VERSION ""

NS_ :

BS_:

BU_: VCM TBIOM RCIOM FCIOM CCIOM BPMU

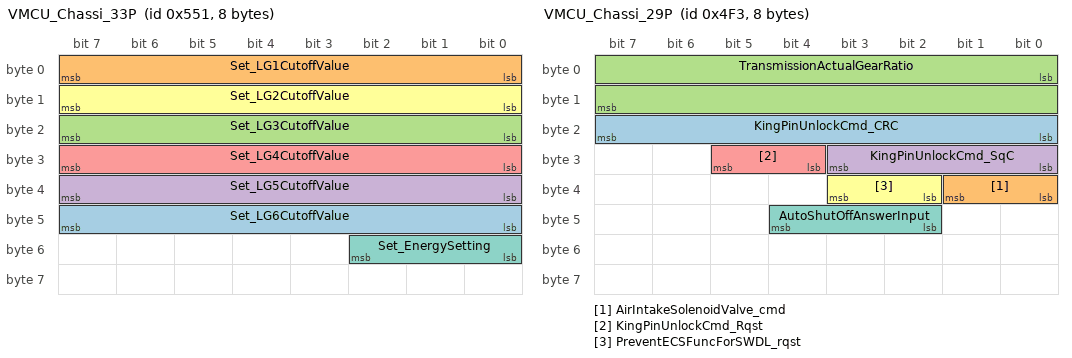
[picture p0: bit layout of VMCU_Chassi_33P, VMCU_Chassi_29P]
BO_ 1361 VMCU_Chassi_33P: 8 VCM
 SG_ Set_LG6CutoffValue : 40|8@1+ (1,0) [0|255] "Percent"  CCIOM
 SG_ Set_LG1CutoffValue : 0|8@1+ (1,0) [0|255] "Percent"  CCIOM
 SG_ Set_LG3CutoffValue : 16|8@1+ (1,0) [0|255] "Percent"  CCIOM
 SG_ Set_LG5CutoffValue : 32|8@1+ (1,0) [0|255] "Percent"  CCIOM
 SG_ Set_LG4CutoffValue : 24|8@1+ (1,0) [0|255] "Percent"  CCIOM
 SG_ Set_LG2CutoffValue : 8|8@1+ (1,0) [0|255] "Percent"  CCIOM
 SG_ Set_EnergySetting : 48|3@1+ (1,0) [0|0] ""  CCIOM

BO_ 1267 VMCU_Chassi_29P: 8 VCM
 SG_ KingPinUnlockCmd_CRC : 16|8@1+ (1,0) [0|255] ""  CCIOM
 SG_ AirIntakeSolenoidValve_cmd : 32|2@1+ (1,0) [0|0] ""  CCIOM
 SG_ TransmissionActualGearRatio : 0|16@1+ (0.001,0) [0|65.535] "NotApplicable"  RCIOM
 SG_ KingPinUnlockCmd_SqC : 24|4@1+ (1,0) [0|14] "NotApplicable"  CCIOM
 SG_ KingPinUnlockCmd_Rqst : 28|2@1+ (1,0) [0|0] ""  CCIOM
 SG_ PreventECSFuncForSWDL_rqst : 34|2@1+ (1,0) [0|0] ""  RCIOM
 SG_ AutoShutOffAnswerInput : 42|3@1+ (1,0) [0|0] ""  CCIOM

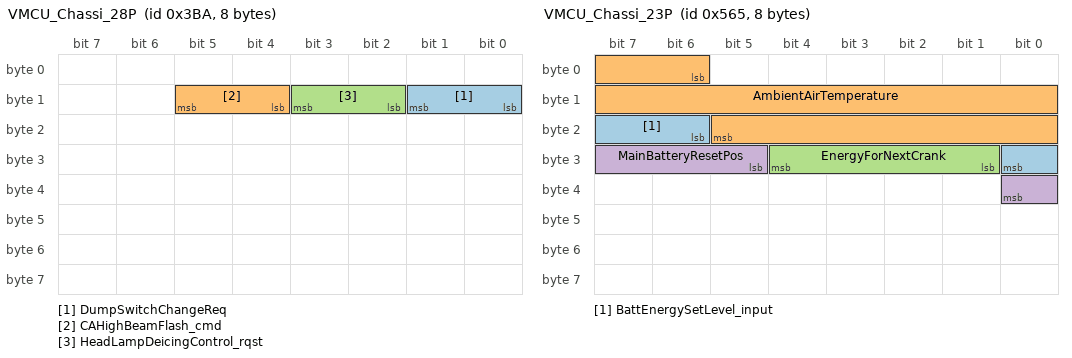
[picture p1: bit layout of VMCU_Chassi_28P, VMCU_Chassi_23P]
BO_ 954 VMCU_Chassi_28P: 8 VCM
 SG_ DumpSwitchChangeReq : 8|2@1+ (1,0) [0|0] ""  RCIOM
 SG_ CAHighBeamFlash_cmd : 12|2@1+ (1,0) [0|0] ""  FCIOM
 SG_ HeadLampDeicingControl_rqst : 10|2@1+ (1,0) [0|0] ""  FCIOM

BO_ 677 VMCU_Chassi_27P: 8 VCM
 SG_ EngineStarterMode : 0|4@1+ (1,0) [0|0] ""  CCIOM

BO_ 1363 VMCU_Chassi_26P: 8 VCM
 SG_ PredeliveryModeIndication_cmd : 56|2@1+ (1,0) [0|0] ""  CCIOM

BO_ 535 VMCU_Chassi_24P: 8 VCM
 SG_ DirectionIndicatorLightsStatus : 2|4@1+ (1,0) [0|0] ""  FCIOM,RCIOM
 SG_ HeadlightAngle_cmd : 56|8@1+ (0.025,-4) [-4|2.375] "deg"  FCIOM

BO_ 1381 VMCU_Chassi_23P: 8 VCM
 SG_ BattEnergySetLevel_input : 22|3@1+ (1,0) [0|0] ""  CCIOM
 SG_ AmbientAirTemperature : 6|16@1+ (0.03125,-273) [-273|1774.96875] "DegreeC"  FCIOM,BPMU,RCIOM,CCIOM
 SG_ EnergyForNextCrank : 25|4@1+ (1,0) [0|15] "Wh"  CCIOM
 SG_ MainBatteryResetPos : 29|4@1+ (1,0) [0|0] ""  CCIOM

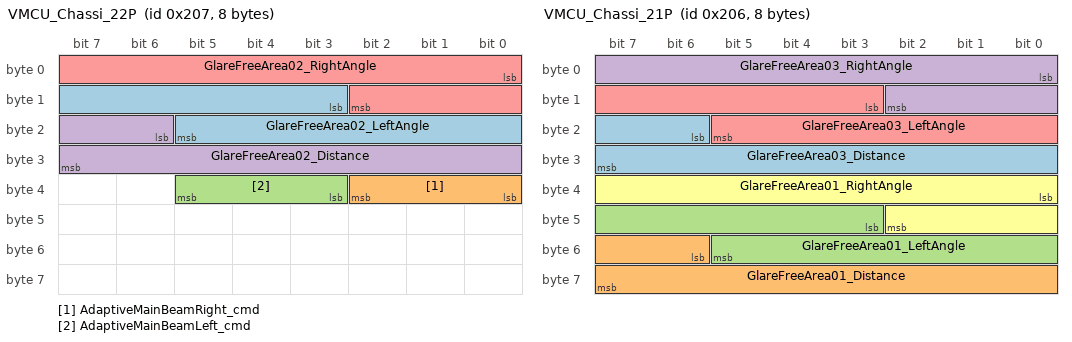
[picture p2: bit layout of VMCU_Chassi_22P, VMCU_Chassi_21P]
BO_ 519 VMCU_Chassi_22P: 8 VCM
 SG_ GlareFreeArea02_LeftAngle : 11|11@1+ (0.0494,-31.65) [-31.65|69.4718] "deg"  FCIOM
 SG_ AdaptiveMainBeamRight_cmd : 32|3@1+ (1,0) [0|0] ""  FCIOM
 SG_ AdaptiveMainBeamLeft_cmd : 35|3@1+ (1,0) [0|0] ""  FCIOM
 SG_ GlareFreeArea02_Distance : 22|10@1+ (0.5,0) [0|511.5] "m"  FCIOM
 SG_ GlareFreeArea02_RightAngle : 0|11@1+ (0.0494,-31.65) [-31.65|69.4718] "deg"  FCIOM

BO_ 518 VMCU_Chassi_21P: 8 VCM
 SG_ GlareFreeArea03_Distance : 22|10@1+ (0.5,0) [0|511.5] "m"  FCIOM
 SG_ GlareFreeArea01_Distance : 54|10@1+ (0.5,0) [0|511.5] "m"  FCIOM
 SG_ GlareFreeArea01_LeftAngle : 43|11@1+ (0.0494,-31.65) [-31.65|69.4718] "deg"  FCIOM
 SG_ GlareFreeArea03_RightAngle : 0|11@1+ (0.0494,-31.65) [-31.65|69.4718] "deg"  FCIOM
 SG_ GlareFreeArea03_LeftAngle : 11|11@1+ (0.0494,-31.65) [-31.65|69.4718] "deg"  FCIOM
 SG_ GlareFreeArea01_RightAngle : 32|11@1+ (0.0494,-31.65) [-31.65|69.4718] "deg"  FCIOM

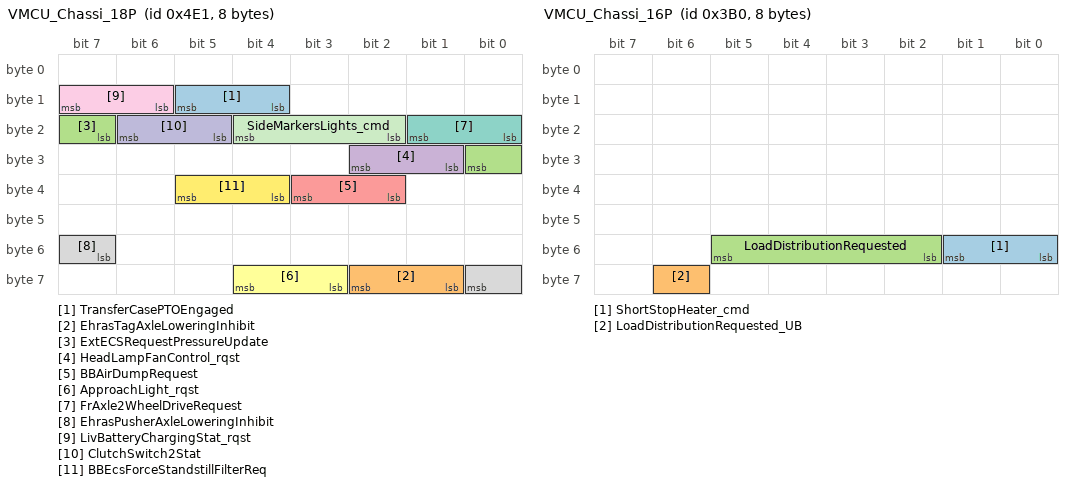
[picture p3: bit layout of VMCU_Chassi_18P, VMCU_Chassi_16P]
BO_ 1249 VMCU_Chassi_18P: 8 VCM
 SG_ TransferCasePTOEngaged : 12|2@1+ (1,0) [0|0] ""  RCIOM
 SG_ EhrasTagAxleLoweringInhibit : 57|2@1+ (1,0) [0|0] ""  RCIOM
 SG_ ExtECSRequestPressureUpdate : 23|2@1+ (1,0) [0|0] ""  RCIOM
 SG_ HeadLampFanControl_rqst : 25|2@1+ (1,0) [0|0] ""  FCIOM
 SG_ BBAirDumpRequest : 34|2@1+ (1,0) [0|0] ""  RCIOM
 SG_ ApproachLight_rqst : 59|2@1+ (1,0) [0|0] ""  RCIOM
 SG_ FrAxle2WheelDriveRequest : 16|2@1+ (1,0) [0|0] ""  CCIOM
 SG_ EhrasPusherAxleLoweringInhibit : 55|2@1+ (1,0) [0|0] ""  RCIOM
 SG_ LivBatteryChargingStat_rqst : 14|2@1+ (1,0) [0|0] ""  CCIOM
 SG_ ClutchSwitch2Stat : 21|2@1+ (1,0) [0|0] ""  CCIOM
 SG_ SideMarkersLights_cmd : 18|3@1+ (1,0) [0|0] ""  CCIOM
 SG_ BBEcsForceStandstillFilterReq : 36|2@1+ (1,0) [0|0] ""  RCIOM,CCIOM

BO_ 944 VMCU_Chassi_16P: 8 VCM
 SG_ ShortStopHeater_cmd : 48|2@1+ (1,0) [0|0] ""  CCIOM
 SG_ LoadDistributionRequested_UB : 62|1@1+ (1,0) [0|0] ""  RCIOM
 SG_ LoadDistributionRequested : 50|4@1+ (1,0) [0|0] ""  RCIOM

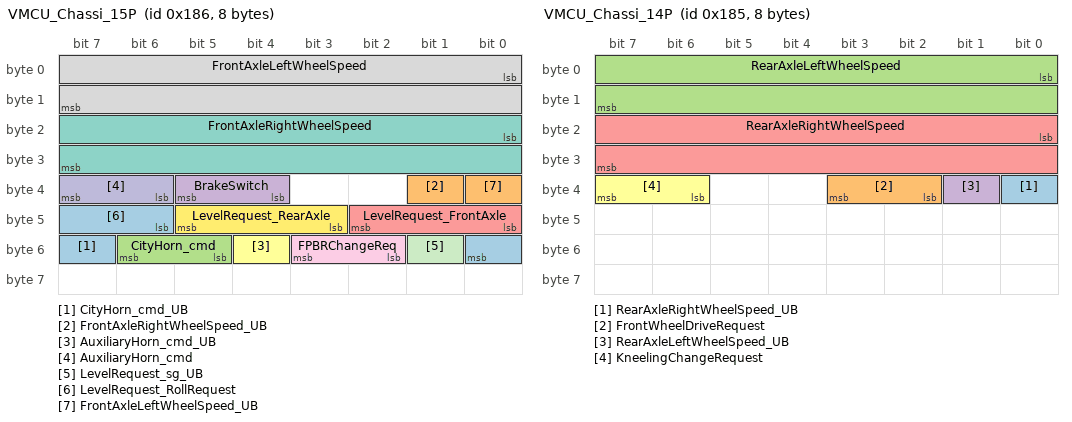
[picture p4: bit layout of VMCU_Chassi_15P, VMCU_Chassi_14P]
BO_ 390 VMCU_Chassi_15P: 8 VCM
 SG_ CityHorn_cmd_UB : 55|1@1+ (1,0) [0|0] ""  FCIOM
 SG_ FrontAxleRightWheelSpeed_UB : 33|1@1+ (1,0) [0|0] ""  CCIOM
 SG_ CityHorn_cmd : 53|2@1+ (1,0) [0|0] ""  FCIOM
 SG_ BrakeSwitch : 36|2@1+ (1,0) [0|0] ""  CCIOM
 SG_ LevelRequest_FrontAxle : 40|3@1+ (1,0) [0|0] ""  RCIOM
 SG_ AuxiliaryHorn_cmd_UB : 52|1@1+ (1,0) [0|0] ""  FCIOM
 SG_ FrontAxleRightWheelSpeed : 16|16@1+ (0.00390625,0) [0|255.99609375] "Km_per_h"  CCIOM
 SG_ FrontAxleLeftWheelSpeed : 0|16@1+ (0.00390625,0) [0|255.99609375] "Km_per_h"  CCIOM
 SG_ FPBRChangeReq : 50|2@1+ (1,0) [0|0] ""  RCIOM
 SG_ AuxiliaryHorn_cmd : 38|2@1+ (1,0) [0|0] ""  FCIOM
 SG_ LevelRequest_sg_UB : 49|1@1+ (1,0) [0|0] ""  RCIOM
 SG_ LevelRequest_RearAxle : 43|3@1+ (1,0) [0|0] ""  RCIOM
 SG_ LevelRequest_RollRequest : 46|3@1+ (1,0) [0|0] ""  RCIOM
 SG_ FrontAxleLeftWheelSpeed_UB : 32|1@1+ (1,0) [0|0] ""  CCIOM

BO_ 389 VMCU_Chassi_14P: 8 VCM
 SG_ RearAxleRightWheelSpeed_UB : 32|1@1+ (1,0) [0|0] ""  CCIOM,RCIOM
 SG_ FrontWheelDriveRequest : 34|2@1+ (1,0) [0|0] ""  CCIOM
 SG_ RearAxleLeftWheelSpeed : 0|16@1+ (0.00390625,0) [0|255.99609375] "Km_per_h"  RCIOM,CCIOM
 SG_ RearAxleLeftWheelSpeed_UB : 33|1@1+ (1,0) [0|0] ""  CCIOM,RCIOM
 SG_ RearAxleRightWheelSpeed : 16|16@1+ (0.00390625,0) [0|255.99609375] "Km_per_h"  RCIOM,CCIOM
 SG_ KneelingChangeRequest : 38|2@1+ (1,0) [0|0] ""  RCIOM

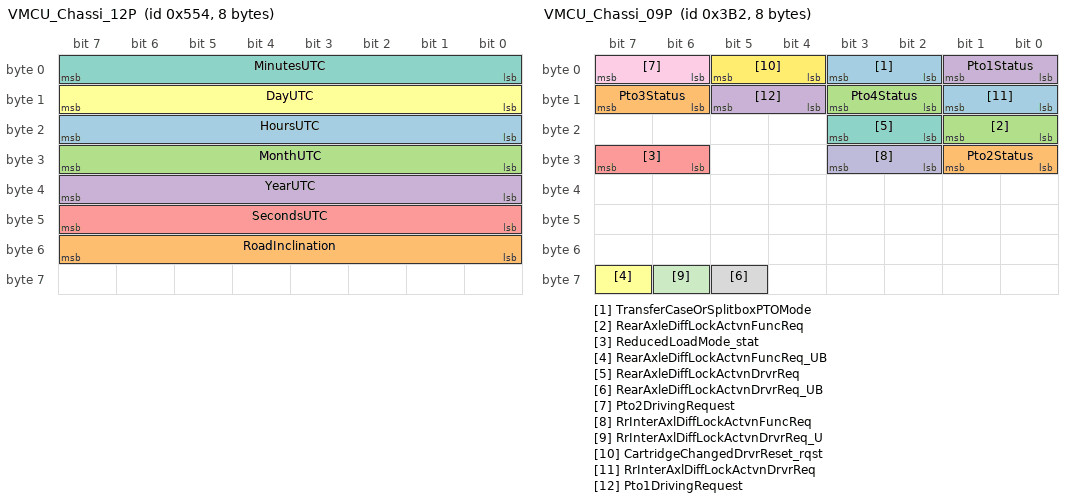
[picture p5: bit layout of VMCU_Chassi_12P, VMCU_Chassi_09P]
BO_ 1364 VMCU_Chassi_12P: 8 VCM
 SG_ HoursUTC : 16|8@1+ (1,0) [0|255] "h"  FCIOM,RCIOM,CCIOM,BPMU
 SG_ RoadInclination : 48|8@1+ (0.2,-25) [-25|26] "Percent"  RCIOM
 SG_ MonthUTC : 24|8@1+ (1,0) [0|255] "Months"  BPMU,RCIOM,FCIOM,CCIOM
 SG_ YearUTC : 32|8@1+ (1,1985) [1985|2240] "Years"  CCIOM,FCIOM,RCIOM,BPMU
 SG_ SecondsUTC : 40|8@1+ (0.25,0) [0|63.75] "s"  RCIOM,FCIOM,BPMU,CCIOM
 SG_ DayUTC : 8|8@1+ (0.25,0) [0|63.75] "Days"  RCIOM,CCIOM,FCIOM,BPMU
 SG_ MinutesUTC : 0|8@1+ (1,0) [0|255] "min"  BPMU,CCIOM,RCIOM,FCIOM

BO_ 826 VMCU_Chassi_11P: 8 VCM
 SG_ BBContUnlockCmd : 12|2@1+ (1,0) [0|0] ""  CCIOM
 SG_ LampCheck_cmd : 46|2@1+ (1,0) [0|0] ""  FCIOM
 SG_ LampCheck_rqst : 51|2@1+ (1,0) [0|0] ""  RCIOM
 SG_ BatteryCapacity : 16|4@1+ (1,0) [0|0] ""  CCIOM
 SG_ AreaInhibit : 10|2@1+ (1,0) [0|0] ""  CCIOM
 SG_ LEDAnimation_cmd : 53|3@1+ (1,0) [0|0] ""  FCIOM
 SG_ ActualDrvlnRetdrPercentTorque : 24|8@1+ (1,-125) [-125|130] "Percent"  RCIOM
 SG_ PloughLampModeStatus : 56|2@1+ (1,0) [0|0] ""  FCIOM
 SG_ RangeInhibit : 14|2@1+ (1,0) [0|0] ""  CCIOM
 SG_ TrailerBrakeNoEbs_stat : 22|2@1+ (1,0) [0|0] ""  RCIOM
 SG_ LiftAxle1DirectControl : 60|3@1+ (1,0) [0|0] ""  RCIOM
 SG_ DoorsAjar_stat : 43|3@1+ (1,0) [0|0] ""  CCIOM
 SG_ BlackOutandConvoyMode_rqst : 40|3@1+ (1,0) [0|0] ""  RCIOM,CCIOM
 SG_ DoorsAjar_stat_UB : 7|1@1+ (1,0) [0|0] ""  CCIOM
 SG_ LiftAxle1DirectControl_UB : 63|1@1+ (1,0) [0|0] ""  RCIOM
 SG_ ECSStandByRequest : 48|3@1+ (1,0) [0|0] ""  RCIOM
 SG_ ChassisInstepLight_cmd : 8|2@1+ (1,0) [0|0] ""  FCIOM
 SG_ BBSlidable5thWheelCmd : 1|2@1+ (1,0) [0|0] ""  CCIOM
 SG_ ParkingBrake_stat : 58|2@1+ (1,0) [0|0] ""  CCIOM
 SG_ MaintBatteryReset : 20|2@1+ (1,0) [0|0] ""  CCIOM

BO_ 1369 VMCU_Chassi_10P: 8 VCM
 SG_ TotalVehicleDistanceHighRes : 32|32@1+ (5,0) [0|21474836475] "m"  RCIOM,CCIOM,FCIOM,BPMU

BO_ 946 VMCU_Chassi_09P: 8 VCM
 SG_ TransferCaseOrSplitboxPTOMode : 2|2@1+ (1,0) [0|0] ""  RCIOM
 SG_ Pto3Status : 14|2@1+ (1,0) [0|0] ""  RCIOM
 SG_ RearAxleDiffLockActvnFuncReq : 16|2@1+ (1,0) [0|0] ""  RCIOM
 SG_ Pto1Status : 0|2@1+ (1,0) [0|0] ""  RCIOM
 SG_ ReducedLoadMode_stat : 30|2@1+ (1,0) [0|0] ""  CCIOM
 SG_ RearAxleDiffLockActvnFuncReq_UB : 63|1@1+ (1,0) [0|0] ""  RCIOM
 SG_ RearAxleDiffLockActvnDrvrReq : 18|2@1+ (1,0) [0|0] ""  RCIOM
 SG_ RearAxleDiffLockActvnDrvrReq_UB : 61|1@1+ (1,0) [0|0] ""  RCIOM
 SG_ Pto2DrivingRequest : 6|2@1+ (1,0) [0|0] ""  CCIOM
 SG_ RrInterAxlDiffLockActvnFuncReq : 26|2@1+ (1,0) [0|0] ""  RCIOM
 SG_ RrInterAxlDiffLockActvnDrvrReq_U : 62|1@1+ (1,0) [0|0] ""  RCIOM
 SG_ CartridgeChangedDrvrReset_rqst : 4|2@1+ (1,0) [0|0] ""  CCIOM
 SG_ RrInterAxlDiffLockActvnDrvrReq : 8|2@1+ (1,0) [0|0] ""  RCIOM
 SG_ Pto2Status : 24|2@1+ (1,0) [0|0] ""  RCIOM
 SG_ Pto4Status : 10|2@1+ (1,0) [0|0] ""  RCIOM
 SG_ Pto1DrivingRequest : 12|2@1+ (1,0) [0|0] ""  CCIOM

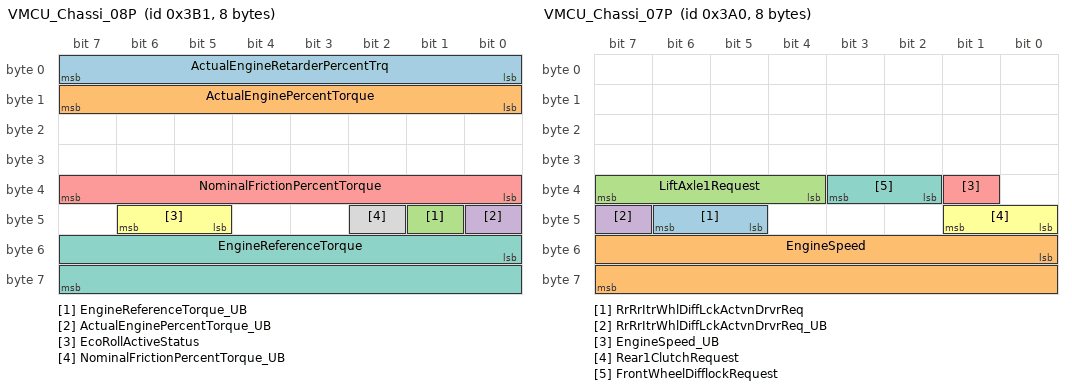
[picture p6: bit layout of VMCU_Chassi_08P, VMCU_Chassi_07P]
BO_ 945 VMCU_Chassi_08P: 8 VCM
 SG_ ActualEngineRetarderPercentTrq : 0|8@1+ (1,-125) [-125|130] "Percent"  RCIOM
 SG_ ActualEnginePercentTorque : 8|8@1+ (1,-125) [-125|130] "Percent"  CCIOM,RCIOM
 SG_ EngineReferenceTorque_UB : 41|1@1+ (1,0) [0|0] ""  RCIOM
 SG_ ActualEnginePercentTorque_UB : 40|1@1+ (1,0) [0|0] ""  RCIOM,CCIOM
 SG_ NominalFrictionPercentTorque : 32|8@1+ (1,-125) [-125|130] "Percent"  RCIOM
 SG_ EcoRollActiveStatus : 45|2@1+ (1,0) [0|0] ""  CCIOM
 SG_ EngineReferenceTorque : 48|16@1+ (1,0) [0|65535] "Nm"  RCIOM
 SG_ NominalFrictionPercentTorque_UB : 42|1@1+ (1,0) [0|0] ""  RCIOM

BO_ 928 VMCU_Chassi_07P: 8 VCM
 SG_ RrRrItrWhlDiffLckActvnDrvrReq : 45|2@1+ (1,0) [0|0] ""  RCIOM
 SG_ EngineSpeed : 48|16@1+ (0.125,0) [0|8191.875] "rpm"  CCIOM
 SG_ LiftAxle1Request : 36|4@1+ (1,0) [0|0] ""  RCIOM
 SG_ RrRrItrWhlDiffLckActvnDrvrReq_UB : 47|1@1+ (1,0) [0|0] ""  RCIOM
 SG_ EngineSpeed_UB : 33|1@1+ (1,0) [0|0] ""  CCIOM
 SG_ Rear1ClutchRequest : 40|2@1+ (1,0) [0|0] ""  RCIOM
 SG_ FrontWheelDifflockRequest : 34|2@1+ (1,0) [0|0] ""  CCIOM

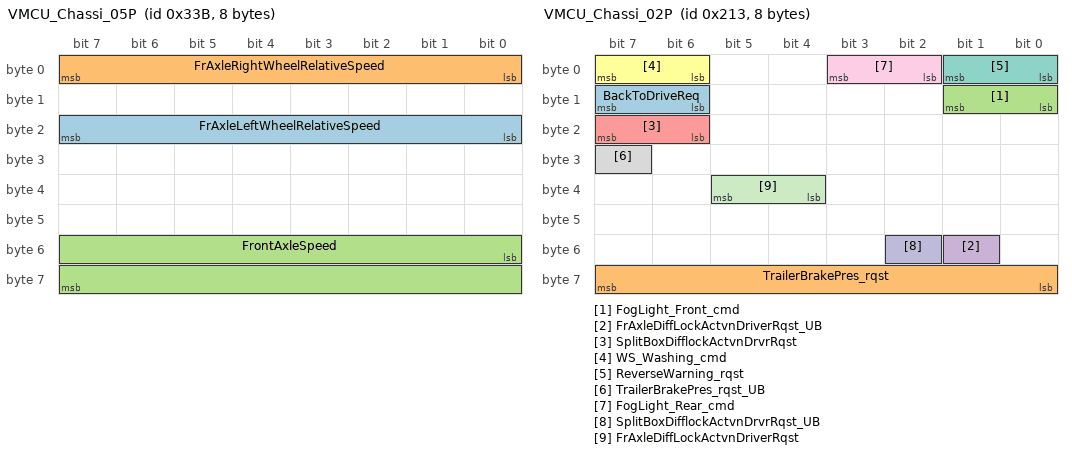
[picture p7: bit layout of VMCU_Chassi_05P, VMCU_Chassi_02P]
BO_ 827 VMCU_Chassi_05P: 8 VCM
 SG_ FrAxleLeftWheelRelativeSpeed : 16|8@1+ (0.0625,-7.8125) [-7.8125|8.125] "Km_per_h"  RCIOM
 SG_ FrAxleRightWheelRelativeSpeed : 0|8@1+ (0.0625,-7.8125) [-7.8125|8.125] "Km_per_h"  RCIOM
 SG_ FrontAxleSpeed : 48|16@1+ (0.00390625,0) [0|255.99609375] "Km_per_h"  RCIOM,CCIOM

BO_ 537 VMCU_Chassi_04P: 8 VCM
 SG_ LiftAxle2LiftPositionRequest : 43|3@1+ (1,0) [0|0] ""  RCIOM
 SG_ LoadDistributionChangeRequest : 48|2@1+ (1,0) [0|0] ""  RCIOM
 SG_ AltLoadDistribution_rqst : 56|3@1+ (1,0) [0|0] ""  RCIOM
 SG_ LiftAxle1LiftPositionRequest : 36|3@1+ (1,0) [0|0] ""  RCIOM
 SG_ FerryFunctionRequest_UB : 10|1@1+ (1,0) [0|0] ""  RCIOM
 SG_ RampLevelRequest : 0|4@1+ (1,0) [0|0] ""  RCIOM
 SG_ RampLevelStorageRequest : 16|4@1+ (1,0) [0|0] ""  RCIOM
 SG_ RideHeightFunctionRequest : 12|4@1+ (1,0) [0|0] ""  RCIOM
 SG_ LiftAxle1AutoLiftRequest : 34|2@1+ (1,0) [0|0] ""  RCIOM
 SG_ FerryFunctionRequest : 28|2@1+ (1,0) [0|0] ""  RCIOM
 SG_ AltLoadDistribution_rqst_UB : 54|1@1+ (1,0) [0|0] ""  RCIOM
 SG_ BBSystemKneelRequest : 8|2@1+ (1,0) [0|0] ""  RCIOM
 SG_ StopLevelChangeRequest : 24|2@1+ (1,0) [0|0] ""  RCIOM
 SG_ LiftAxle1LiftPositionRequest_UB : 39|1@1+ (1,0) [0|0] ""  RCIOM
 SG_ LiftAxle2LiftPositionRequest_UB : 46|1@1+ (1,0) [0|0] ""  RCIOM
 SG_ FirstAxleLowerPrioRequested : 50|3@1+ (1,0) [0|0] ""  RCIOM
 SG_ LiftAxle1AutoLiftRequest_UB : 23|1@1+ (1,0) [0|0] ""  RCIOM
 SG_ LiftAxle2AutoLiftRequest : 40|2@1+ (1,0) [0|0] ""  RCIOM
 SG_ LiftAxle2AutoLiftRequest_UB : 42|1@1+ (1,0) [0|0] ""  RCIOM
 SG_ FerryFunctionSwitchChangeReq : 61|2@1+ (1,0) [0|0] ""  RCIOM
 SG_ LevelStrokeRequest : 32|2@1+ (1,0) [0|0] ""  RCIOM
 SG_ BBSystemAlternatLoadDistribReq_U : 55|1@1+ (1,0) [0|0] ""  RCIOM
 SG_ RideHeightFunctionRequest_UB : 63|1@1+ (1,0) [0|0] ""  RCIOM
 SG_ FirstAxleLowerPrioRequested_UB : 53|1@1+ (1,0) [0|0] ""  RCIOM
 SG_ BBSystemProhibitControlRequest : 30|2@1+ (1,0) [0|0] ""  RCIOM
 SG_ LoadDistributionChangeRequest_UB : 47|1@1+ (1,0) [0|0] ""  RCIOM
 SG_ BBSystemAlternatLoadDistribReq : 59|2@1+ (1,0) [0|0] ""  RCIOM
 SG_ RideHeightStorageRequest : 4|4@1+ (1,0) [0|0] ""  RCIOM
 SG_ BBSystemSpeedDepDriveLevelReq : 26|2@1+ (1,0) [0|0] ""  RCIOM

BO_ 531 VMCU_Chassi_02P: 8 VCM
 SG_ BackToDriveReq : 14|2@1+ (1,0) [0|0] ""  RCIOM
 SG_ TrailerBrakePres_rqst : 56|8@1+ (8,0) [0|2040] "kPa"  CCIOM
 SG_ FogLight_Front_cmd : 8|2@1+ (1,0) [0|0] ""  FCIOM
 SG_ FrAxleDiffLockActvnDriverRqst_UB : 49|1@1+ (1,0) [0|0] ""  CCIOM
 SG_ SplitBoxDifflockActvnDrvrRqst : 22|2@1+ (1,0) [0|0] ""  CCIOM
 SG_ WS_Washing_cmd : 6|2@1+ (1,0) [0|0] ""  FCIOM
 SG_ ReverseWarning_rqst : 0|2@1+ (1,0) [0|0] ""  RCIOM
 SG_ TrailerBrakePres_rqst_UB : 31|1@1+ (1,0) [0|0] ""  CCIOM
 SG_ FogLight_Rear_cmd : 2|2@1+ (1,0) [0|0] ""  RCIOM,CCIOM
 SG_ SplitBoxDifflockActvnDrvrRqst_UB : 50|1@1+ (1,0) [0|0] ""  CCIOM
 SG_ FrAxleDiffLockActvnDriverRqst : 36|2@1+ (1,0) [0|0] ""  CCIOM

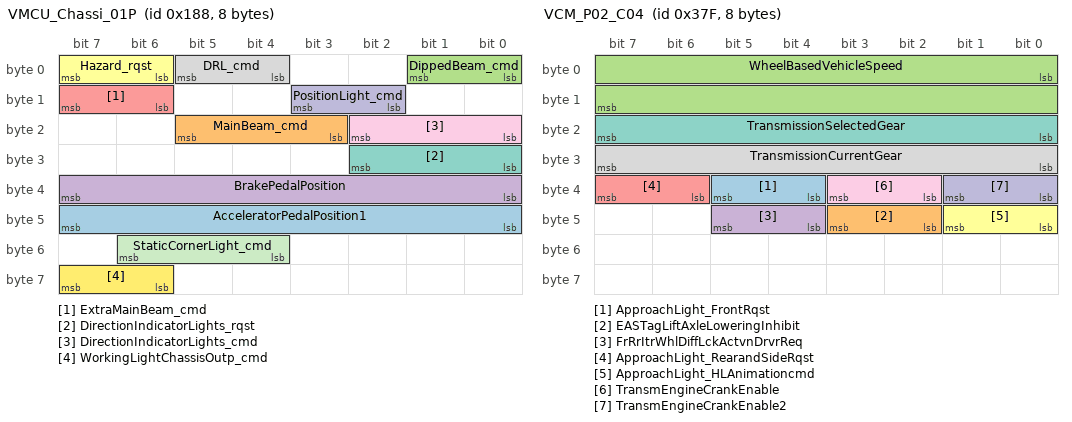
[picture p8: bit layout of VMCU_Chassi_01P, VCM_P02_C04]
BO_ 392 VMCU_Chassi_01P: 8 VCM
 SG_ AcceleratorPedalPosition1 : 40|8@1+ (0.4,0) [0|102] "Percent"  RCIOM,CCIOM
 SG_ MainBeam_cmd : 19|3@1+ (1,0) [0|0] ""  FCIOM,RCIOM
 SG_ DippedBeam_cmd : 0|2@1+ (1,0) [0|0] ""  FCIOM,RCIOM
 SG_ BrakePedalPosition : 32|8@1+ (0.4,0) [0|102] "Percent"  RCIOM,CCIOM
 SG_ ExtraMainBeam_cmd : 14|2@1+ (1,0) [0|0] ""  FCIOM
 SG_ Hazard_rqst : 6|2@1+ (1,0) [0|0] ""  FCIOM
 SG_ DirectionIndicatorLights_rqst : 24|3@1+ (1,0) [0|0] ""  FCIOM
 SG_ DRL_cmd : 4|2@1+ (1,0) [0|0] ""  FCIOM,RCIOM
 SG_ DirectionIndicatorLights_cmd : 16|3@1+ (1,0) [0|0] ""  FCIOM,RCIOM,CCIOM
 SG_ PositionLight_cmd : 10|2@1+ (1,0) [0|0] ""  FCIOM,RCIOM
 SG_ StaticCornerLight_cmd : 52|3@1+ (1,0) [0|0] ""  FCIOM
 SG_ WorkingLightChassisOutp_cmd : 62|2@1+ (1,0) [0|0] ""  CCIOM

BO_ 895 VCM_P02_C04: 8 VCM
 SG_ ApproachLight_FrontRqst : 36|2@1+ (1,0) [0|0] ""  FCIOM
 SG_ EASTagLiftAxleLoweringInhibit : 42|2@1+ (1,0) [0|0] ""  RCIOM
 SG_ WheelBasedVehicleSpeed : 0|16@1+ (0.00390625,0) [0|255.99609375] "Km_per_h"  RCIOM,CCIOM
 SG_ FrRrItrWhlDiffLckActvnDrvrReq : 44|2@1+ (1,0) [0|0] ""  RCIOM
 SG_ ApproachLight_RearandSideRqst : 38|2@1+ (1,0) [0|0] ""  RCIOM
 SG_ ApproachLight_HLAnimationcmd : 40|2@1+ (1,0) [0|0] ""  FCIOM
 SG_ TransmissionSelectedGear : 16|8@1+ (1,-125) [-125|130] "GearValue"  CCIOM
 SG_ TransmissionCurrentGear : 24|8@1+ (1,-125) [-125|130] "GearValue"  CCIOM
 SG_ TransmEngineCrankEnable : 34|2@1+ (1,0) [0|0] ""  CCIOM
 SG_ TransmEngineCrankEnable2 : 32|2@1+ (1,0) [0|0] ""  CCIOM

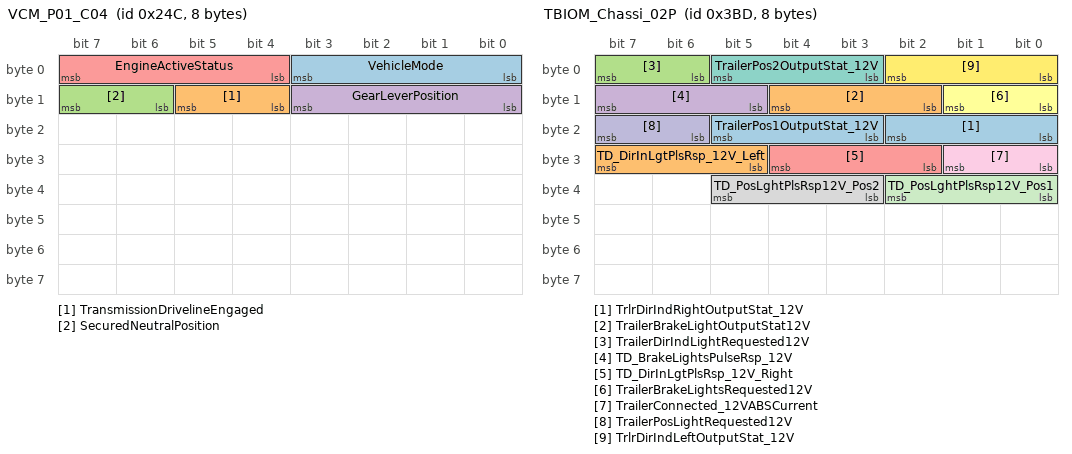
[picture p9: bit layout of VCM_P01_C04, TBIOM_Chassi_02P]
BO_ 588 VCM_P01_C04: 8 VCM
 SG_ VehicleMode : 0|4@1+ (1,0) [0|0] ""  CCIOM,BPMU,TBIOM,FCIOM,RCIOM
 SG_ TransmissionDrivelineEngaged : 12|2@1+ (1,0) [0|0] ""  CCIOM
 SG_ SecuredNeutralPosition : 14|2@1+ (1,0) [0|0] ""  CCIOM
 SG_ GearLeverPosition : 8|4@1+ (1,0) [0|0] ""  CCIOM
 SG_ EngineActiveStatus : 4|4@1+ (1,0) [0|0] ""  CCIOM

BO_ 2671902706 TesterFuncDiagMsg_C04: 8 VCM
 SG_ FuncDiagDataTester : 0|64@1+ (1,0) [0|0] ""  TBIOM,RCIOM,FCIOM,CCIOM,BPMU

BO_ 2671902708 TesterFuncDiagMsgF4_C04: 8 VCM
 SG_ FuncDiagDataIntTesterF4 : 0|64@1+ (1,0) [0|0] ""  FCIOM,BPMU,RCIOM,CCIOM,TBIOM

BO_ 957 TBIOM_Chassi_02P: 8 VCM
 SG_ TrlrDirIndRightOutputStat_12V : 16|3@1+ (1,0) [0|0] ""  RCIOM
 SG_ TrailerBrakeLightOutputStat12V : 10|3@1+ (1,0) [0|0] ""  RCIOM
 SG_ TrailerDirIndLightRequested12V : 6|2@1+ (1,0) [0|0] ""  RCIOM
 SG_ TD_BrakeLightsPulseRsp_12V : 13|3@1+ (1,0) [0|0] ""  RCIOM
 SG_ TD_DirInLgtPlsRsp_12V_Right : 26|3@1+ (1,0) [0|0] ""  RCIOM
 SG_ TrailerBrakeLightsRequested12V : 8|2@1+ (1,0) [0|0] ""  RCIOM
 SG_ TrailerPos2OutputStat_12V : 3|3@1+ (1,0) [0|0] ""  RCIOM
 SG_ TD_PosLghtPlsRsp12V_Pos2 : 35|3@1+ (1,0) [0|0] ""  RCIOM
 SG_ TrailerConnected_12VABSCurrent : 24|2@1+ (1,0) [0|0] ""  RCIOM
 SG_ TrailerPosLightRequested12V : 22|2@1+ (1,0) [0|0] ""  RCIOM
 SG_ TD_PosLghtPlsRsp12V_Pos1 : 32|3@1+ (1,0) [0|0] ""  RCIOM
 SG_ TrlrDirIndLeftOutputStat_12V : 0|3@1+ (1,0) [0|0] ""  RCIOM
 SG_ TrailerPos1OutputStat_12V : 19|3@1+ (1,0) [0|0] ""  RCIOM
 SG_ TD_DirInLgtPlsRsp_12V_Left : 29|3@1+ (1,0) [0|0] ""  RCIOM

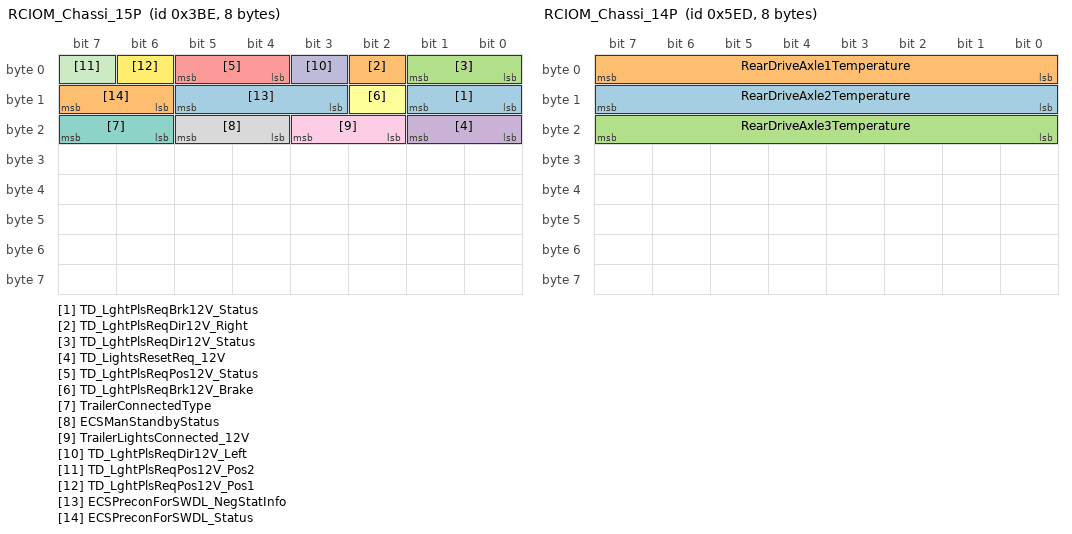
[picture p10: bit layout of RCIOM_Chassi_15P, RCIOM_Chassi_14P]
BO_ 958 RCIOM_Chassi_15P: 8 RCIOM
 SG_ TD_LghtPlsReqBrk12V_Status : 8|2@1+ (1,0) [0|0] ""  VCM
 SG_ TD_LghtPlsReqDir12V_Right : 2|1@1+ (1,0) [0|0] ""  VCM
 SG_ TD_LghtPlsReqDir12V_Status : 0|2@1+ (1,0) [0|0] ""  VCM
 SG_ TD_LightsResetReq_12V : 16|2@1+ (1,0) [0|0] ""  VCM
 SG_ TD_LghtPlsReqPos12V_Status : 4|2@1+ (1,0) [0|0] ""  VCM
 SG_ TD_LghtPlsReqBrk12V_Brake : 10|1@1+ (1,0) [0|0] ""  VCM
 SG_ TrailerConnectedType : 22|2@1+ (1,0) [0|0] ""  VCM,CCIOM
 SG_ ECSManStandbyStatus : 20|2@1+ (1,0) [0|0] ""  VCM
 SG_ TrailerLightsConnected_12V : 18|2@1+ (1,0) [0|0] ""  VCM
 SG_ TD_LghtPlsReqDir12V_Left : 3|1@1+ (1,0) [0|0] ""  VCM
 SG_ TD_LghtPlsReqPos12V_Pos2 : 7|1@1+ (1,0) [0|0] ""  VCM
 SG_ TD_LghtPlsReqPos12V_Pos1 : 6|1@1+ (1,0) [0|0] ""  VCM
 SG_ ECSPreconForSWDL_NegStatInfo : 11|3@1+ (1,0) [0|0] ""  VCM
 SG_ ECSPreconForSWDL_Status : 14|2@1+ (1,0) [0|0] ""  VCM

BO_ 1517 RCIOM_Chassi_14P: 8 RCIOM
 SG_ RearDriveAxle2Temperature : 8|8@1+ (1,0) [0|255] "DegreeC"  VCM
 SG_ RearDriveAxle1Temperature : 0|8@1+ (1,0) [0|255] "DegreeC"  VCM
 SG_ RearDriveAxle3Temperature : 16|8@1+ (1,0) [0|255] "DegreeC"  VCM

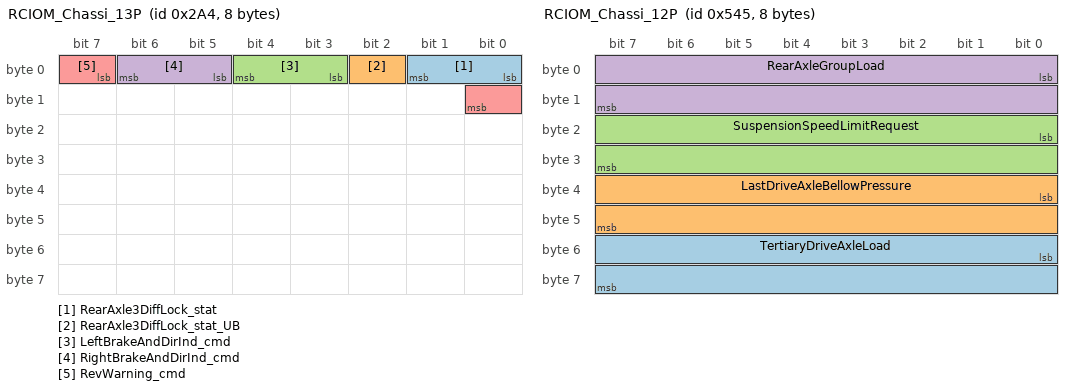
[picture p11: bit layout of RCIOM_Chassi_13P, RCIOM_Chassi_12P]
BO_ 676 RCIOM_Chassi_13P: 8 RCIOM
 SG_ RearAxle3DiffLock_stat : 0|2@1+ (1,0) [0|0] ""  VCM
 SG_ RearAxle3DiffLock_stat_UB : 2|1@1+ (1,0) [0|0] ""  VCM
 SG_ LeftBrakeAndDirInd_cmd : 3|2@1+ (1,0) [0|0] ""  VCM
 SG_ RightBrakeAndDirInd_cmd : 5|2@1+ (1,0) [0|0] ""  VCM
 SG_ RevWarning_cmd : 7|2@1+ (1,0) [0|0] ""  VCM

BO_ 1349 RCIOM_Chassi_12P: 8 RCIOM
 SG_ TertiaryDriveAxleLoad : 48|16@1+ (0.5,0) [0|32767.5] "kg"  VCM
 SG_ LastDriveAxleBellowPressure : 32|16@1+ (0.1,0) [0|6553.5] "kPa"  VCM
 SG_ SuspensionSpeedLimitRequest : 16|16@1+ (0.00390625,0) [0|255.99609375] "Km_per_h"  VCM
 SG_ RearAxleGroupLoad : 0|16@1+ (2,0) [0|131070] "kg"  VCM

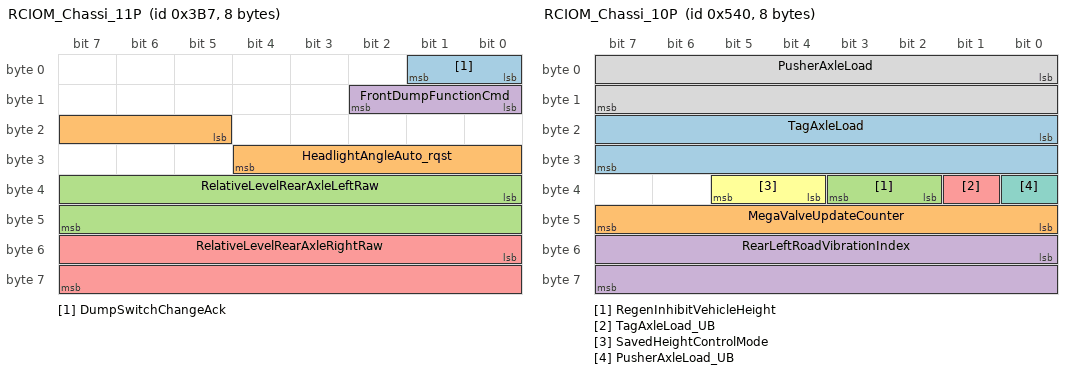
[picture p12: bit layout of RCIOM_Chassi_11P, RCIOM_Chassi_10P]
BO_ 951 RCIOM_Chassi_11P: 8 RCIOM
 SG_ DumpSwitchChangeAck : 0|2@1+ (1,0) [0|0] ""  VCM
 SG_ HeadlightAngleAuto_rqst : 21|8@1+ (0.025,-4) [-4|2.375] "deg"  VCM
 SG_ RelativeLevelRearAxleLeftRaw : 32|16@1+ (0.1,-3200) [-3200|3353.5] "mm"  VCM
 SG_ FrontDumpFunctionCmd : 8|3@1+ (1,0) [0|0] ""  VCM,CCIOM
 SG_ RelativeLevelRearAxleRightRaw : 48|16@1+ (0.1,-3200) [-3200|3353.5] "mm"  VCM

BO_ 1344 RCIOM_Chassi_10P: 8 RCIOM
 SG_ TagAxleLoad : 16|16@1+ (0.5,0) [0|32767.5] "kg"  VCM
 SG_ MegaValveUpdateCounter : 40|8@1+ (1,0) [0|255] "Count"  VCM
 SG_ RegenInhibitVehicleHeight : 34|2@1+ (1,0) [0|0] ""  VCM
 SG_ RearLeftRoadVibrationIndex : 48|16@1+ (0.01,0) [0|655.35] ""  VCM
 SG_ TagAxleLoad_UB : 33|1@1+ (1,0) [0|0] ""  VCM
 SG_ SavedHeightControlMode : 36|2@1+ (1,0) [0|0] ""  VCM
 SG_ PusherAxleLoad_UB : 32|1@1+ (1,0) [0|0] ""  VCM
 SG_ PusherAxleLoad : 0|16@1+ (0.5,0) [0|32767.5] "kg"  VCM

CM_ "COM_MATRIX_T3_1.9.0";
CM_ BU_ VCM "Vehicle Control Module";
CM_ BU_ TBIOM "Trailer Body Input Output Module";
CM_ BU_ RCIOM "Rear Chassis Input Output Module";
CM_ BU_ FCIOM "Front Chassis Input Output Module";
CM_ BU_ CCIOM "Center Chassis Input Output Module";
CM_ BU_ BPMU "Battery Power Management Unit";
CM_ BO_ 519 "Sporadic defined on this net, but periodic in reality since triggered every 20ms due to cyclic on BB2";
CM_ BO_ 518 "Sporadic defined on this net, but periodic in reality since triggered every 20ms due to cyclic on BB2";
CM_ BO_ 827 "This is a sporadic message but this message comes periodically because all signal in the message are gatewayed signals from BB1 and they are periodical there. If there is no traffic on BB1 this message is not sent on Chassi network.";
BA_DEF_ BO_  "GenMsgStartDelayTime" INT 0 0;
BA_DEF_ BO_  "GenMsgDelayTime" INT 0 0;
BA_DEF_ BO_  "GenMsgCycleTime" INT 0 0;
BA_DEF_ BO_  "GenMsgSendType" ENUM  "Cyclic","NotUsed","NotUsed","NotUsed","NotUsed","NotUsed","NotUsed","IfActive","NoMsgSendType","NotUsed";
BA_DEF_ SG_  "GenSigStartValue" INT 0 0;
BA_DEF_ SG_  "GenSigInactiveValue" INT 0 0;
BA_DEF_ SG_  "GenSigCycleTimeActive" INT 0 0;
BA_DEF_ SG_  "GenSigCycleTime" INT 0 0;
BA_DEF_ SG_  "GenSigSendType" ENUM  "Cyclic","OnWrite","OnWriteWithRepetition","OnChange","OnChangeWithRepetition","IfActive","IfActiveWithRepetition","NoSigSendType","NotUsed","NotUsed","NotUsed","NotUsed","NotUsed";
BA_DEF_  "Baudrate" INT 0 1000000;
BA_DEF_  "NmType" STRING ;
BA_DEF_  "Manufacturer" STRING ;
BA_DEF_  "VersionYear" INT 0 99;
BA_DEF_  "VersionNumber" INT 0 99;
BA_DEF_  "VersionMonth" INT 1 12;
BA_DEF_  "VersionDay" INT 1 31;
BA_DEF_ BO_  "VFrameFormat" ENUM  "StandardCAN","ExtendedCAN","reserved","J1939PG","reserved","reserved","reserved","reserved","reserved","reserved","reserved","reserved","reserved","reserved","StandardCAN_FD","ExtendedCAN_FD";
BA_DEF_ BU_  "TpOwnSystemEcuNumber" HEX 0 255;
BA_DEF_ SG_  "SigType" ENUM  "Default","Range","RangeSigned","ASCII","Discrete","Control","ReferencePGN","DTC","StringDelimiter","StringLength","StringLengthControl";
BA_DEF_ SG_  "Platform_Vivis2_Sig" ENUM  "No","Yes";
BA_DEF_ SG_  "Platform_VMCU1_Sig" ENUM  "No","Yes";
BA_DEF_ BU_  "NmStationAddress" INT 0 255;
BA_DEF_  "NmAsrWaitBusSleepTime" INT 0 65535;
BA_DEF_  "NmAsrTimeoutTime" INT 0 65535;
BA_DEF_  "NmAsrRepeatMessageTime" INT 0 65535;
BA_DEF_ BU_  "NmAsrNodeIdentifier" HEX 0 253;
BA_DEF_ BU_  "NmAsrNode" ENUM  "No","Yes";
BA_DEF_  "NmAsrMessageCount" INT 1 256;
BA_DEF_ BO_  "NmAsrMessage" ENUM  "No","Yes";
BA_DEF_  "NmAsrCanMsgCycleTime" INT 0 65535;
BA_DEF_  "NmAsrBaseAddress" HEX 0 536870911;
BA_DEF_ SG_  "NeedsUpdateBit" ENUM  "No","Yes";
BA_DEF_ SG_  "MmAnSignal" ENUM  "No","Yes";
BA_DEF_ BU_  "IsOBDrelevant" ENUM  "No","Yes";
BA_DEF_ SG_  "GenSigMaxLatency" INT 0 65535;
BA_DEF_ SG_  "GenSigILSupport" ENUM  "Yes","No";
BA_DEF_ BO_  "GenMsgILSupport" ENUM  "No","Yes";
BA_DEF_ SG_  "E2EProfile" STRING ;
BA_DEF_  "E2EP05WindowSize" INT 0 65535;
BA_DEF_  "E2EP05ProfileName" STRING ;
BA_DEF_  "E2EP05MinOkStateValid" INT 0 65535;
BA_DEF_  "E2EP05MinOkStateInvalid" INT 0 65535;
BA_DEF_  "E2EP05MinOkStateInit" INT 0 65535;
BA_DEF_  "E2EP05MaxErrorStateValid" INT 0 65535;
BA_DEF_  "E2EP05MaxErrorStateInvalid" INT 0 65535;
BA_DEF_  "E2EP05MaxErrorStateInit" INT 0 65535;
BA_DEF_  "E2EP05MaxDeltaCounter" INT 0 65535;
BA_DEF_  "E2EP01WindowSize" INT 0 65535;
BA_DEF_  "E2EP01SyncCounterInit" INT 0 65535;
BA_DEF_  "E2EP01ProfileName" STRING ;
BA_DEF_  "E2EP01MinOkStateValid" INT 0 65535;
BA_DEF_  "E2EP01MinOkStateInvalid" INT 0 65535;
BA_DEF_  "E2EP01MinOkStateInit" INT 0 65535;
BA_DEF_  "E2EP01MaxNoNewOrRepeatedData" INT 0 65535;
BA_DEF_  "E2EP01MaxErrorStateValid" INT 0 65535;
BA_DEF_  "E2EP01MaxErrorStateInvalid" INT 0 65535;
BA_DEF_  "E2EP01MaxErrorStateInit" INT 0 65535;
BA_DEF_  "E2EP01MaxDeltaCounter" INT 0 65535;
BA_DEF_  "E2EP01DataIdMode" ENUM  "all16Bit","alternating8Bit","lower12Bit","lower8Bit";
BA_DEF_  "E2EP01CounterOffset" INT 0 65535;
BA_DEF_ SG_  "E2EDataLength" INT 0 65535;
BA_DEF_ SG_  "E2EDataId" INT 0 65535;
BA_DEF_ BU_  "DiagnosticClientAddress" HEX 0 255;
BA_DEF_ BO_  "DiagUUDTResponse" ENUM  "No","Yes";
BA_DEF_ BO_  "DiagState" ENUM  "No","Yes";
BA_DEF_ BU_  "DiagRole" ENUM  "None","OBDTester","ExternalTester","InternalTester";
BA_DEF_ BO_  "DiagResponse" ENUM  "No","Yes";
BA_DEF_ BO_  "DiagRequest" ENUM  "No","Yes";
BA_DEF_ BO_  "DiagConnection" HEX 0 65535;
BA_DEF_  "DBName" STRING ;
BA_DEF_ BO_  "CanTpFcFrameId" HEX 0 2147483647;
BA_DEF_ BO_  "CanTpBs" INT 0 255;
BA_DEF_  "BusType" STRING ;
BA_DEF_  "BaudrateCANFD" INT 0 5000000;
BA_DEF_ SG_  "SystemSignalLongSymbol" STRING ;
BA_DEF_REL_ BU_SG_REL_  "GenSigTimeoutTime" INT 0 65535;
BA_DEF_REL_ BU_SG_REL_  "GenSigFirstTimeoutTime" INT 0 65535;
BA_DEF_DEF_  "GenMsgStartDelayTime" 0;
BA_DEF_DEF_  "GenMsgDelayTime" 0;
BA_DEF_DEF_  "GenMsgCycleTime" 0;
BA_DEF_DEF_  "GenMsgSendType" "Cyclic";
BA_DEF_DEF_  "GenSigStartValue" 0;
BA_DEF_DEF_  "GenSigInactiveValue" 0;
BA_DEF_DEF_  "GenSigCycleTimeActive" 0;
BA_DEF_DEF_  "GenSigCycleTime" 0;
BA_DEF_DEF_  "GenSigSendType" "Cyclic";
BA_DEF_DEF_  "Baudrate" 500000;
BA_DEF_DEF_  "NmType" "";
BA_DEF_DEF_  "Manufacturer" "VOLVO_AB";
BA_DEF_DEF_  "VersionYear" 0;
BA_DEF_DEF_  "VersionNumber" 0;
BA_DEF_DEF_  "VersionMonth" 1;
BA_DEF_DEF_  "VersionDay" 1;
BA_DEF_DEF_  "VFrameFormat" "ExtendedCAN";
BA_DEF_DEF_  "TpOwnSystemEcuNumber" 0;
BA_DEF_DEF_  "SigType" "Default";
BA_DEF_DEF_  "Platform_Vivis2_Sig" "No";
BA_DEF_DEF_  "Platform_VMCU1_Sig" "No";
BA_DEF_DEF_  "NmStationAddress" 254;
BA_DEF_DEF_  "NmAsrWaitBusSleepTime" 750;
BA_DEF_DEF_  "NmAsrTimeoutTime" 5000;
BA_DEF_DEF_  "NmAsrRepeatMessageTime" 300;
BA_DEF_DEF_  "NmAsrNodeIdentifier" 0;
BA_DEF_DEF_  "NmAsrNode" "Yes";
BA_DEF_DEF_  "NmAsrMessageCount" 256;
BA_DEF_DEF_  "NmAsrMessage" "No";
BA_DEF_DEF_  "NmAsrCanMsgCycleTime" 200;
BA_DEF_DEF_  "NmAsrBaseAddress" 486506496;
BA_DEF_DEF_  "NeedsUpdateBit" "No";
BA_DEF_DEF_  "MmAnSignal" "No";
BA_DEF_DEF_  "IsOBDrelevant" "No";
BA_DEF_DEF_  "GenSigMaxLatency" 0;
BA_DEF_DEF_  "GenSigILSupport" "Yes";
BA_DEF_DEF_  "GenMsgILSupport" "Yes";
BA_DEF_DEF_  "E2EProfile" "none";
BA_DEF_DEF_  "E2EP05WindowSize" 5;
BA_DEF_DEF_  "E2EP05ProfileName" "PROFILE_05";
BA_DEF_DEF_  "E2EP05MinOkStateValid" 1;
BA_DEF_DEF_  "E2EP05MinOkStateInvalid" 3;
BA_DEF_DEF_  "E2EP05MinOkStateInit" 1;
BA_DEF_DEF_  "E2EP05MaxErrorStateValid" 3;
BA_DEF_DEF_  "E2EP05MaxErrorStateInvalid" 1;
BA_DEF_DEF_  "E2EP05MaxErrorStateInit" 2;
BA_DEF_DEF_  "E2EP05MaxDeltaCounter" 1;
BA_DEF_DEF_  "E2EP01WindowSize" 5;
BA_DEF_DEF_  "E2EP01SyncCounterInit" 1;
BA_DEF_DEF_  "E2EP01ProfileName" "PROFILE_01";
BA_DEF_DEF_  "E2EP01MinOkStateValid" 1;
BA_DEF_DEF_  "E2EP01MinOkStateInvalid" 3;
BA_DEF_DEF_  "E2EP01MinOkStateInit" 1;
BA_DEF_DEF_  "E2EP01MaxNoNewOrRepeatedData" 5;
BA_DEF_DEF_  "E2EP01MaxErrorStateValid" 3;
BA_DEF_DEF_  "E2EP01MaxErrorStateInvalid" 1;
BA_DEF_DEF_  "E2EP01MaxErrorStateInit" 2;
BA_DEF_DEF_  "E2EP01MaxDeltaCounter" 1;
BA_DEF_DEF_  "E2EP01DataIdMode" "all16Bit";
BA_DEF_DEF_  "E2EP01CounterOffset" 8;
BA_DEF_DEF_  "E2EDataLength" 0;
BA_DEF_DEF_  "E2EDataId" 0;
BA_DEF_DEF_  "DiagnosticClientAddress" 0;
BA_DEF_DEF_  "DiagUUDTResponse" "No";
BA_DEF_DEF_  "DiagState" "No";
BA_DEF_DEF_  "DiagRole" "None";
BA_DEF_DEF_  "DiagResponse" "No";
BA_DEF_DEF_  "DiagRequest" "No";
BA_DEF_DEF_  "DiagConnection" 0;
BA_DEF_DEF_  "DBName" "";
BA_DEF_DEF_  "CanTpFcFrameId" 2147483647;
BA_DEF_DEF_  "CanTpBs" 255;
BA_DEF_DEF_  "BusType" "";
BA_DEF_DEF_  "BaudrateCANFD" 0;
BA_DEF_DEF_REL_ "GenSigTimeoutTime" 0;
BA_DEF_DEF_REL_ "GenSigFirstTimeoutTime" 0;
BA_DEF_DEF_  "SystemSignalLongSymbol" "";
BA_ "NmType" "NmAsr";
BA_ "BusType" "CAN";
BA_ "BaudrateCANFD" 1000000;
BA_ "VersionDay" 24;
BA_ "VersionMonth" 2;
BA_ "VersionNumber" 1;
BA_ "VersionYear" 22;
BA_ "DBName" "CAN04";
BA_ "DiagRole" BU_ VCM 3;
BA_ "DiagnosticClientAddress" BU_ VCM 244;
BA_ "IsOBDrelevant" BU_ VCM 1;
BA_ "TpOwnSystemEcuNumber" BU_ VCM 36;
BA_ "NmAsrNodeIdentifier" BU_ VCM 36;
BA_ "TpOwnSystemEcuNumber" BU_ TBIOM 39;
BA_ "NmAsrNodeIdentifier" BU_ TBIOM 39;
BA_ "TpOwnSystemEcuNumber" BU_ RCIOM 34;
BA_ "NmAsrNodeIdentifier" BU_ RCIOM 34;
BA_ "TpOwnSystemEcuNumber" BU_ FCIOM 33;
BA_ "NmAsrNodeIdentifier" BU_ FCIOM 33;
BA_ "TpOwnSystemEcuNumber" BU_ CCIOM 32;
BA_ "NmAsrNodeIdentifier" BU_ CCIOM 32;
BA_ "TpOwnSystemEcuNumber" BU_ BPMU 26;
BA_ "NmAsrNodeIdentifier" BU_ BPMU 26;
BA_ "VFrameFormat" BO_ 1361 0;
BA_ "GenMsgCycleTime" BO_ 1361 500;
BA_ "GenMsgStartDelayTime" BO_ 1361 10;
BA_ "VFrameFormat" BO_ 1267 0;
BA_ "GenMsgCycleTime" BO_ 1267 100;
BA_ "GenMsgStartDelayTime" BO_ 1267 25;
BA_ "VFrameFormat" BO_ 954 0;
BA_ "GenMsgCycleTime" BO_ 954 50;
BA_ "GenMsgStartDelayTime" BO_ 954 25;
BA_ "VFrameFormat" BO_ 677 0;
BA_ "GenMsgCycleTime" BO_ 677 20;
BA_ "GenMsgStartDelayTime" BO_ 677 5;
BA_ "VFrameFormat" BO_ 1363 0;
BA_ "GenMsgCycleTime" BO_ 1363 1000;
BA_ "GenMsgStartDelayTime" BO_ 1363 55;
BA_ "VFrameFormat" BO_ 535 0;
BA_ "GenMsgCycleTime" BO_ 535 30;
BA_ "GenMsgStartDelayTime" BO_ 535 20;
BA_ "VFrameFormat" BO_ 1381 0;
BA_ "GenMsgCycleTime" BO_ 1381 500;
BA_ "GenMsgStartDelayTime" BO_ 1381 65;
BA_ "VFrameFormat" BO_ 519 0;
BA_ "GenMsgSendType" BO_ 519 8;
BA_ "VFrameFormat" BO_ 518 0;
BA_ "GenMsgSendType" BO_ 518 8;
BA_ "VFrameFormat" BO_ 1249 0;
BA_ "GenMsgCycleTime" BO_ 1249 100;
BA_ "GenMsgStartDelayTime" BO_ 1249 10;
BA_ "VFrameFormat" BO_ 944 0;
BA_ "GenMsgCycleTime" BO_ 944 50;
BA_ "GenMsgStartDelayTime" BO_ 944 5;
BA_ "VFrameFormat" BO_ 390 0;
BA_ "GenMsgCycleTime" BO_ 390 10;
BA_ "GenMsgStartDelayTime" BO_ 390 5;
BA_ "VFrameFormat" BO_ 389 0;
BA_ "GenMsgCycleTime" BO_ 389 10;
BA_ "GenMsgStartDelayTime" BO_ 389 5;
BA_ "VFrameFormat" BO_ 1364 0;
BA_ "GenMsgCycleTime" BO_ 1364 250;
BA_ "GenMsgStartDelayTime" BO_ 1364 50;
BA_ "VFrameFormat" BO_ 826 0;
BA_ "GenMsgCycleTime" BO_ 826 30;
BA_ "GenMsgStartDelayTime" BO_ 826 5;
BA_ "VFrameFormat" BO_ 1369 0;
BA_ "GenMsgCycleTime" BO_ 1369 500;
BA_ "GenMsgStartDelayTime" BO_ 1369 135;
BA_ "VFrameFormat" BO_ 946 0;
BA_ "GenMsgCycleTime" BO_ 946 50;
BA_ "GenMsgStartDelayTime" BO_ 946 40;
BA_ "VFrameFormat" BO_ 945 0;
BA_ "GenMsgCycleTime" BO_ 945 50;
BA_ "GenMsgStartDelayTime" BO_ 945 15;
BA_ "VFrameFormat" BO_ 928 0;
BA_ "GenMsgCycleTime" BO_ 928 45;
BA_ "GenMsgStartDelayTime" BO_ 928 20;
BA_ "VFrameFormat" BO_ 827 0;
BA_ "GenMsgSendType" BO_ 827 8;
BA_ "GenMsgDelayTime" BO_ 827 25;
BA_ "VFrameFormat" BO_ 537 0;
BA_ "GenMsgCycleTime" BO_ 537 20;
BA_ "GenMsgStartDelayTime" BO_ 537 15;
BA_ "VFrameFormat" BO_ 531 0;
BA_ "GenMsgCycleTime" BO_ 531 20;
BA_ "GenMsgStartDelayTime" BO_ 531 5;
BA_ "VFrameFormat" BO_ 392 0;
BA_ "GenMsgCycleTime" BO_ 392 10;
BA_ "GenMsgStartDelayTime" BO_ 392 5;
BA_ "VFrameFormat" BO_ 895 0;
BA_ "GenMsgCycleTime" BO_ 895 50;
BA_ "GenMsgStartDelayTime" BO_ 895 5;
BA_ "VFrameFormat" BO_ 588 0;
BA_ "GenMsgCycleTime" BO_ 588 20;
BA_ "GenMsgStartDelayTime" BO_ 588 5;
BA_ "DiagConnection" BO_ 2671902706 61991;
BA_ "DiagState" BO_ 2671902706 1;
BA_ "GenMsgILSupport" BO_ 2671902706 0;
BA_ "GenMsgSendType" BO_ 2671902706 8;
BA_ "DiagConnection" BO_ 2671902708 62719;
BA_ "DiagState" BO_ 2671902708 1;
BA_ "GenMsgILSupport" BO_ 2671902708 0;
BA_ "GenMsgSendType" BO_ 2671902708 8;
BA_ "VFrameFormat" BO_ 957 0;
BA_ "GenMsgCycleTime" BO_ 957 100;
BA_ "GenMsgStartDelayTime" BO_ 957 5;
BA_ "VFrameFormat" BO_ 958 0;
BA_ "GenMsgCycleTime" BO_ 958 100;
BA_ "GenMsgStartDelayTime" BO_ 958 10;
BA_ "VFrameFormat" BO_ 1517 0;
BA_ "GenMsgCycleTime" BO_ 1517 1000;
BA_ "GenMsgStartDelayTime" BO_ 1517 60;
BA_ "VFrameFormat" BO_ 676 0;
BA_ "GenMsgCycleTime" BO_ 676 20;
BA_ "GenMsgStartDelayTime" BO_ 676 15;
BA_ "VFrameFormat" BO_ 1349 0;
BA_ "GenMsgCycleTime" BO_ 1349 250;
BA_ "GenMsgStartDelayTime" BO_ 1349 75;
BA_ "VFrameFormat" BO_ 951 0;
BA_ "GenMsgCycleTime" BO_ 951 50;
BA_ "GenMsgStartDelayTime" BO_ 951 5;
BA_ "VFrameFormat" BO_ 1344 0;
BA_ "GenMsgCycleTime" BO_ 1344 250;
BA_ "GenMsgStartDelayTime" BO_ 1344 150;
BA_ "GenSigCycleTime" SG_ 1361 Set_LG6CutoffValue 100;
BA_ "GenSigCycleTimeActive" SG_ 1361 Set_LG6CutoffValue 100;
BA_ "GenSigStartValue" SG_ 1361 Set_LG6CutoffValue 255;
BA_ "Platform_Vivis2_Sig" SG_ 1361 Set_LG6CutoffValue 1;
BA_ "GenSigCycleTime" SG_ 1361 Set_LG1CutoffValue 100;
BA_ "GenSigCycleTimeActive" SG_ 1361 Set_LG1CutoffValue 100;
BA_ "GenSigStartValue" SG_ 1361 Set_LG1CutoffValue 255;
BA_ "Platform_Vivis2_Sig" SG_ 1361 Set_LG1CutoffValue 1;
BA_ "GenSigCycleTime" SG_ 1361 Set_LG3CutoffValue 100;
BA_ "GenSigCycleTimeActive" SG_ 1361 Set_LG3CutoffValue 100;
BA_ "GenSigStartValue" SG_ 1361 Set_LG3CutoffValue 255;
BA_ "Platform_Vivis2_Sig" SG_ 1361 Set_LG3CutoffValue 1;
BA_ "GenSigCycleTime" SG_ 1361 Set_LG5CutoffValue 100;
BA_ "GenSigCycleTimeActive" SG_ 1361 Set_LG5CutoffValue 100;
BA_ "GenSigStartValue" SG_ 1361 Set_LG5CutoffValue 255;
BA_ "Platform_Vivis2_Sig" SG_ 1361 Set_LG5CutoffValue 1;
BA_ "GenSigCycleTime" SG_ 1361 Set_LG4CutoffValue 100;
BA_ "GenSigCycleTimeActive" SG_ 1361 Set_LG4CutoffValue 100;
BA_ "GenSigStartValue" SG_ 1361 Set_LG4CutoffValue 255;
BA_ "Platform_Vivis2_Sig" SG_ 1361 Set_LG4CutoffValue 1;
BA_ "GenSigCycleTime" SG_ 1361 Set_LG2CutoffValue 100;
BA_ "GenSigCycleTimeActive" SG_ 1361 Set_LG2CutoffValue 100;
BA_ "GenSigStartValue" SG_ 1361 Set_LG2CutoffValue 255;
BA_ "Platform_Vivis2_Sig" SG_ 1361 Set_LG2CutoffValue 1;
BA_ "GenSigCycleTime" SG_ 1361 Set_EnergySetting 100;
BA_ "GenSigCycleTimeActive" SG_ 1361 Set_EnergySetting 100;
BA_ "GenSigStartValue" SG_ 1361 Set_EnergySetting 7;
BA_ "Platform_Vivis2_Sig" SG_ 1361 Set_EnergySetting 1;
BA_ "GenSigCycleTime" SG_ 1267 KingPinUnlockCmd_CRC 100;
BA_ "GenSigCycleTimeActive" SG_ 1267 KingPinUnlockCmd_CRC 100;
BA_ "Platform_Vivis2_Sig" SG_ 1267 KingPinUnlockCmd_CRC 1;
BA_ "E2EDataId" SG_ 1267 KingPinUnlockCmd_CRC 179;
BA_ "E2EDataLength" SG_ 1267 KingPinUnlockCmd_CRC 16;
BA_ "E2EProfile" SG_ 1267 KingPinUnlockCmd_CRC "P01";
BA_ "GenSigCycleTime" SG_ 1267 AirIntakeSolenoidValve_cmd 100;
BA_ "GenSigCycleTimeActive" SG_ 1267 AirIntakeSolenoidValve_cmd 100;
BA_ "GenSigStartValue" SG_ 1267 AirIntakeSolenoidValve_cmd 3;
BA_ "Platform_Vivis2_Sig" SG_ 1267 AirIntakeSolenoidValve_cmd 1;
BA_ "GenSigCycleTime" SG_ 1267 TransmissionActualGearRatio 100;
BA_ "GenSigCycleTimeActive" SG_ 1267 TransmissionActualGearRatio 100;
BA_ "GenSigStartValue" SG_ 1267 TransmissionActualGearRatio 65535;
BA_ "Platform_Vivis2_Sig" SG_ 1267 TransmissionActualGearRatio 1;
BA_ "GenSigCycleTime" SG_ 1267 KingPinUnlockCmd_SqC 100;
BA_ "GenSigCycleTimeActive" SG_ 1267 KingPinUnlockCmd_SqC 100;
BA_ "Platform_Vivis2_Sig" SG_ 1267 KingPinUnlockCmd_SqC 1;
BA_ "GenSigCycleTime" SG_ 1267 KingPinUnlockCmd_Rqst 100;
BA_ "GenSigCycleTimeActive" SG_ 1267 KingPinUnlockCmd_Rqst 100;
BA_ "GenSigStartValue" SG_ 1267 KingPinUnlockCmd_Rqst 3;
BA_ "Platform_Vivis2_Sig" SG_ 1267 KingPinUnlockCmd_Rqst 1;
BA_ "GenSigCycleTime" SG_ 1267 PreventECSFuncForSWDL_rqst 100;
BA_ "GenSigCycleTimeActive" SG_ 1267 PreventECSFuncForSWDL_rqst 100;
BA_ "GenSigStartValue" SG_ 1267 PreventECSFuncForSWDL_rqst 3;
BA_ "Platform_Vivis2_Sig" SG_ 1267 PreventECSFuncForSWDL_rqst 1;
BA_ "GenSigCycleTime" SG_ 1267 AutoShutOffAnswerInput 100;
BA_ "GenSigCycleTimeActive" SG_ 1267 AutoShutOffAnswerInput 100;
BA_ "GenSigStartValue" SG_ 1267 AutoShutOffAnswerInput 7;
BA_ "Platform_Vivis2_Sig" SG_ 1267 AutoShutOffAnswerInput 1;
BA_ "GenSigCycleTime" SG_ 954 DumpSwitchChangeReq 100;
BA_ "GenSigCycleTimeActive" SG_ 954 DumpSwitchChangeReq 100;
BA_ "GenSigStartValue" SG_ 954 DumpSwitchChangeReq 3;
BA_ "Platform_Vivis2_Sig" SG_ 954 DumpSwitchChangeReq 1;
BA_ "GenSigCycleTime" SG_ 954 CAHighBeamFlash_cmd 100;
BA_ "GenSigCycleTimeActive" SG_ 954 CAHighBeamFlash_cmd 100;
BA_ "GenSigStartValue" SG_ 954 CAHighBeamFlash_cmd 3;
BA_ "Platform_Vivis2_Sig" SG_ 954 CAHighBeamFlash_cmd 1;
BA_ "GenSigCycleTime" SG_ 954 HeadLampDeicingControl_rqst 100;
BA_ "GenSigCycleTimeActive" SG_ 954 HeadLampDeicingControl_rqst 100;
BA_ "GenSigStartValue" SG_ 954 HeadLampDeicingControl_rqst 3;
BA_ "Platform_Vivis2_Sig" SG_ 954 HeadLampDeicingControl_rqst 1;
BA_ "GenSigCycleTime" SG_ 677 EngineStarterMode 100;
BA_ "GenSigCycleTimeActive" SG_ 677 EngineStarterMode 100;
BA_ "GenSigStartValue" SG_ 677 EngineStarterMode 15;
BA_ "GenSigMaxLatency" SG_ 677 EngineStarterMode 20;
BA_ "Platform_Vivis2_Sig" SG_ 677 EngineStarterMode 1;
BA_ "GenSigCycleTime" SG_ 1363 PredeliveryModeIndication_cmd 100;
BA_ "GenSigCycleTimeActive" SG_ 1363 PredeliveryModeIndication_cmd 100;
BA_ "GenSigStartValue" SG_ 1363 PredeliveryModeIndication_cmd 3;
BA_ "Platform_Vivis2_Sig" SG_ 1363 PredeliveryModeIndication_cmd 1;
BA_ "GenSigCycleTime" SG_ 535 DirectionIndicatorLightsStatus 100;
BA_ "GenSigCycleTimeActive" SG_ 535 DirectionIndicatorLightsStatus 100;
BA_ "GenSigStartValue" SG_ 535 DirectionIndicatorLightsStatus 15;
BA_ "GenSigMaxLatency" SG_ 535 DirectionIndicatorLightsStatus 25;
BA_ "Platform_Vivis2_Sig" SG_ 535 DirectionIndicatorLightsStatus 1;
BA_ "GenSigCycleTime" SG_ 535 HeadlightAngle_cmd 100;
BA_ "GenSigCycleTimeActive" SG_ 535 HeadlightAngle_cmd 100;
BA_ "GenSigStartValue" SG_ 535 HeadlightAngle_cmd 255;
BA_ "Platform_Vivis2_Sig" SG_ 535 HeadlightAngle_cmd 1;
BA_ "GenSigCycleTime" SG_ 1381 BattEnergySetLevel_input 100;
BA_ "GenSigCycleTimeActive" SG_ 1381 BattEnergySetLevel_input 100;
BA_ "GenSigStartValue" SG_ 1381 BattEnergySetLevel_input 7;
BA_ "Platform_Vivis2_Sig" SG_ 1381 BattEnergySetLevel_input 1;
BA_ "GenSigCycleTime" SG_ 1381 AmbientAirTemperature 100;
BA_ "GenSigCycleTimeActive" SG_ 1381 AmbientAirTemperature 100;
BA_ "GenSigStartValue" SG_ 1381 AmbientAirTemperature 65535;
BA_ "GenSigMaxLatency" SG_ 1381 AmbientAirTemperature 59;
BA_ "Platform_VMCU1_Sig" SG_ 1381 AmbientAirTemperature 1;
BA_ "Platform_Vivis2_Sig" SG_ 1381 AmbientAirTemperature 1;
BA_ "GenSigCycleTime" SG_ 1381 EnergyForNextCrank 100;
BA_ "GenSigCycleTimeActive" SG_ 1381 EnergyForNextCrank 100;
BA_ "GenSigStartValue" SG_ 1381 EnergyForNextCrank 15;
BA_ "Platform_Vivis2_Sig" SG_ 1381 EnergyForNextCrank 1;
BA_ "GenSigCycleTime" SG_ 1381 MainBatteryResetPos 100;
BA_ "GenSigCycleTimeActive" SG_ 1381 MainBatteryResetPos 100;
BA_ "GenSigStartValue" SG_ 1381 MainBatteryResetPos 15;
BA_ "Platform_Vivis2_Sig" SG_ 1381 MainBatteryResetPos 1;
BA_ "GenSigSendType" SG_ 519 GlareFreeArea02_LeftAngle 1;
BA_ "GenSigStartValue" SG_ 519 GlareFreeArea02_LeftAngle 2047;
BA_ "Platform_VMCU1_Sig" SG_ 519 GlareFreeArea02_LeftAngle 1;
BA_ "Platform_Vivis2_Sig" SG_ 519 GlareFreeArea02_LeftAngle 1;
BA_ "GenSigSendType" SG_ 519 AdaptiveMainBeamRight_cmd 1;
BA_ "GenSigStartValue" SG_ 519 AdaptiveMainBeamRight_cmd 7;
BA_ "Platform_VMCU1_Sig" SG_ 519 AdaptiveMainBeamRight_cmd 1;
BA_ "Platform_Vivis2_Sig" SG_ 519 AdaptiveMainBeamRight_cmd 1;
BA_ "GenSigSendType" SG_ 519 AdaptiveMainBeamLeft_cmd 1;
BA_ "GenSigStartValue" SG_ 519 AdaptiveMainBeamLeft_cmd 7;
BA_ "Platform_VMCU1_Sig" SG_ 519 AdaptiveMainBeamLeft_cmd 1;
BA_ "Platform_Vivis2_Sig" SG_ 519 AdaptiveMainBeamLeft_cmd 1;
BA_ "GenSigSendType" SG_ 519 GlareFreeArea02_Distance 1;
BA_ "GenSigStartValue" SG_ 519 GlareFreeArea02_Distance 1023;
BA_ "Platform_VMCU1_Sig" SG_ 519 GlareFreeArea02_Distance 1;
BA_ "Platform_Vivis2_Sig" SG_ 519 GlareFreeArea02_Distance 1;
BA_ "GenSigSendType" SG_ 519 GlareFreeArea02_RightAngle 1;
BA_ "GenSigStartValue" SG_ 519 GlareFreeArea02_RightAngle 2047;
BA_ "Platform_VMCU1_Sig" SG_ 519 GlareFreeArea02_RightAngle 1;
BA_ "Platform_Vivis2_Sig" SG_ 519 GlareFreeArea02_RightAngle 1;
BA_ "GenSigSendType" SG_ 518 GlareFreeArea03_Distance 1;
BA_ "GenSigStartValue" SG_ 518 GlareFreeArea03_Distance 1023;
BA_ "Platform_VMCU1_Sig" SG_ 518 GlareFreeArea03_Distance 1;
BA_ "Platform_Vivis2_Sig" SG_ 518 GlareFreeArea03_Distance 1;
BA_ "GenSigSendType" SG_ 518 GlareFreeArea01_Distance 1;
BA_ "GenSigStartValue" SG_ 518 GlareFreeArea01_Distance 1023;
BA_ "GenSigSendType" SG_ 518 GlareFreeArea01_LeftAngle 1;
BA_ "GenSigStartValue" SG_ 518 GlareFreeArea01_LeftAngle 2047;
BA_ "Platform_VMCU1_Sig" SG_ 518 GlareFreeArea01_LeftAngle 1;
BA_ "Platform_Vivis2_Sig" SG_ 518 GlareFreeArea01_LeftAngle 1;
BA_ "GenSigSendType" SG_ 518 GlareFreeArea03_RightAngle 1;
BA_ "GenSigStartValue" SG_ 518 GlareFreeArea03_RightAngle 2047;
BA_ "Platform_VMCU1_Sig" SG_ 518 GlareFreeArea03_RightAngle 1;
BA_ "Platform_Vivis2_Sig" SG_ 518 GlareFreeArea03_RightAngle 1;
BA_ "GenSigSendType" SG_ 518 GlareFreeArea03_LeftAngle 1;
BA_ "GenSigStartValue" SG_ 518 GlareFreeArea03_LeftAngle 2047;
BA_ "Platform_VMCU1_Sig" SG_ 518 GlareFreeArea03_LeftAngle 1;
BA_ "Platform_Vivis2_Sig" SG_ 518 GlareFreeArea03_LeftAngle 1;
BA_ "GenSigSendType" SG_ 518 GlareFreeArea01_RightAngle 1;
BA_ "GenSigStartValue" SG_ 518 GlareFreeArea01_RightAngle 2047;
BA_ "Platform_VMCU1_Sig" SG_ 518 GlareFreeArea01_RightAngle 1;
BA_ "Platform_Vivis2_Sig" SG_ 518 GlareFreeArea01_RightAngle 1;
BA_ "GenSigCycleTime" SG_ 1249 TransferCasePTOEngaged 100;
BA_ "GenSigCycleTimeActive" SG_ 1249 TransferCasePTOEngaged 100;
BA_ "GenSigStartValue" SG_ 1249 TransferCasePTOEngaged 3;
BA_ "Platform_VMCU1_Sig" SG_ 1249 TransferCasePTOEngaged 1;
BA_ "Platform_Vivis2_Sig" SG_ 1249 TransferCasePTOEngaged 1;
BA_ "GenSigCycleTime" SG_ 1249 EhrasTagAxleLoweringInhibit 100;
BA_ "GenSigCycleTimeActive" SG_ 1249 EhrasTagAxleLoweringInhibit 100;
BA_ "GenSigStartValue" SG_ 1249 EhrasTagAxleLoweringInhibit 3;
BA_ "Platform_Vivis2_Sig" SG_ 1249 EhrasTagAxleLoweringInhibit 1;
BA_ "GenSigCycleTime" SG_ 1249 ExtECSRequestPressureUpdate 100;
BA_ "GenSigCycleTimeActive" SG_ 1249 ExtECSRequestPressureUpdate 100;
BA_ "GenSigStartValue" SG_ 1249 ExtECSRequestPressureUpdate 3;
BA_ "Platform_Vivis2_Sig" SG_ 1249 ExtECSRequestPressureUpdate 1;
BA_ "GenSigCycleTime" SG_ 1249 HeadLampFanControl_rqst 100;
BA_ "GenSigCycleTimeActive" SG_ 1249 HeadLampFanControl_rqst 100;
BA_ "GenSigStartValue" SG_ 1249 HeadLampFanControl_rqst 3;
BA_ "Platform_Vivis2_Sig" SG_ 1249 HeadLampFanControl_rqst 1;
BA_ "GenSigCycleTime" SG_ 1249 BBAirDumpRequest 100;
BA_ "GenSigCycleTimeActive" SG_ 1249 BBAirDumpRequest 100;
BA_ "GenSigStartValue" SG_ 1249 BBAirDumpRequest 3;
BA_ "Platform_Vivis2_Sig" SG_ 1249 BBAirDumpRequest 1;
BA_ "GenSigCycleTime" SG_ 1249 ApproachLight_rqst 100;
BA_ "GenSigCycleTimeActive" SG_ 1249 ApproachLight_rqst 100;
BA_ "GenSigStartValue" SG_ 1249 ApproachLight_rqst 3;
BA_ "Platform_Vivis2_Sig" SG_ 1249 ApproachLight_rqst 1;
BA_ "GenSigCycleTime" SG_ 1249 FrAxle2WheelDriveRequest 100;
BA_ "GenSigCycleTimeActive" SG_ 1249 FrAxle2WheelDriveRequest 100;
BA_ "GenSigStartValue" SG_ 1249 FrAxle2WheelDriveRequest 3;
BA_ "Platform_VMCU1_Sig" SG_ 1249 FrAxle2WheelDriveRequest 1;
BA_ "Platform_Vivis2_Sig" SG_ 1249 FrAxle2WheelDriveRequest 1;
BA_ "GenSigCycleTime" SG_ 1249 EhrasPusherAxleLoweringInhibit 100;
BA_ "GenSigCycleTimeActive" SG_ 1249 EhrasPusherAxleLoweringInhibit 100;
BA_ "GenSigStartValue" SG_ 1249 EhrasPusherAxleLoweringInhibit 3;
BA_ "Platform_Vivis2_Sig" SG_ 1249 EhrasPusherAxleLoweringInhibit 1;
BA_ "GenSigCycleTime" SG_ 1249 LivBatteryChargingStat_rqst 100;
BA_ "GenSigCycleTimeActive" SG_ 1249 LivBatteryChargingStat_rqst 100;
BA_ "GenSigStartValue" SG_ 1249 LivBatteryChargingStat_rqst 3;
BA_ "Platform_Vivis2_Sig" SG_ 1249 LivBatteryChargingStat_rqst 1;
BA_ "GenSigCycleTime" SG_ 1249 ClutchSwitch2Stat 100;
BA_ "GenSigCycleTimeActive" SG_ 1249 ClutchSwitch2Stat 100;
BA_ "GenSigStartValue" SG_ 1249 ClutchSwitch2Stat 3;
BA_ "Platform_VMCU1_Sig" SG_ 1249 ClutchSwitch2Stat 1;
BA_ "Platform_Vivis2_Sig" SG_ 1249 ClutchSwitch2Stat 1;
BA_ "GenSigCycleTime" SG_ 1249 SideMarkersLights_cmd 100;
BA_ "GenSigCycleTimeActive" SG_ 1249 SideMarkersLights_cmd 100;
BA_ "GenSigStartValue" SG_ 1249 SideMarkersLights_cmd 7;
BA_ "Platform_VMCU1_Sig" SG_ 1249 SideMarkersLights_cmd 1;
BA_ "Platform_Vivis2_Sig" SG_ 1249 SideMarkersLights_cmd 1;
BA_ "GenSigCycleTime" SG_ 1249 BBEcsForceStandstillFilterReq 100;
BA_ "GenSigCycleTimeActive" SG_ 1249 BBEcsForceStandstillFilterReq 100;
BA_ "GenSigStartValue" SG_ 1249 BBEcsForceStandstillFilterReq 3;
BA_ "Platform_Vivis2_Sig" SG_ 1249 BBEcsForceStandstillFilterReq 1;
BA_ "GenSigCycleTime" SG_ 944 ShortStopHeater_cmd 100;
BA_ "GenSigCycleTimeActive" SG_ 944 ShortStopHeater_cmd 100;
BA_ "GenSigStartValue" SG_ 944 ShortStopHeater_cmd 3;
BA_ "Platform_VMCU1_Sig" SG_ 944 ShortStopHeater_cmd 1;
BA_ "Platform_Vivis2_Sig" SG_ 944 ShortStopHeater_cmd 1;
BA_ "GenSigSendType" SG_ 944 LoadDistributionRequested_UB 7;
BA_ "Platform_VMCU1_Sig" SG_ 944 LoadDistributionRequested_UB 1;
BA_ "Platform_Vivis2_Sig" SG_ 944 LoadDistributionRequested_UB 1;
BA_ "GenSigCycleTime" SG_ 944 LoadDistributionRequested 100;
BA_ "GenSigCycleTimeActive" SG_ 944 LoadDistributionRequested 100;
BA_ "GenSigStartValue" SG_ 944 LoadDistributionRequested 15;
BA_ "NeedsUpdateBit" SG_ 944 LoadDistributionRequested 1;
BA_ "Platform_VMCU1_Sig" SG_ 944 LoadDistributionRequested 1;
BA_ "Platform_Vivis2_Sig" SG_ 944 LoadDistributionRequested 1;
BA_ "GenSigSendType" SG_ 390 CityHorn_cmd_UB 7;
BA_ "Platform_VMCU1_Sig" SG_ 390 CityHorn_cmd_UB 1;
BA_ "Platform_Vivis2_Sig" SG_ 390 CityHorn_cmd_UB 1;
BA_ "GenSigSendType" SG_ 390 FrontAxleRightWheelSpeed_UB 7;
BA_ "Platform_VMCU1_Sig" SG_ 390 FrontAxleRightWheelSpeed_UB 1;
BA_ "Platform_Vivis2_Sig" SG_ 390 FrontAxleRightWheelSpeed_UB 1;
BA_ "GenSigCycleTime" SG_ 390 CityHorn_cmd 100;
BA_ "GenSigCycleTimeActive" SG_ 390 CityHorn_cmd 100;
BA_ "GenSigStartValue" SG_ 390 CityHorn_cmd 3;
BA_ "GenSigMaxLatency" SG_ 390 CityHorn_cmd 23;
BA_ "NeedsUpdateBit" SG_ 390 CityHorn_cmd 1;
BA_ "Platform_VMCU1_Sig" SG_ 390 CityHorn_cmd 1;
BA_ "Platform_Vivis2_Sig" SG_ 390 CityHorn_cmd 1;
BA_ "GenSigCycleTime" SG_ 390 BrakeSwitch 100;
BA_ "GenSigCycleTimeActive" SG_ 390 BrakeSwitch 100;
BA_ "GenSigStartValue" SG_ 390 BrakeSwitch 3;
BA_ "GenSigMaxLatency" SG_ 390 BrakeSwitch 23;
BA_ "Platform_VMCU1_Sig" SG_ 390 BrakeSwitch 1;
BA_ "Platform_Vivis2_Sig" SG_ 390 BrakeSwitch 1;
BA_ "GenSigCycleTime" SG_ 390 LevelRequest_FrontAxle 100;
BA_ "GenSigCycleTimeActive" SG_ 390 LevelRequest_FrontAxle 100;
BA_ "GenSigStartValue" SG_ 390 LevelRequest_FrontAxle 7;
BA_ "NeedsUpdateBit" SG_ 390 LevelRequest_FrontAxle 1;
BA_ "Platform_VMCU1_Sig" SG_ 390 LevelRequest_FrontAxle 1;
BA_ "Platform_Vivis2_Sig" SG_ 390 LevelRequest_FrontAxle 1;
BA_ "GenSigSendType" SG_ 390 AuxiliaryHorn_cmd_UB 7;
BA_ "Platform_VMCU1_Sig" SG_ 390 AuxiliaryHorn_cmd_UB 1;
BA_ "Platform_Vivis2_Sig" SG_ 390 AuxiliaryHorn_cmd_UB 1;
BA_ "GenSigCycleTime" SG_ 390 FrontAxleRightWheelSpeed 100;
BA_ "GenSigCycleTimeActive" SG_ 390 FrontAxleRightWheelSpeed 100;
BA_ "GenSigStartValue" SG_ 390 FrontAxleRightWheelSpeed 65535;
BA_ "NeedsUpdateBit" SG_ 390 FrontAxleRightWheelSpeed 1;
BA_ "Platform_VMCU1_Sig" SG_ 390 FrontAxleRightWheelSpeed 1;
BA_ "Platform_Vivis2_Sig" SG_ 390 FrontAxleRightWheelSpeed 1;
BA_ "GenSigCycleTime" SG_ 390 FrontAxleLeftWheelSpeed 100;
BA_ "GenSigCycleTimeActive" SG_ 390 FrontAxleLeftWheelSpeed 100;
BA_ "GenSigStartValue" SG_ 390 FrontAxleLeftWheelSpeed 65535;
BA_ "NeedsUpdateBit" SG_ 390 FrontAxleLeftWheelSpeed 1;
BA_ "Platform_VMCU1_Sig" SG_ 390 FrontAxleLeftWheelSpeed 1;
BA_ "Platform_Vivis2_Sig" SG_ 390 FrontAxleLeftWheelSpeed 1;
BA_ "GenSigCycleTime" SG_ 390 FPBRChangeReq 100;
BA_ "GenSigCycleTimeActive" SG_ 390 FPBRChangeReq 100;
BA_ "GenSigStartValue" SG_ 390 FPBRChangeReq 3;
BA_ "Platform_VMCU1_Sig" SG_ 390 FPBRChangeReq 1;
BA_ "Platform_Vivis2_Sig" SG_ 390 FPBRChangeReq 1;
BA_ "GenSigCycleTime" SG_ 390 AuxiliaryHorn_cmd 100;
BA_ "GenSigCycleTimeActive" SG_ 390 AuxiliaryHorn_cmd 100;
BA_ "GenSigStartValue" SG_ 390 AuxiliaryHorn_cmd 3;
BA_ "GenSigMaxLatency" SG_ 390 AuxiliaryHorn_cmd 23;
BA_ "NeedsUpdateBit" SG_ 390 AuxiliaryHorn_cmd 1;
BA_ "Platform_VMCU1_Sig" SG_ 390 AuxiliaryHorn_cmd 1;
BA_ "Platform_Vivis2_Sig" SG_ 390 AuxiliaryHorn_cmd 1;
BA_ "GenSigSendType" SG_ 390 LevelRequest_sg_UB 7;
BA_ "Platform_VMCU1_Sig" SG_ 390 LevelRequest_sg_UB 1;
BA_ "Platform_Vivis2_Sig" SG_ 390 LevelRequest_sg_UB 1;
BA_ "GenSigCycleTime" SG_ 390 LevelRequest_RearAxle 100;
BA_ "GenSigCycleTimeActive" SG_ 390 LevelRequest_RearAxle 100;
BA_ "GenSigStartValue" SG_ 390 LevelRequest_RearAxle 7;
BA_ "NeedsUpdateBit" SG_ 390 LevelRequest_RearAxle 1;
BA_ "Platform_VMCU1_Sig" SG_ 390 LevelRequest_RearAxle 1;
BA_ "Platform_Vivis2_Sig" SG_ 390 LevelRequest_RearAxle 1;
BA_ "GenSigCycleTime" SG_ 390 LevelRequest_RollRequest 100;
BA_ "GenSigCycleTimeActive" SG_ 390 LevelRequest_RollRequest 100;
BA_ "GenSigStartValue" SG_ 390 LevelRequest_RollRequest 7;
BA_ "NeedsUpdateBit" SG_ 390 LevelRequest_RollRequest 1;
BA_ "Platform_VMCU1_Sig" SG_ 390 LevelRequest_RollRequest 1;
BA_ "Platform_Vivis2_Sig" SG_ 390 LevelRequest_RollRequest 1;
BA_ "GenSigSendType" SG_ 390 FrontAxleLeftWheelSpeed_UB 7;
BA_ "Platform_VMCU1_Sig" SG_ 390 FrontAxleLeftWheelSpeed_UB 1;
BA_ "Platform_Vivis2_Sig" SG_ 390 FrontAxleLeftWheelSpeed_UB 1;
BA_ "GenSigSendType" SG_ 389 RearAxleRightWheelSpeed_UB 7;
BA_ "Platform_VMCU1_Sig" SG_ 389 RearAxleRightWheelSpeed_UB 1;
BA_ "Platform_Vivis2_Sig" SG_ 389 RearAxleRightWheelSpeed_UB 1;
BA_ "GenSigCycleTime" SG_ 389 FrontWheelDriveRequest 100;
BA_ "GenSigCycleTimeActive" SG_ 389 FrontWheelDriveRequest 100;
BA_ "GenSigStartValue" SG_ 389 FrontWheelDriveRequest 3;
BA_ "Platform_VMCU1_Sig" SG_ 389 FrontWheelDriveRequest 1;
BA_ "Platform_Vivis2_Sig" SG_ 389 FrontWheelDriveRequest 1;
BA_ "GenSigCycleTime" SG_ 389 RearAxleLeftWheelSpeed 100;
BA_ "GenSigCycleTimeActive" SG_ 389 RearAxleLeftWheelSpeed 100;
BA_ "GenSigStartValue" SG_ 389 RearAxleLeftWheelSpeed 65535;
BA_ "GenSigMaxLatency" SG_ 389 RearAxleLeftWheelSpeed 51;
BA_ "NeedsUpdateBit" SG_ 389 RearAxleLeftWheelSpeed 1;
BA_ "Platform_VMCU1_Sig" SG_ 389 RearAxleLeftWheelSpeed 1;
BA_ "Platform_Vivis2_Sig" SG_ 389 RearAxleLeftWheelSpeed 1;
BA_ "GenSigSendType" SG_ 389 RearAxleLeftWheelSpeed_UB 7;
BA_ "Platform_VMCU1_Sig" SG_ 389 RearAxleLeftWheelSpeed_UB 1;
BA_ "Platform_Vivis2_Sig" SG_ 389 RearAxleLeftWheelSpeed_UB 1;
BA_ "GenSigCycleTime" SG_ 389 RearAxleRightWheelSpeed 100;
BA_ "GenSigCycleTimeActive" SG_ 389 RearAxleRightWheelSpeed 100;
BA_ "GenSigStartValue" SG_ 389 RearAxleRightWheelSpeed 65535;
BA_ "GenSigMaxLatency" SG_ 389 RearAxleRightWheelSpeed 51;
BA_ "NeedsUpdateBit" SG_ 389 RearAxleRightWheelSpeed 1;
BA_ "Platform_VMCU1_Sig" SG_ 389 RearAxleRightWheelSpeed 1;
BA_ "Platform_Vivis2_Sig" SG_ 389 RearAxleRightWheelSpeed 1;
BA_ "GenSigCycleTime" SG_ 389 KneelingChangeRequest 100;
BA_ "GenSigCycleTimeActive" SG_ 389 KneelingChangeRequest 100;
BA_ "GenSigStartValue" SG_ 389 KneelingChangeRequest 3;
BA_ "Platform_VMCU1_Sig" SG_ 389 KneelingChangeRequest 1;
BA_ "Platform_Vivis2_Sig" SG_ 389 KneelingChangeRequest 1;
BA_ "GenSigCycleTime" SG_ 1364 HoursUTC 100;
BA_ "GenSigCycleTimeActive" SG_ 1364 HoursUTC 100;
BA_ "GenSigStartValue" SG_ 1364 HoursUTC 255;
BA_ "Platform_VMCU1_Sig" SG_ 1364 HoursUTC 1;
BA_ "Platform_Vivis2_Sig" SG_ 1364 HoursUTC 1;
BA_ "GenSigCycleTime" SG_ 1364 RoadInclination 100;
BA_ "GenSigCycleTimeActive" SG_ 1364 RoadInclination 100;
BA_ "GenSigStartValue" SG_ 1364 RoadInclination 255;
BA_ "Platform_VMCU1_Sig" SG_ 1364 RoadInclination 1;
BA_ "Platform_Vivis2_Sig" SG_ 1364 RoadInclination 1;
BA_ "GenSigCycleTime" SG_ 1364 MonthUTC 100;
BA_ "GenSigCycleTimeActive" SG_ 1364 MonthUTC 100;
BA_ "GenSigStartValue" SG_ 1364 MonthUTC 255;
BA_ "Platform_VMCU1_Sig" SG_ 1364 MonthUTC 1;
BA_ "Platform_Vivis2_Sig" SG_ 1364 MonthUTC 1;
BA_ "GenSigCycleTime" SG_ 1364 YearUTC 100;
BA_ "GenSigCycleTimeActive" SG_ 1364 YearUTC 100;
BA_ "GenSigStartValue" SG_ 1364 YearUTC 255;
BA_ "Platform_VMCU1_Sig" SG_ 1364 YearUTC 1;
BA_ "Platform_Vivis2_Sig" SG_ 1364 YearUTC 1;
BA_ "GenSigCycleTime" SG_ 1364 SecondsUTC 100;
BA_ "GenSigCycleTimeActive" SG_ 1364 SecondsUTC 100;
BA_ "GenSigStartValue" SG_ 1364 SecondsUTC 255;
BA_ "Platform_VMCU1_Sig" SG_ 1364 SecondsUTC 1;
BA_ "Platform_Vivis2_Sig" SG_ 1364 SecondsUTC 1;
BA_ "GenSigCycleTime" SG_ 1364 DayUTC 100;
BA_ "GenSigCycleTimeActive" SG_ 1364 DayUTC 100;
BA_ "GenSigStartValue" SG_ 1364 DayUTC 255;
BA_ "Platform_VMCU1_Sig" SG_ 1364 DayUTC 1;
BA_ "Platform_Vivis2_Sig" SG_ 1364 DayUTC 1;
BA_ "GenSigCycleTime" SG_ 1364 MinutesUTC 100;
BA_ "GenSigCycleTimeActive" SG_ 1364 MinutesUTC 100;
BA_ "GenSigStartValue" SG_ 1364 MinutesUTC 255;
BA_ "Platform_VMCU1_Sig" SG_ 1364 MinutesUTC 1;
BA_ "Platform_Vivis2_Sig" SG_ 1364 MinutesUTC 1;
BA_ "GenSigCycleTime" SG_ 826 BBContUnlockCmd 100;
BA_ "GenSigCycleTimeActive" SG_ 826 BBContUnlockCmd 100;
BA_ "GenSigStartValue" SG_ 826 BBContUnlockCmd 3;
BA_ "GenSigMaxLatency" SG_ 826 BBContUnlockCmd 35;
BA_ "Platform_VMCU1_Sig" SG_ 826 BBContUnlockCmd 1;
BA_ "Platform_Vivis2_Sig" SG_ 826 BBContUnlockCmd 1;
BA_ "GenSigCycleTime" SG_ 826 LampCheck_cmd 100;
BA_ "GenSigCycleTimeActive" SG_ 826 LampCheck_cmd 100;
BA_ "GenSigStartValue" SG_ 826 LampCheck_cmd 3;
BA_ "Platform_VMCU1_Sig" SG_ 826 LampCheck_cmd 1;
BA_ "Platform_Vivis2_Sig" SG_ 826 LampCheck_cmd 1;
BA_ "GenSigCycleTime" SG_ 826 LampCheck_rqst 100;
BA_ "GenSigCycleTimeActive" SG_ 826 LampCheck_rqst 100;
BA_ "GenSigStartValue" SG_ 826 LampCheck_rqst 3;
BA_ "Platform_VMCU1_Sig" SG_ 826 LampCheck_rqst 1;
BA_ "Platform_Vivis2_Sig" SG_ 826 LampCheck_rqst 1;
BA_ "GenSigCycleTime" SG_ 826 BatteryCapacity 100;
BA_ "GenSigCycleTimeActive" SG_ 826 BatteryCapacity 100;
BA_ "GenSigStartValue" SG_ 826 BatteryCapacity 15;
BA_ "Platform_VMCU1_Sig" SG_ 826 BatteryCapacity 1;
BA_ "Platform_Vivis2_Sig" SG_ 826 BatteryCapacity 1;
BA_ "GenSigCycleTime" SG_ 826 AreaInhibit 100;
BA_ "GenSigCycleTimeActive" SG_ 826 AreaInhibit 100;
BA_ "GenSigStartValue" SG_ 826 AreaInhibit 3;
BA_ "GenSigMaxLatency" SG_ 826 AreaInhibit 35;
BA_ "Platform_VMCU1_Sig" SG_ 826 AreaInhibit 1;
BA_ "Platform_Vivis2_Sig" SG_ 826 AreaInhibit 1;
BA_ "GenSigCycleTime" SG_ 826 LEDAnimation_cmd 100;
BA_ "GenSigCycleTimeActive" SG_ 826 LEDAnimation_cmd 100;
BA_ "GenSigInactiveValue" SG_ 826 LEDAnimation_cmd 7;
BA_ "GenSigStartValue" SG_ 826 LEDAnimation_cmd 7;
BA_ "Platform_VMCU1_Sig" SG_ 826 LEDAnimation_cmd 1;
BA_ "Platform_Vivis2_Sig" SG_ 826 LEDAnimation_cmd 1;
BA_ "GenSigCycleTime" SG_ 826 ActualDrvlnRetdrPercentTorque 100;
BA_ "GenSigCycleTimeActive" SG_ 826 ActualDrvlnRetdrPercentTorque 100;
BA_ "GenSigStartValue" SG_ 826 ActualDrvlnRetdrPercentTorque 255;
BA_ "GenSigMaxLatency" SG_ 826 ActualDrvlnRetdrPercentTorque 35;
BA_ "Platform_VMCU1_Sig" SG_ 826 ActualDrvlnRetdrPercentTorque 1;
BA_ "Platform_Vivis2_Sig" SG_ 826 ActualDrvlnRetdrPercentTorque 1;
BA_ "GenSigCycleTime" SG_ 826 PloughLampModeStatus 100;
BA_ "GenSigCycleTimeActive" SG_ 826 PloughLampModeStatus 100;
BA_ "GenSigStartValue" SG_ 826 PloughLampModeStatus 3;
BA_ "Platform_VMCU1_Sig" SG_ 826 PloughLampModeStatus 1;
BA_ "Platform_Vivis2_Sig" SG_ 826 PloughLampModeStatus 1;
BA_ "GenSigCycleTime" SG_ 826 RangeInhibit 100;
BA_ "GenSigCycleTimeActive" SG_ 826 RangeInhibit 100;
BA_ "GenSigStartValue" SG_ 826 RangeInhibit 3;
BA_ "GenSigMaxLatency" SG_ 826 RangeInhibit 35;
BA_ "Platform_VMCU1_Sig" SG_ 826 RangeInhibit 1;
BA_ "Platform_Vivis2_Sig" SG_ 826 RangeInhibit 1;
BA_ "GenSigCycleTime" SG_ 826 TrailerBrakeNoEbs_stat 100;
BA_ "GenSigCycleTimeActive" SG_ 826 TrailerBrakeNoEbs_stat 100;
BA_ "GenSigStartValue" SG_ 826 TrailerBrakeNoEbs_stat 3;
BA_ "GenSigMaxLatency" SG_ 826 TrailerBrakeNoEbs_stat 35;
BA_ "Platform_VMCU1_Sig" SG_ 826 TrailerBrakeNoEbs_stat 1;
BA_ "Platform_Vivis2_Sig" SG_ 826 TrailerBrakeNoEbs_stat 1;
BA_ "GenSigCycleTime" SG_ 826 LiftAxle1DirectControl 100;
BA_ "GenSigCycleTimeActive" SG_ 826 LiftAxle1DirectControl 100;
BA_ "GenSigStartValue" SG_ 826 LiftAxle1DirectControl 7;
BA_ "NeedsUpdateBit" SG_ 826 LiftAxle1DirectControl 1;
BA_ "Platform_VMCU1_Sig" SG_ 826 LiftAxle1DirectControl 1;
BA_ "Platform_Vivis2_Sig" SG_ 826 LiftAxle1DirectControl 1;
BA_ "GenSigCycleTime" SG_ 826 DoorsAjar_stat 100;
BA_ "GenSigCycleTimeActive" SG_ 826 DoorsAjar_stat 100;
BA_ "GenSigInactiveValue" SG_ 826 DoorsAjar_stat 7;
BA_ "GenSigStartValue" SG_ 826 DoorsAjar_stat 7;
BA_ "NeedsUpdateBit" SG_ 826 DoorsAjar_stat 1;
BA_ "Platform_VMCU1_Sig" SG_ 826 DoorsAjar_stat 1;
BA_ "Platform_Vivis2_Sig" SG_ 826 DoorsAjar_stat 1;
BA_ "GenSigCycleTime" SG_ 826 BlackOutandConvoyMode_rqst 100;
BA_ "GenSigCycleTimeActive" SG_ 826 BlackOutandConvoyMode_rqst 100;
BA_ "GenSigInactiveValue" SG_ 826 BlackOutandConvoyMode_rqst 7;
BA_ "GenSigStartValue" SG_ 826 BlackOutandConvoyMode_rqst 7;
BA_ "Platform_VMCU1_Sig" SG_ 826 BlackOutandConvoyMode_rqst 1;
BA_ "Platform_Vivis2_Sig" SG_ 826 BlackOutandConvoyMode_rqst 1;
BA_ "GenSigSendType" SG_ 826 DoorsAjar_stat_UB 7;
BA_ "Platform_VMCU1_Sig" SG_ 826 DoorsAjar_stat_UB 1;
BA_ "Platform_Vivis2_Sig" SG_ 826 DoorsAjar_stat_UB 1;
BA_ "GenSigSendType" SG_ 826 LiftAxle1DirectControl_UB 7;
BA_ "Platform_VMCU1_Sig" SG_ 826 LiftAxle1DirectControl_UB 1;
BA_ "Platform_Vivis2_Sig" SG_ 826 LiftAxle1DirectControl_UB 1;
BA_ "GenSigCycleTime" SG_ 826 ECSStandByRequest 100;
BA_ "GenSigCycleTimeActive" SG_ 826 ECSStandByRequest 100;
BA_ "GenSigInactiveValue" SG_ 826 ECSStandByRequest 7;
BA_ "GenSigStartValue" SG_ 826 ECSStandByRequest 7;
BA_ "Platform_VMCU1_Sig" SG_ 826 ECSStandByRequest 1;
BA_ "Platform_Vivis2_Sig" SG_ 826 ECSStandByRequest 1;
BA_ "GenSigCycleTime" SG_ 826 ChassisInstepLight_cmd 100;
BA_ "GenSigCycleTimeActive" SG_ 826 ChassisInstepLight_cmd 100;
BA_ "GenSigStartValue" SG_ 826 ChassisInstepLight_cmd 3;
BA_ "GenSigMaxLatency" SG_ 826 ChassisInstepLight_cmd 35;
BA_ "Platform_VMCU1_Sig" SG_ 826 ChassisInstepLight_cmd 1;
BA_ "Platform_Vivis2_Sig" SG_ 826 ChassisInstepLight_cmd 1;
BA_ "GenSigCycleTime" SG_ 826 BBSlidable5thWheelCmd 100;
BA_ "GenSigCycleTimeActive" SG_ 826 BBSlidable5thWheelCmd 100;
BA_ "GenSigStartValue" SG_ 826 BBSlidable5thWheelCmd 3;
BA_ "GenSigMaxLatency" SG_ 826 BBSlidable5thWheelCmd 35;
BA_ "Platform_VMCU1_Sig" SG_ 826 BBSlidable5thWheelCmd 1;
BA_ "Platform_Vivis2_Sig" SG_ 826 BBSlidable5thWheelCmd 1;
BA_ "GenSigCycleTime" SG_ 826 ParkingBrake_stat 100;
BA_ "GenSigCycleTimeActive" SG_ 826 ParkingBrake_stat 100;
BA_ "GenSigStartValue" SG_ 826 ParkingBrake_stat 3;
BA_ "Platform_Vivis2_Sig" SG_ 826 ParkingBrake_stat 1;
BA_ "GenSigCycleTime" SG_ 826 MaintBatteryReset 100;
BA_ "GenSigCycleTimeActive" SG_ 826 MaintBatteryReset 100;
BA_ "GenSigStartValue" SG_ 826 MaintBatteryReset 3;
BA_ "GenSigMaxLatency" SG_ 826 MaintBatteryReset 35;
BA_ "Platform_VMCU1_Sig" SG_ 826 MaintBatteryReset 1;
BA_ "Platform_Vivis2_Sig" SG_ 826 MaintBatteryReset 1;
BA_ "GenSigCycleTime" SG_ 1369 TotalVehicleDistanceHighRes 100;
BA_ "GenSigCycleTimeActive" SG_ 1369 TotalVehicleDistanceHighRes 100;
BA_ "GenSigStartValue" SG_ 1369 TotalVehicleDistanceHighRes 4294967295;
BA_ "GenSigMaxLatency" SG_ 1369 TotalVehicleDistanceHighRes 511;
BA_ "Platform_VMCU1_Sig" SG_ 1369 TotalVehicleDistanceHighRes 1;
BA_ "Platform_Vivis2_Sig" SG_ 1369 TotalVehicleDistanceHighRes 1;
BA_ "GenSigCycleTime" SG_ 946 TransferCaseOrSplitboxPTOMode 100;
BA_ "GenSigCycleTimeActive" SG_ 946 TransferCaseOrSplitboxPTOMode 100;
BA_ "GenSigStartValue" SG_ 946 TransferCaseOrSplitboxPTOMode 3;
BA_ "GenSigMaxLatency" SG_ 946 TransferCaseOrSplitboxPTOMode 55;
BA_ "Platform_VMCU1_Sig" SG_ 946 TransferCaseOrSplitboxPTOMode 1;
BA_ "Platform_Vivis2_Sig" SG_ 946 TransferCaseOrSplitboxPTOMode 1;
BA_ "GenSigCycleTime" SG_ 946 Pto3Status 100;
BA_ "GenSigCycleTimeActive" SG_ 946 Pto3Status 100;
BA_ "GenSigStartValue" SG_ 946 Pto3Status 3;
BA_ "GenSigMaxLatency" SG_ 946 Pto3Status 55;
BA_ "Platform_VMCU1_Sig" SG_ 946 Pto3Status 1;
BA_ "Platform_Vivis2_Sig" SG_ 946 Pto3Status 1;
BA_ "GenSigCycleTime" SG_ 946 RearAxleDiffLockActvnFuncReq 100;
BA_ "GenSigCycleTimeActive" SG_ 946 RearAxleDiffLockActvnFuncReq 100;
BA_ "GenSigStartValue" SG_ 946 RearAxleDiffLockActvnFuncReq 3;
BA_ "GenSigMaxLatency" SG_ 946 RearAxleDiffLockActvnFuncReq 55;
BA_ "NeedsUpdateBit" SG_ 946 RearAxleDiffLockActvnFuncReq 1;
BA_ "Platform_VMCU1_Sig" SG_ 946 RearAxleDiffLockActvnFuncReq 1;
BA_ "Platform_Vivis2_Sig" SG_ 946 RearAxleDiffLockActvnFuncReq 1;
BA_ "GenSigCycleTime" SG_ 946 Pto1Status 100;
BA_ "GenSigCycleTimeActive" SG_ 946 Pto1Status 100;
BA_ "GenSigStartValue" SG_ 946 Pto1Status 3;
BA_ "GenSigMaxLatency" SG_ 946 Pto1Status 55;
BA_ "Platform_VMCU1_Sig" SG_ 946 Pto1Status 1;
BA_ "Platform_Vivis2_Sig" SG_ 946 Pto1Status 1;
BA_ "GenSigCycleTime" SG_ 946 ReducedLoadMode_stat 100;
BA_ "GenSigCycleTimeActive" SG_ 946 ReducedLoadMode_stat 100;
BA_ "GenSigStartValue" SG_ 946 ReducedLoadMode_stat 3;
BA_ "Platform_VMCU1_Sig" SG_ 946 ReducedLoadMode_stat 1;
BA_ "Platform_Vivis2_Sig" SG_ 946 ReducedLoadMode_stat 1;
BA_ "GenSigSendType" SG_ 946 RearAxleDiffLockActvnFuncReq_UB 7;
BA_ "Platform_VMCU1_Sig" SG_ 946 RearAxleDiffLockActvnFuncReq_UB 1;
BA_ "Platform_Vivis2_Sig" SG_ 946 RearAxleDiffLockActvnFuncReq_UB 1;
BA_ "GenSigCycleTime" SG_ 946 RearAxleDiffLockActvnDrvrReq 100;
BA_ "GenSigCycleTimeActive" SG_ 946 RearAxleDiffLockActvnDrvrReq 100;
BA_ "GenSigStartValue" SG_ 946 RearAxleDiffLockActvnDrvrReq 3;
BA_ "GenSigMaxLatency" SG_ 946 RearAxleDiffLockActvnDrvrReq 55;
BA_ "NeedsUpdateBit" SG_ 946 RearAxleDiffLockActvnDrvrReq 1;
BA_ "Platform_VMCU1_Sig" SG_ 946 RearAxleDiffLockActvnDrvrReq 1;
BA_ "Platform_Vivis2_Sig" SG_ 946 RearAxleDiffLockActvnDrvrReq 1;
BA_ "GenSigSendType" SG_ 946 RearAxleDiffLockActvnDrvrReq_UB 7;
BA_ "Platform_VMCU1_Sig" SG_ 946 RearAxleDiffLockActvnDrvrReq_UB 1;
BA_ "Platform_Vivis2_Sig" SG_ 946 RearAxleDiffLockActvnDrvrReq_UB 1;
BA_ "GenSigCycleTime" SG_ 946 Pto2DrivingRequest 100;
BA_ "GenSigCycleTimeActive" SG_ 946 Pto2DrivingRequest 100;
BA_ "GenSigStartValue" SG_ 946 Pto2DrivingRequest 3;
BA_ "GenSigMaxLatency" SG_ 946 Pto2DrivingRequest 55;
BA_ "Platform_VMCU1_Sig" SG_ 946 Pto2DrivingRequest 1;
BA_ "Platform_Vivis2_Sig" SG_ 946 Pto2DrivingRequest 1;
BA_ "GenSigCycleTime" SG_ 946 RrInterAxlDiffLockActvnFuncReq 100;
BA_ "GenSigCycleTimeActive" SG_ 946 RrInterAxlDiffLockActvnFuncReq 100;
BA_ "GenSigStartValue" SG_ 946 RrInterAxlDiffLockActvnFuncReq 3;
BA_ "Platform_Vivis2_Sig" SG_ 946 RrInterAxlDiffLockActvnFuncReq 1;
BA_ "GenSigSendType" SG_ 946 RrInterAxlDiffLockActvnDrvrReq_U 7;
BA_ "Platform_VMCU1_Sig" SG_ 946 RrInterAxlDiffLockActvnDrvrReq_U 1;
BA_ "Platform_Vivis2_Sig" SG_ 946 RrInterAxlDiffLockActvnDrvrReq_U 1;
BA_ "SystemSignalLongSymbol" SG_ 946 RrInterAxlDiffLockActvnDrvrReq_U "RrInterAxlDiffLockActvnDrvrReq_UB";
BA_ "GenSigCycleTime" SG_ 946 CartridgeChangedDrvrReset_rqst 100;
BA_ "GenSigCycleTimeActive" SG_ 946 CartridgeChangedDrvrReset_rqst 100;
BA_ "GenSigStartValue" SG_ 946 CartridgeChangedDrvrReset_rqst 3;
BA_ "GenSigMaxLatency" SG_ 946 CartridgeChangedDrvrReset_rqst 55;
BA_ "Platform_VMCU1_Sig" SG_ 946 CartridgeChangedDrvrReset_rqst 1;
BA_ "Platform_Vivis2_Sig" SG_ 946 CartridgeChangedDrvrReset_rqst 1;
BA_ "GenSigCycleTime" SG_ 946 RrInterAxlDiffLockActvnDrvrReq 100;
BA_ "GenSigCycleTimeActive" SG_ 946 RrInterAxlDiffLockActvnDrvrReq 100;
BA_ "GenSigStartValue" SG_ 946 RrInterAxlDiffLockActvnDrvrReq 3;
BA_ "GenSigMaxLatency" SG_ 946 RrInterAxlDiffLockActvnDrvrReq 55;
BA_ "NeedsUpdateBit" SG_ 946 RrInterAxlDiffLockActvnDrvrReq 1;
BA_ "Platform_VMCU1_Sig" SG_ 946 RrInterAxlDiffLockActvnDrvrReq 1;
BA_ "Platform_Vivis2_Sig" SG_ 946 RrInterAxlDiffLockActvnDrvrReq 1;
BA_ "GenSigCycleTime" SG_ 946 Pto2Status 100;
BA_ "GenSigCycleTimeActive" SG_ 946 Pto2Status 100;
BA_ "GenSigStartValue" SG_ 946 Pto2Status 3;
BA_ "GenSigMaxLatency" SG_ 946 Pto2Status 55;
BA_ "Platform_VMCU1_Sig" SG_ 946 Pto2Status 1;
BA_ "Platform_Vivis2_Sig" SG_ 946 Pto2Status 1;
BA_ "GenSigCycleTime" SG_ 946 Pto4Status 100;
BA_ "GenSigCycleTimeActive" SG_ 946 Pto4Status 100;
BA_ "GenSigStartValue" SG_ 946 Pto4Status 3;
BA_ "GenSigMaxLatency" SG_ 946 Pto4Status 55;
BA_ "Platform_VMCU1_Sig" SG_ 946 Pto4Status 1;
BA_ "Platform_Vivis2_Sig" SG_ 946 Pto4Status 1;
BA_ "GenSigCycleTime" SG_ 946 Pto1DrivingRequest 100;
BA_ "GenSigCycleTimeActive" SG_ 946 Pto1DrivingRequest 100;
BA_ "GenSigStartValue" SG_ 946 Pto1DrivingRequest 3;
BA_ "GenSigMaxLatency" SG_ 946 Pto1DrivingRequest 55;
BA_ "Platform_VMCU1_Sig" SG_ 946 Pto1DrivingRequest 1;
BA_ "Platform_Vivis2_Sig" SG_ 946 Pto1DrivingRequest 1;
BA_ "GenSigCycleTime" SG_ 945 ActualEngineRetarderPercentTrq 100;
BA_ "GenSigCycleTimeActive" SG_ 945 ActualEngineRetarderPercentTrq 100;
BA_ "GenSigStartValue" SG_ 945 ActualEngineRetarderPercentTrq 255;
BA_ "GenSigMaxLatency" SG_ 945 ActualEngineRetarderPercentTrq 54;
BA_ "Platform_VMCU1_Sig" SG_ 945 ActualEngineRetarderPercentTrq 1;
BA_ "Platform_Vivis2_Sig" SG_ 945 ActualEngineRetarderPercentTrq 1;
BA_ "GenSigCycleTime" SG_ 945 ActualEnginePercentTorque 100;
BA_ "GenSigCycleTimeActive" SG_ 945 ActualEnginePercentTorque 100;
BA_ "GenSigStartValue" SG_ 945 ActualEnginePercentTorque 255;
BA_ "GenSigMaxLatency" SG_ 945 ActualEnginePercentTorque 54;
BA_ "NeedsUpdateBit" SG_ 945 ActualEnginePercentTorque 1;
BA_ "Platform_VMCU1_Sig" SG_ 945 ActualEnginePercentTorque 1;
BA_ "Platform_Vivis2_Sig" SG_ 945 ActualEnginePercentTorque 1;
BA_ "GenSigSendType" SG_ 945 EngineReferenceTorque_UB 7;
BA_ "Platform_VMCU1_Sig" SG_ 945 EngineReferenceTorque_UB 1;
BA_ "Platform_Vivis2_Sig" SG_ 945 EngineReferenceTorque_UB 1;
BA_ "GenSigSendType" SG_ 945 ActualEnginePercentTorque_UB 7;
BA_ "Platform_VMCU1_Sig" SG_ 945 ActualEnginePercentTorque_UB 1;
BA_ "Platform_Vivis2_Sig" SG_ 945 ActualEnginePercentTorque_UB 1;
BA_ "GenSigCycleTime" SG_ 945 NominalFrictionPercentTorque 100;
BA_ "GenSigCycleTimeActive" SG_ 945 NominalFrictionPercentTorque 100;
BA_ "GenSigStartValue" SG_ 945 NominalFrictionPercentTorque 255;
BA_ "GenSigMaxLatency" SG_ 945 NominalFrictionPercentTorque 35;
BA_ "NeedsUpdateBit" SG_ 945 NominalFrictionPercentTorque 1;
BA_ "Platform_VMCU1_Sig" SG_ 945 NominalFrictionPercentTorque 1;
BA_ "Platform_Vivis2_Sig" SG_ 945 NominalFrictionPercentTorque 1;
BA_ "GenSigCycleTime" SG_ 945 EcoRollActiveStatus 100;
BA_ "GenSigCycleTimeActive" SG_ 945 EcoRollActiveStatus 100;
BA_ "GenSigStartValue" SG_ 945 EcoRollActiveStatus 3;
BA_ "Platform_VMCU1_Sig" SG_ 945 EcoRollActiveStatus 1;
BA_ "Platform_Vivis2_Sig" SG_ 945 EcoRollActiveStatus 1;
BA_ "GenSigCycleTime" SG_ 945 EngineReferenceTorque 100;
BA_ "GenSigCycleTimeActive" SG_ 945 EngineReferenceTorque 100;
BA_ "GenSigStartValue" SG_ 945 EngineReferenceTorque 65535;
BA_ "NeedsUpdateBit" SG_ 945 EngineReferenceTorque 1;
BA_ "Platform_VMCU1_Sig" SG_ 945 EngineReferenceTorque 1;
BA_ "Platform_Vivis2_Sig" SG_ 945 EngineReferenceTorque 1;
BA_ "GenSigSendType" SG_ 945 NominalFrictionPercentTorque_UB 7;
BA_ "Platform_VMCU1_Sig" SG_ 945 NominalFrictionPercentTorque_UB 1;
BA_ "Platform_Vivis2_Sig" SG_ 945 NominalFrictionPercentTorque_UB 1;
BA_ "GenSigCycleTime" SG_ 928 RrRrItrWhlDiffLckActvnDrvrReq 100;
BA_ "GenSigCycleTimeActive" SG_ 928 RrRrItrWhlDiffLckActvnDrvrReq 100;
BA_ "GenSigStartValue" SG_ 928 RrRrItrWhlDiffLckActvnDrvrReq 3;
BA_ "NeedsUpdateBit" SG_ 928 RrRrItrWhlDiffLckActvnDrvrReq 1;
BA_ "Platform_Vivis2_Sig" SG_ 928 RrRrItrWhlDiffLckActvnDrvrReq 1;
BA_ "GenSigCycleTime" SG_ 928 EngineSpeed 100;
BA_ "GenSigCycleTimeActive" SG_ 928 EngineSpeed 100;
BA_ "GenSigStartValue" SG_ 928 EngineSpeed 65535;
BA_ "GenSigMaxLatency" SG_ 928 EngineSpeed 54;
BA_ "NeedsUpdateBit" SG_ 928 EngineSpeed 1;
BA_ "Platform_VMCU1_Sig" SG_ 928 EngineSpeed 1;
BA_ "Platform_Vivis2_Sig" SG_ 928 EngineSpeed 1;
BA_ "GenSigCycleTime" SG_ 928 LiftAxle1Request 100;
BA_ "GenSigCycleTimeActive" SG_ 928 LiftAxle1Request 100;
BA_ "GenSigStartValue" SG_ 928 LiftAxle1Request 15;
BA_ "Platform_VMCU1_Sig" SG_ 928 LiftAxle1Request 1;
BA_ "Platform_Vivis2_Sig" SG_ 928 LiftAxle1Request 1;
BA_ "GenSigSendType" SG_ 928 RrRrItrWhlDiffLckActvnDrvrReq_UB 7;
BA_ "Platform_Vivis2_Sig" SG_ 928 RrRrItrWhlDiffLckActvnDrvrReq_UB 1;
BA_ "GenSigSendType" SG_ 928 EngineSpeed_UB 7;
BA_ "Platform_VMCU1_Sig" SG_ 928 EngineSpeed_UB 1;
BA_ "Platform_Vivis2_Sig" SG_ 928 EngineSpeed_UB 1;
BA_ "GenSigCycleTime" SG_ 928 Rear1ClutchRequest 100;
BA_ "GenSigCycleTimeActive" SG_ 928 Rear1ClutchRequest 100;
BA_ "GenSigStartValue" SG_ 928 Rear1ClutchRequest 3;
BA_ "Platform_VMCU1_Sig" SG_ 928 Rear1ClutchRequest 1;
BA_ "Platform_Vivis2_Sig" SG_ 928 Rear1ClutchRequest 1;
BA_ "GenSigCycleTime" SG_ 928 FrontWheelDifflockRequest 100;
BA_ "GenSigCycleTimeActive" SG_ 928 FrontWheelDifflockRequest 100;
BA_ "GenSigStartValue" SG_ 928 FrontWheelDifflockRequest 3;
BA_ "Platform_VMCU1_Sig" SG_ 928 FrontWheelDifflockRequest 1;
BA_ "Platform_Vivis2_Sig" SG_ 928 FrontWheelDifflockRequest 1;
BA_ "GenSigSendType" SG_ 827 FrAxleLeftWheelRelativeSpeed 1;
BA_ "GenSigStartValue" SG_ 827 FrAxleLeftWheelRelativeSpeed 255;
BA_ "GenSigMaxLatency" SG_ 827 FrAxleLeftWheelRelativeSpeed 50;
BA_ "Platform_VMCU1_Sig" SG_ 827 FrAxleLeftWheelRelativeSpeed 1;
BA_ "Platform_Vivis2_Sig" SG_ 827 FrAxleLeftWheelRelativeSpeed 1;
BA_ "GenSigSendType" SG_ 827 FrAxleRightWheelRelativeSpeed 1;
BA_ "GenSigStartValue" SG_ 827 FrAxleRightWheelRelativeSpeed 255;
BA_ "GenSigMaxLatency" SG_ 827 FrAxleRightWheelRelativeSpeed 50;
BA_ "Platform_VMCU1_Sig" SG_ 827 FrAxleRightWheelRelativeSpeed 1;
BA_ "Platform_Vivis2_Sig" SG_ 827 FrAxleRightWheelRelativeSpeed 1;
BA_ "GenSigSendType" SG_ 827 FrontAxleSpeed 1;
BA_ "GenSigStartValue" SG_ 827 FrontAxleSpeed 65535;
BA_ "GenSigMaxLatency" SG_ 827 FrontAxleSpeed 50;
BA_ "Platform_VMCU1_Sig" SG_ 827 FrontAxleSpeed 1;
BA_ "Platform_Vivis2_Sig" SG_ 827 FrontAxleSpeed 1;
BA_ "GenSigCycleTime" SG_ 537 LiftAxle2LiftPositionRequest 100;
BA_ "GenSigCycleTimeActive" SG_ 537 LiftAxle2LiftPositionRequest 100;
BA_ "GenSigStartValue" SG_ 537 LiftAxle2LiftPositionRequest 7;
BA_ "GenSigMaxLatency" SG_ 537 LiftAxle2LiftPositionRequest 29;
BA_ "NeedsUpdateBit" SG_ 537 LiftAxle2LiftPositionRequest 1;
BA_ "Platform_VMCU1_Sig" SG_ 537 LiftAxle2LiftPositionRequest 1;
BA_ "Platform_Vivis2_Sig" SG_ 537 LiftAxle2LiftPositionRequest 1;
BA_ "GenSigCycleTime" SG_ 537 LoadDistributionChangeRequest 100;
BA_ "GenSigCycleTimeActive" SG_ 537 LoadDistributionChangeRequest 100;
BA_ "GenSigStartValue" SG_ 537 LoadDistributionChangeRequest 3;
BA_ "GenSigMaxLatency" SG_ 537 LoadDistributionChangeRequest 29;
BA_ "NeedsUpdateBit" SG_ 537 LoadDistributionChangeRequest 1;
BA_ "Platform_VMCU1_Sig" SG_ 537 LoadDistributionChangeRequest 1;
BA_ "Platform_Vivis2_Sig" SG_ 537 LoadDistributionChangeRequest 1;
BA_ "GenSigCycleTime" SG_ 537 AltLoadDistribution_rqst 100;
BA_ "GenSigCycleTimeActive" SG_ 537 AltLoadDistribution_rqst 100;
BA_ "GenSigStartValue" SG_ 537 AltLoadDistribution_rqst 7;
BA_ "GenSigMaxLatency" SG_ 537 AltLoadDistribution_rqst 29;
BA_ "NeedsUpdateBit" SG_ 537 AltLoadDistribution_rqst 1;
BA_ "Platform_VMCU1_Sig" SG_ 537 AltLoadDistribution_rqst 1;
BA_ "Platform_Vivis2_Sig" SG_ 537 AltLoadDistribution_rqst 1;
BA_ "GenSigCycleTime" SG_ 537 LiftAxle1LiftPositionRequest 100;
BA_ "GenSigCycleTimeActive" SG_ 537 LiftAxle1LiftPositionRequest 100;
BA_ "GenSigStartValue" SG_ 537 LiftAxle1LiftPositionRequest 7;
BA_ "GenSigMaxLatency" SG_ 537 LiftAxle1LiftPositionRequest 29;
BA_ "NeedsUpdateBit" SG_ 537 LiftAxle1LiftPositionRequest 1;
BA_ "Platform_VMCU1_Sig" SG_ 537 LiftAxle1LiftPositionRequest 1;
BA_ "Platform_Vivis2_Sig" SG_ 537 LiftAxle1LiftPositionRequest 1;
BA_ "GenSigSendType" SG_ 537 FerryFunctionRequest_UB 7;
BA_ "Platform_VMCU1_Sig" SG_ 537 FerryFunctionRequest_UB 1;
BA_ "Platform_Vivis2_Sig" SG_ 537 FerryFunctionRequest_UB 1;
BA_ "GenSigCycleTime" SG_ 537 RampLevelRequest 100;
BA_ "GenSigCycleTimeActive" SG_ 537 RampLevelRequest 100;
BA_ "GenSigStartValue" SG_ 537 RampLevelRequest 15;
BA_ "GenSigMaxLatency" SG_ 537 RampLevelRequest 29;
BA_ "Platform_VMCU1_Sig" SG_ 537 RampLevelRequest 1;
BA_ "Platform_Vivis2_Sig" SG_ 537 RampLevelRequest 1;
BA_ "GenSigCycleTime" SG_ 537 RampLevelStorageRequest 100;
BA_ "GenSigCycleTimeActive" SG_ 537 RampLevelStorageRequest 100;
BA_ "GenSigStartValue" SG_ 537 RampLevelStorageRequest 15;
BA_ "GenSigMaxLatency" SG_ 537 RampLevelStorageRequest 29;
BA_ "Platform_VMCU1_Sig" SG_ 537 RampLevelStorageRequest 1;
BA_ "Platform_Vivis2_Sig" SG_ 537 RampLevelStorageRequest 1;
BA_ "GenSigCycleTime" SG_ 537 RideHeightFunctionRequest 100;
BA_ "GenSigCycleTimeActive" SG_ 537 RideHeightFunctionRequest 100;
BA_ "GenSigStartValue" SG_ 537 RideHeightFunctionRequest 15;
BA_ "GenSigMaxLatency" SG_ 537 RideHeightFunctionRequest 29;
BA_ "NeedsUpdateBit" SG_ 537 RideHeightFunctionRequest 1;
BA_ "Platform_VMCU1_Sig" SG_ 537 RideHeightFunctionRequest 1;
BA_ "Platform_Vivis2_Sig" SG_ 537 RideHeightFunctionRequest 1;
BA_ "GenSigCycleTime" SG_ 537 LiftAxle1AutoLiftRequest 100;
BA_ "GenSigCycleTimeActive" SG_ 537 LiftAxle1AutoLiftRequest 100;
BA_ "GenSigStartValue" SG_ 537 LiftAxle1AutoLiftRequest 3;
BA_ "GenSigMaxLatency" SG_ 537 LiftAxle1AutoLiftRequest 29;
BA_ "NeedsUpdateBit" SG_ 537 LiftAxle1AutoLiftRequest 1;
BA_ "Platform_VMCU1_Sig" SG_ 537 LiftAxle1AutoLiftRequest 1;
BA_ "Platform_Vivis2_Sig" SG_ 537 LiftAxle1AutoLiftRequest 1;
BA_ "GenSigCycleTime" SG_ 537 FerryFunctionRequest 100;
BA_ "GenSigCycleTimeActive" SG_ 537 FerryFunctionRequest 100;
BA_ "GenSigStartValue" SG_ 537 FerryFunctionRequest 3;
BA_ "GenSigMaxLatency" SG_ 537 FerryFunctionRequest 29;
BA_ "NeedsUpdateBit" SG_ 537 FerryFunctionRequest 1;
BA_ "Platform_VMCU1_Sig" SG_ 537 FerryFunctionRequest 1;
BA_ "Platform_Vivis2_Sig" SG_ 537 FerryFunctionRequest 1;
BA_ "GenSigSendType" SG_ 537 AltLoadDistribution_rqst_UB 7;
BA_ "Platform_VMCU1_Sig" SG_ 537 AltLoadDistribution_rqst_UB 1;
BA_ "Platform_Vivis2_Sig" SG_ 537 AltLoadDistribution_rqst_UB 1;
BA_ "GenSigCycleTime" SG_ 537 BBSystemKneelRequest 100;
BA_ "GenSigCycleTimeActive" SG_ 537 BBSystemKneelRequest 100;
BA_ "GenSigStartValue" SG_ 537 BBSystemKneelRequest 3;
BA_ "Platform_VMCU1_Sig" SG_ 537 BBSystemKneelRequest 1;
BA_ "Platform_Vivis2_Sig" SG_ 537 BBSystemKneelRequest 1;
BA_ "GenSigCycleTime" SG_ 537 StopLevelChangeRequest 100;
BA_ "GenSigCycleTimeActive" SG_ 537 StopLevelChangeRequest 100;
BA_ "GenSigStartValue" SG_ 537 StopLevelChangeRequest 3;
BA_ "GenSigMaxLatency" SG_ 537 StopLevelChangeRequest 29;
BA_ "Platform_VMCU1_Sig" SG_ 537 StopLevelChangeRequest 1;
BA_ "Platform_Vivis2_Sig" SG_ 537 StopLevelChangeRequest 1;
BA_ "GenSigSendType" SG_ 537 LiftAxle1LiftPositionRequest_UB 7;
BA_ "Platform_VMCU1_Sig" SG_ 537 LiftAxle1LiftPositionRequest_UB 1;
BA_ "Platform_Vivis2_Sig" SG_ 537 LiftAxle1LiftPositionRequest_UB 1;
BA_ "GenSigSendType" SG_ 537 LiftAxle2LiftPositionRequest_UB 7;
BA_ "Platform_VMCU1_Sig" SG_ 537 LiftAxle2LiftPositionRequest_UB 1;
BA_ "Platform_Vivis2_Sig" SG_ 537 LiftAxle2LiftPositionRequest_UB 1;
BA_ "GenSigCycleTime" SG_ 537 FirstAxleLowerPrioRequested 100;
BA_ "GenSigCycleTimeActive" SG_ 537 FirstAxleLowerPrioRequested 100;
BA_ "GenSigStartValue" SG_ 537 FirstAxleLowerPrioRequested 7;
BA_ "NeedsUpdateBit" SG_ 537 FirstAxleLowerPrioRequested 1;
BA_ "Platform_Vivis2_Sig" SG_ 537 FirstAxleLowerPrioRequested 1;
BA_ "GenSigSendType" SG_ 537 LiftAxle1AutoLiftRequest_UB 7;
BA_ "Platform_VMCU1_Sig" SG_ 537 LiftAxle1AutoLiftRequest_UB 1;
BA_ "Platform_Vivis2_Sig" SG_ 537 LiftAxle1AutoLiftRequest_UB 1;
BA_ "GenSigCycleTime" SG_ 537 LiftAxle2AutoLiftRequest 100;
BA_ "GenSigCycleTimeActive" SG_ 537 LiftAxle2AutoLiftRequest 100;
BA_ "GenSigStartValue" SG_ 537 LiftAxle2AutoLiftRequest 3;
BA_ "GenSigMaxLatency" SG_ 537 LiftAxle2AutoLiftRequest 29;
BA_ "NeedsUpdateBit" SG_ 537 LiftAxle2AutoLiftRequest 1;
BA_ "Platform_VMCU1_Sig" SG_ 537 LiftAxle2AutoLiftRequest 1;
BA_ "Platform_Vivis2_Sig" SG_ 537 LiftAxle2AutoLiftRequest 1;
BA_ "GenSigSendType" SG_ 537 LiftAxle2AutoLiftRequest_UB 7;
BA_ "Platform_VMCU1_Sig" SG_ 537 LiftAxle2AutoLiftRequest_UB 1;
BA_ "Platform_Vivis2_Sig" SG_ 537 LiftAxle2AutoLiftRequest_UB 1;
BA_ "GenSigCycleTime" SG_ 537 FerryFunctionSwitchChangeReq 100;
BA_ "GenSigCycleTimeActive" SG_ 537 FerryFunctionSwitchChangeReq 100;
BA_ "GenSigStartValue" SG_ 537 FerryFunctionSwitchChangeReq 3;
BA_ "Platform_VMCU1_Sig" SG_ 537 FerryFunctionSwitchChangeReq 1;
BA_ "Platform_Vivis2_Sig" SG_ 537 FerryFunctionSwitchChangeReq 1;
BA_ "GenSigCycleTime" SG_ 537 LevelStrokeRequest 100;
BA_ "GenSigCycleTimeActive" SG_ 537 LevelStrokeRequest 100;
BA_ "GenSigStartValue" SG_ 537 LevelStrokeRequest 3;
BA_ "GenSigMaxLatency" SG_ 537 LevelStrokeRequest 29;
BA_ "Platform_VMCU1_Sig" SG_ 537 LevelStrokeRequest 1;
BA_ "Platform_Vivis2_Sig" SG_ 537 LevelStrokeRequest 1;
BA_ "GenSigSendType" SG_ 537 BBSystemAlternatLoadDistribReq_U 7;
BA_ "Platform_VMCU1_Sig" SG_ 537 BBSystemAlternatLoadDistribReq_U 1;
BA_ "Platform_Vivis2_Sig" SG_ 537 BBSystemAlternatLoadDistribReq_U 1;
BA_ "SystemSignalLongSymbol" SG_ 537 BBSystemAlternatLoadDistribReq_U "BBSystemAlternatLoadDistribReq_UB";
BA_ "GenSigSendType" SG_ 537 RideHeightFunctionRequest_UB 7;
BA_ "Platform_VMCU1_Sig" SG_ 537 RideHeightFunctionRequest_UB 1;
BA_ "Platform_Vivis2_Sig" SG_ 537 RideHeightFunctionRequest_UB 1;
BA_ "GenSigSendType" SG_ 537 FirstAxleLowerPrioRequested_UB 7;
BA_ "Platform_Vivis2_Sig" SG_ 537 FirstAxleLowerPrioRequested_UB 1;
BA_ "GenSigCycleTime" SG_ 537 BBSystemProhibitControlRequest 100;
BA_ "GenSigCycleTimeActive" SG_ 537 BBSystemProhibitControlRequest 100;
BA_ "GenSigStartValue" SG_ 537 BBSystemProhibitControlRequest 3;
BA_ "Platform_VMCU1_Sig" SG_ 537 BBSystemProhibitControlRequest 1;
BA_ "Platform_Vivis2_Sig" SG_ 537 BBSystemProhibitControlRequest 1;
BA_ "GenSigSendType" SG_ 537 LoadDistributionChangeRequest_UB 7;
BA_ "Platform_VMCU1_Sig" SG_ 537 LoadDistributionChangeRequest_UB 1;
BA_ "Platform_Vivis2_Sig" SG_ 537 LoadDistributionChangeRequest_UB 1;
BA_ "GenSigCycleTime" SG_ 537 BBSystemAlternatLoadDistribReq 100;
BA_ "GenSigCycleTimeActive" SG_ 537 BBSystemAlternatLoadDistribReq 100;
BA_ "GenSigStartValue" SG_ 537 BBSystemAlternatLoadDistribReq 3;
BA_ "NeedsUpdateBit" SG_ 537 BBSystemAlternatLoadDistribReq 1;
BA_ "Platform_VMCU1_Sig" SG_ 537 BBSystemAlternatLoadDistribReq 1;
BA_ "Platform_Vivis2_Sig" SG_ 537 BBSystemAlternatLoadDistribReq 1;
BA_ "GenSigCycleTime" SG_ 537 RideHeightStorageRequest 100;
BA_ "GenSigCycleTimeActive" SG_ 537 RideHeightStorageRequest 100;
BA_ "GenSigStartValue" SG_ 537 RideHeightStorageRequest 15;
BA_ "GenSigMaxLatency" SG_ 537 RideHeightStorageRequest 29;
BA_ "Platform_VMCU1_Sig" SG_ 537 RideHeightStorageRequest 1;
BA_ "Platform_Vivis2_Sig" SG_ 537 RideHeightStorageRequest 1;
BA_ "GenSigCycleTime" SG_ 537 BBSystemSpeedDepDriveLevelReq 100;
BA_ "GenSigCycleTimeActive" SG_ 537 BBSystemSpeedDepDriveLevelReq 100;
BA_ "GenSigStartValue" SG_ 537 BBSystemSpeedDepDriveLevelReq 3;
BA_ "Platform_VMCU1_Sig" SG_ 537 BBSystemSpeedDepDriveLevelReq 1;
BA_ "Platform_Vivis2_Sig" SG_ 537 BBSystemSpeedDepDriveLevelReq 1;
BA_ "GenSigCycleTime" SG_ 531 BackToDriveReq 100;
BA_ "GenSigCycleTimeActive" SG_ 531 BackToDriveReq 100;
BA_ "GenSigStartValue" SG_ 531 BackToDriveReq 3;
BA_ "Platform_VMCU1_Sig" SG_ 531 BackToDriveReq 1;
BA_ "Platform_Vivis2_Sig" SG_ 531 BackToDriveReq 1;
BA_ "GenSigCycleTime" SG_ 531 TrailerBrakePres_rqst 100;
BA_ "GenSigCycleTimeActive" SG_ 531 TrailerBrakePres_rqst 100;
BA_ "GenSigStartValue" SG_ 531 TrailerBrakePres_rqst 255;
BA_ "GenSigMaxLatency" SG_ 531 TrailerBrakePres_rqst 35;
BA_ "NeedsUpdateBit" SG_ 531 TrailerBrakePres_rqst 1;
BA_ "Platform_VMCU1_Sig" SG_ 531 TrailerBrakePres_rqst 1;
BA_ "Platform_Vivis2_Sig" SG_ 531 TrailerBrakePres_rqst 1;
BA_ "GenSigCycleTime" SG_ 531 FogLight_Front_cmd 100;
BA_ "GenSigCycleTimeActive" SG_ 531 FogLight_Front_cmd 100;
BA_ "GenSigStartValue" SG_ 531 FogLight_Front_cmd 3;
BA_ "GenSigMaxLatency" SG_ 531 FogLight_Front_cmd 24;
BA_ "Platform_VMCU1_Sig" SG_ 531 FogLight_Front_cmd 1;
BA_ "Platform_Vivis2_Sig" SG_ 531 FogLight_Front_cmd 1;
BA_ "GenSigSendType" SG_ 531 FrAxleDiffLockActvnDriverRqst_UB 7;
BA_ "Platform_VMCU1_Sig" SG_ 531 FrAxleDiffLockActvnDriverRqst_UB 1;
BA_ "Platform_Vivis2_Sig" SG_ 531 FrAxleDiffLockActvnDriverRqst_UB 1;
BA_ "GenSigCycleTime" SG_ 531 SplitBoxDifflockActvnDrvrRqst 100;
BA_ "GenSigCycleTimeActive" SG_ 531 SplitBoxDifflockActvnDrvrRqst 100;
BA_ "GenSigStartValue" SG_ 531 SplitBoxDifflockActvnDrvrRqst 3;
BA_ "GenSigMaxLatency" SG_ 531 SplitBoxDifflockActvnDrvrRqst 35;
BA_ "NeedsUpdateBit" SG_ 531 SplitBoxDifflockActvnDrvrRqst 1;
BA_ "Platform_VMCU1_Sig" SG_ 531 SplitBoxDifflockActvnDrvrRqst 1;
BA_ "Platform_Vivis2_Sig" SG_ 531 SplitBoxDifflockActvnDrvrRqst 1;
BA_ "GenSigCycleTime" SG_ 531 WS_Washing_cmd 100;
BA_ "GenSigCycleTimeActive" SG_ 531 WS_Washing_cmd 100;
BA_ "GenSigStartValue" SG_ 531 WS_Washing_cmd 3;
BA_ "GenSigMaxLatency" SG_ 531 WS_Washing_cmd 24;
BA_ "Platform_VMCU1_Sig" SG_ 531 WS_Washing_cmd 1;
BA_ "Platform_Vivis2_Sig" SG_ 531 WS_Washing_cmd 1;
BA_ "GenSigCycleTime" SG_ 531 ReverseWarning_rqst 100;
BA_ "GenSigCycleTimeActive" SG_ 531 ReverseWarning_rqst 100;
BA_ "GenSigStartValue" SG_ 531 ReverseWarning_rqst 3;
BA_ "GenSigMaxLatency" SG_ 531 ReverseWarning_rqst 24;
BA_ "Platform_VMCU1_Sig" SG_ 531 ReverseWarning_rqst 1;
BA_ "Platform_Vivis2_Sig" SG_ 531 ReverseWarning_rqst 1;
BA_ "GenSigSendType" SG_ 531 TrailerBrakePres_rqst_UB 7;
BA_ "Platform_VMCU1_Sig" SG_ 531 TrailerBrakePres_rqst_UB 1;
BA_ "Platform_Vivis2_Sig" SG_ 531 TrailerBrakePres_rqst_UB 1;
BA_ "GenSigCycleTime" SG_ 531 FogLight_Rear_cmd 100;
BA_ "GenSigCycleTimeActive" SG_ 531 FogLight_Rear_cmd 100;
BA_ "GenSigStartValue" SG_ 531 FogLight_Rear_cmd 3;
BA_ "GenSigMaxLatency" SG_ 531 FogLight_Rear_cmd 24;
BA_ "Platform_VMCU1_Sig" SG_ 531 FogLight_Rear_cmd 1;
BA_ "Platform_Vivis2_Sig" SG_ 531 FogLight_Rear_cmd 1;
BA_ "GenSigSendType" SG_ 531 SplitBoxDifflockActvnDrvrRqst_UB 7;
BA_ "Platform_VMCU1_Sig" SG_ 531 SplitBoxDifflockActvnDrvrRqst_UB 1;
BA_ "Platform_Vivis2_Sig" SG_ 531 SplitBoxDifflockActvnDrvrRqst_UB 1;
BA_ "GenSigCycleTime" SG_ 531 FrAxleDiffLockActvnDriverRqst 100;
BA_ "GenSigCycleTimeActive" SG_ 531 FrAxleDiffLockActvnDriverRqst 100;
BA_ "GenSigStartValue" SG_ 531 FrAxleDiffLockActvnDriverRqst 3;
BA_ "GenSigMaxLatency" SG_ 531 FrAxleDiffLockActvnDriverRqst 35;
BA_ "NeedsUpdateBit" SG_ 531 FrAxleDiffLockActvnDriverRqst 1;
BA_ "Platform_VMCU1_Sig" SG_ 531 FrAxleDiffLockActvnDriverRqst 1;
BA_ "Platform_Vivis2_Sig" SG_ 531 FrAxleDiffLockActvnDriverRqst 1;
BA_ "GenSigCycleTime" SG_ 392 AcceleratorPedalPosition1 100;
BA_ "GenSigCycleTimeActive" SG_ 392 AcceleratorPedalPosition1 100;
BA_ "GenSigStartValue" SG_ 392 AcceleratorPedalPosition1 255;
BA_ "GenSigMaxLatency" SG_ 392 AcceleratorPedalPosition1 23;
BA_ "Platform_VMCU1_Sig" SG_ 392 AcceleratorPedalPosition1 1;
BA_ "Platform_Vivis2_Sig" SG_ 392 AcceleratorPedalPosition1 1;
BA_ "GenSigCycleTime" SG_ 392 MainBeam_cmd 100;
BA_ "GenSigCycleTimeActive" SG_ 392 MainBeam_cmd 100;
BA_ "GenSigStartValue" SG_ 392 MainBeam_cmd 7;
BA_ "GenSigMaxLatency" SG_ 392 MainBeam_cmd 23;
BA_ "Platform_VMCU1_Sig" SG_ 392 MainBeam_cmd 1;
BA_ "Platform_Vivis2_Sig" SG_ 392 MainBeam_cmd 1;
BA_ "GenSigCycleTime" SG_ 392 DippedBeam_cmd 100;
BA_ "GenSigCycleTimeActive" SG_ 392 DippedBeam_cmd 100;
BA_ "GenSigStartValue" SG_ 392 DippedBeam_cmd 3;
BA_ "GenSigMaxLatency" SG_ 392 DippedBeam_cmd 23;
BA_ "Platform_VMCU1_Sig" SG_ 392 DippedBeam_cmd 1;
BA_ "Platform_Vivis2_Sig" SG_ 392 DippedBeam_cmd 1;
BA_ "GenSigCycleTime" SG_ 392 BrakePedalPosition 100;
BA_ "GenSigCycleTimeActive" SG_ 392 BrakePedalPosition 100;
BA_ "GenSigStartValue" SG_ 392 BrakePedalPosition 255;
BA_ "GenSigMaxLatency" SG_ 392 BrakePedalPosition 23;
BA_ "Platform_VMCU1_Sig" SG_ 392 BrakePedalPosition 1;
BA_ "Platform_Vivis2_Sig" SG_ 392 BrakePedalPosition 1;
BA_ "GenSigCycleTime" SG_ 392 ExtraMainBeam_cmd 100;
BA_ "GenSigCycleTimeActive" SG_ 392 ExtraMainBeam_cmd 100;
BA_ "GenSigStartValue" SG_ 392 ExtraMainBeam_cmd 3;
BA_ "GenSigMaxLatency" SG_ 392 ExtraMainBeam_cmd 35;
BA_ "Platform_VMCU1_Sig" SG_ 392 ExtraMainBeam_cmd 1;
BA_ "Platform_Vivis2_Sig" SG_ 392 ExtraMainBeam_cmd 1;
BA_ "GenSigCycleTime" SG_ 392 Hazard_rqst 100;
BA_ "GenSigCycleTimeActive" SG_ 392 Hazard_rqst 100;
BA_ "GenSigStartValue" SG_ 392 Hazard_rqst 3;
BA_ "GenSigMaxLatency" SG_ 392 Hazard_rqst 23;
BA_ "Platform_VMCU1_Sig" SG_ 392 Hazard_rqst 1;
BA_ "Platform_Vivis2_Sig" SG_ 392 Hazard_rqst 1;
BA_ "GenSigCycleTime" SG_ 392 DirectionIndicatorLights_rqst 100;
BA_ "GenSigCycleTimeActive" SG_ 392 DirectionIndicatorLights_rqst 100;
BA_ "GenSigStartValue" SG_ 392 DirectionIndicatorLights_rqst 7;
BA_ "GenSigMaxLatency" SG_ 392 DirectionIndicatorLights_rqst 23;
BA_ "Platform_VMCU1_Sig" SG_ 392 DirectionIndicatorLights_rqst 1;
BA_ "Platform_Vivis2_Sig" SG_ 392 DirectionIndicatorLights_rqst 1;
BA_ "GenSigCycleTime" SG_ 392 DRL_cmd 100;
BA_ "GenSigCycleTimeActive" SG_ 392 DRL_cmd 100;
BA_ "GenSigStartValue" SG_ 392 DRL_cmd 3;
BA_ "GenSigMaxLatency" SG_ 392 DRL_cmd 23;
BA_ "Platform_VMCU1_Sig" SG_ 392 DRL_cmd 1;
BA_ "Platform_Vivis2_Sig" SG_ 392 DRL_cmd 1;
BA_ "GenSigCycleTime" SG_ 392 DirectionIndicatorLights_cmd 100;
BA_ "GenSigCycleTimeActive" SG_ 392 DirectionIndicatorLights_cmd 100;
BA_ "GenSigStartValue" SG_ 392 DirectionIndicatorLights_cmd 7;
BA_ "GenSigMaxLatency" SG_ 392 DirectionIndicatorLights_cmd 23;
BA_ "Platform_VMCU1_Sig" SG_ 392 DirectionIndicatorLights_cmd 1;
BA_ "Platform_Vivis2_Sig" SG_ 392 DirectionIndicatorLights_cmd 1;
BA_ "GenSigCycleTime" SG_ 392 PositionLight_cmd 100;
BA_ "GenSigCycleTimeActive" SG_ 392 PositionLight_cmd 100;
BA_ "GenSigStartValue" SG_ 392 PositionLight_cmd 3;
BA_ "GenSigMaxLatency" SG_ 392 PositionLight_cmd 24;
BA_ "Platform_VMCU1_Sig" SG_ 392 PositionLight_cmd 1;
BA_ "Platform_Vivis2_Sig" SG_ 392 PositionLight_cmd 1;
BA_ "GenSigCycleTime" SG_ 392 StaticCornerLight_cmd 100;
BA_ "GenSigCycleTimeActive" SG_ 392 StaticCornerLight_cmd 100;
BA_ "GenSigInactiveValue" SG_ 392 StaticCornerLight_cmd 7;
BA_ "GenSigStartValue" SG_ 392 StaticCornerLight_cmd 7;
BA_ "Platform_VMCU1_Sig" SG_ 392 StaticCornerLight_cmd 1;
BA_ "Platform_Vivis2_Sig" SG_ 392 StaticCornerLight_cmd 1;
BA_ "GenSigCycleTime" SG_ 392 WorkingLightChassisOutp_cmd 100;
BA_ "GenSigCycleTimeActive" SG_ 392 WorkingLightChassisOutp_cmd 100;
BA_ "GenSigStartValue" SG_ 392 WorkingLightChassisOutp_cmd 3;
BA_ "Platform_VMCU1_Sig" SG_ 392 WorkingLightChassisOutp_cmd 1;
BA_ "Platform_Vivis2_Sig" SG_ 392 WorkingLightChassisOutp_cmd 1;
BA_ "GenSigCycleTime" SG_ 895 ApproachLight_FrontRqst 100;
BA_ "GenSigCycleTimeActive" SG_ 895 ApproachLight_FrontRqst 100;
BA_ "GenSigStartValue" SG_ 895 ApproachLight_FrontRqst 3;
BA_ "GenSigCycleTime" SG_ 895 EASTagLiftAxleLoweringInhibit 100;
BA_ "GenSigCycleTimeActive" SG_ 895 EASTagLiftAxleLoweringInhibit 100;
BA_ "GenSigStartValue" SG_ 895 EASTagLiftAxleLoweringInhibit 3;
BA_ "GenSigCycleTime" SG_ 895 WheelBasedVehicleSpeed 100;
BA_ "GenSigCycleTimeActive" SG_ 895 WheelBasedVehicleSpeed 100;
BA_ "GenSigStartValue" SG_ 895 WheelBasedVehicleSpeed 65535;
BA_ "GenSigMaxLatency" SG_ 895 WheelBasedVehicleSpeed 50;
BA_ "GenSigCycleTime" SG_ 895 FrRrItrWhlDiffLckActvnDrvrReq 100;
BA_ "GenSigCycleTimeActive" SG_ 895 FrRrItrWhlDiffLckActvnDrvrReq 100;
BA_ "GenSigStartValue" SG_ 895 FrRrItrWhlDiffLckActvnDrvrReq 3;
BA_ "GenSigCycleTime" SG_ 895 ApproachLight_RearandSideRqst 100;
BA_ "GenSigCycleTimeActive" SG_ 895 ApproachLight_RearandSideRqst 100;
BA_ "GenSigStartValue" SG_ 895 ApproachLight_RearandSideRqst 3;
BA_ "GenSigCycleTime" SG_ 895 ApproachLight_HLAnimationcmd 100;
BA_ "GenSigCycleTimeActive" SG_ 895 ApproachLight_HLAnimationcmd 100;
BA_ "GenSigStartValue" SG_ 895 ApproachLight_HLAnimationcmd 3;
BA_ "GenSigCycleTime" SG_ 895 TransmissionSelectedGear 100;
BA_ "GenSigCycleTimeActive" SG_ 895 TransmissionSelectedGear 100;
BA_ "GenSigStartValue" SG_ 895 TransmissionSelectedGear 255;
BA_ "GenSigMaxLatency" SG_ 895 TransmissionSelectedGear 50;
BA_ "GenSigCycleTime" SG_ 895 TransmissionCurrentGear 100;
BA_ "GenSigCycleTimeActive" SG_ 895 TransmissionCurrentGear 100;
BA_ "GenSigStartValue" SG_ 895 TransmissionCurrentGear 255;
BA_ "GenSigMaxLatency" SG_ 895 TransmissionCurrentGear 50;
BA_ "GenSigCycleTime" SG_ 895 TransmEngineCrankEnable 100;
BA_ "GenSigCycleTimeActive" SG_ 895 TransmEngineCrankEnable 100;
BA_ "GenSigStartValue" SG_ 895 TransmEngineCrankEnable 3;
BA_ "GenSigMaxLatency" SG_ 895 TransmEngineCrankEnable 50;
BA_ "GenSigCycleTime" SG_ 895 TransmEngineCrankEnable2 100;
BA_ "GenSigCycleTimeActive" SG_ 895 TransmEngineCrankEnable2 100;
BA_ "GenSigStartValue" SG_ 895 TransmEngineCrankEnable2 3;
BA_ "GenSigMaxLatency" SG_ 895 TransmEngineCrankEnable2 50;
BA_ "GenSigCycleTime" SG_ 588 VehicleMode 100;
BA_ "GenSigCycleTimeActive" SG_ 588 VehicleMode 100;
BA_ "GenSigStartValue" SG_ 588 VehicleMode 15;
BA_ "GenSigMaxLatency" SG_ 588 VehicleMode 20;
BA_ "GenSigCycleTime" SG_ 588 TransmissionDrivelineEngaged 100;
BA_ "GenSigCycleTimeActive" SG_ 588 TransmissionDrivelineEngaged 100;
BA_ "GenSigStartValue" SG_ 588 TransmissionDrivelineEngaged 3;
BA_ "GenSigMaxLatency" SG_ 588 TransmissionDrivelineEngaged 20;
BA_ "GenSigCycleTime" SG_ 588 SecuredNeutralPosition 100;
BA_ "GenSigCycleTimeActive" SG_ 588 SecuredNeutralPosition 100;
BA_ "GenSigStartValue" SG_ 588 SecuredNeutralPosition 3;
BA_ "GenSigMaxLatency" SG_ 588 SecuredNeutralPosition 20;
BA_ "GenSigCycleTime" SG_ 588 GearLeverPosition 100;
BA_ "GenSigCycleTimeActive" SG_ 588 GearLeverPosition 100;
BA_ "GenSigStartValue" SG_ 588 GearLeverPosition 15;
BA_ "GenSigMaxLatency" SG_ 588 GearLeverPosition 20;
BA_ "GenSigCycleTime" SG_ 588 EngineActiveStatus 100;
BA_ "GenSigCycleTimeActive" SG_ 588 EngineActiveStatus 100;
BA_ "GenSigStartValue" SG_ 588 EngineActiveStatus 15;
BA_ "GenSigMaxLatency" SG_ 588 EngineActiveStatus 20;
BA_ "GenSigSendType" SG_ 2671902706 FuncDiagDataTester 7;
BA_ "GenSigSendType" SG_ 2671902708 FuncDiagDataIntTesterF4 7;
BA_ "GenSigCycleTime" SG_ 957 TrlrDirIndRightOutputStat_12V 100;
BA_ "GenSigCycleTimeActive" SG_ 957 TrlrDirIndRightOutputStat_12V 100;
BA_ "GenSigStartValue" SG_ 957 TrlrDirIndRightOutputStat_12V 7;
BA_ "GenSigMaxLatency" SG_ 957 TrlrDirIndRightOutputStat_12V 100;
BA_ "Platform_Vivis2_Sig" SG_ 957 TrlrDirIndRightOutputStat_12V 1;
BA_ "GenSigCycleTime" SG_ 957 TrailerBrakeLightOutputStat12V 100;
BA_ "GenSigCycleTimeActive" SG_ 957 TrailerBrakeLightOutputStat12V 100;
BA_ "GenSigStartValue" SG_ 957 TrailerBrakeLightOutputStat12V 7;
BA_ "GenSigMaxLatency" SG_ 957 TrailerBrakeLightOutputStat12V 100;
BA_ "Platform_Vivis2_Sig" SG_ 957 TrailerBrakeLightOutputStat12V 1;
BA_ "GenSigCycleTime" SG_ 957 TrailerDirIndLightRequested12V 100;
BA_ "GenSigCycleTimeActive" SG_ 957 TrailerDirIndLightRequested12V 100;
BA_ "GenSigStartValue" SG_ 957 TrailerDirIndLightRequested12V 3;
BA_ "GenSigMaxLatency" SG_ 957 TrailerDirIndLightRequested12V 100;
BA_ "Platform_Vivis2_Sig" SG_ 957 TrailerDirIndLightRequested12V 1;
BA_ "GenSigCycleTime" SG_ 957 TD_BrakeLightsPulseRsp_12V 100;
BA_ "GenSigCycleTimeActive" SG_ 957 TD_BrakeLightsPulseRsp_12V 100;
BA_ "GenSigStartValue" SG_ 957 TD_BrakeLightsPulseRsp_12V 7;
BA_ "GenSigMaxLatency" SG_ 957 TD_BrakeLightsPulseRsp_12V 100;
BA_ "Platform_Vivis2_Sig" SG_ 957 TD_BrakeLightsPulseRsp_12V 1;
BA_ "GenSigCycleTime" SG_ 957 TD_DirInLgtPlsRsp_12V_Right 100;
BA_ "GenSigCycleTimeActive" SG_ 957 TD_DirInLgtPlsRsp_12V_Right 100;
BA_ "GenSigStartValue" SG_ 957 TD_DirInLgtPlsRsp_12V_Right 7;
BA_ "GenSigMaxLatency" SG_ 957 TD_DirInLgtPlsRsp_12V_Right 100;
BA_ "Platform_Vivis2_Sig" SG_ 957 TD_DirInLgtPlsRsp_12V_Right 1;
BA_ "GenSigCycleTime" SG_ 957 TrailerBrakeLightsRequested12V 100;
BA_ "GenSigCycleTimeActive" SG_ 957 TrailerBrakeLightsRequested12V 100;
BA_ "GenSigStartValue" SG_ 957 TrailerBrakeLightsRequested12V 3;
BA_ "GenSigMaxLatency" SG_ 957 TrailerBrakeLightsRequested12V 100;
BA_ "Platform_Vivis2_Sig" SG_ 957 TrailerBrakeLightsRequested12V 1;
BA_ "GenSigCycleTime" SG_ 957 TrailerPos2OutputStat_12V 100;
BA_ "GenSigCycleTimeActive" SG_ 957 TrailerPos2OutputStat_12V 100;
BA_ "GenSigStartValue" SG_ 957 TrailerPos2OutputStat_12V 7;
BA_ "GenSigMaxLatency" SG_ 957 TrailerPos2OutputStat_12V 100;
BA_ "Platform_Vivis2_Sig" SG_ 957 TrailerPos2OutputStat_12V 1;
BA_ "GenSigCycleTime" SG_ 957 TD_PosLghtPlsRsp12V_Pos2 100;
BA_ "GenSigCycleTimeActive" SG_ 957 TD_PosLghtPlsRsp12V_Pos2 100;
BA_ "GenSigStartValue" SG_ 957 TD_PosLghtPlsRsp12V_Pos2 7;
BA_ "GenSigMaxLatency" SG_ 957 TD_PosLghtPlsRsp12V_Pos2 100;
BA_ "Platform_Vivis2_Sig" SG_ 957 TD_PosLghtPlsRsp12V_Pos2 1;
BA_ "GenSigCycleTime" SG_ 957 TrailerConnected_12VABSCurrent 100;
BA_ "GenSigCycleTimeActive" SG_ 957 TrailerConnected_12VABSCurrent 100;
BA_ "GenSigStartValue" SG_ 957 TrailerConnected_12VABSCurrent 3;
BA_ "GenSigMaxLatency" SG_ 957 TrailerConnected_12VABSCurrent 100;
BA_ "Platform_Vivis2_Sig" SG_ 957 TrailerConnected_12VABSCurrent 1;
BA_ "GenSigCycleTime" SG_ 957 TrailerPosLightRequested12V 100;
BA_ "GenSigCycleTimeActive" SG_ 957 TrailerPosLightRequested12V 100;
BA_ "GenSigStartValue" SG_ 957 TrailerPosLightRequested12V 3;
BA_ "GenSigMaxLatency" SG_ 957 TrailerPosLightRequested12V 100;
BA_ "Platform_Vivis2_Sig" SG_ 957 TrailerPosLightRequested12V 1;
BA_ "GenSigCycleTime" SG_ 957 TD_PosLghtPlsRsp12V_Pos1 100;
BA_ "GenSigCycleTimeActive" SG_ 957 TD_PosLghtPlsRsp12V_Pos1 100;
BA_ "GenSigStartValue" SG_ 957 TD_PosLghtPlsRsp12V_Pos1 7;
BA_ "GenSigMaxLatency" SG_ 957 TD_PosLghtPlsRsp12V_Pos1 100;
BA_ "Platform_Vivis2_Sig" SG_ 957 TD_PosLghtPlsRsp12V_Pos1 1;
BA_ "GenSigCycleTime" SG_ 957 TrlrDirIndLeftOutputStat_12V 100;
BA_ "GenSigCycleTimeActive" SG_ 957 TrlrDirIndLeftOutputStat_12V 100;
BA_ "GenSigStartValue" SG_ 957 TrlrDirIndLeftOutputStat_12V 7;
BA_ "GenSigMaxLatency" SG_ 957 TrlrDirIndLeftOutputStat_12V 100;
BA_ "Platform_Vivis2_Sig" SG_ 957 TrlrDirIndLeftOutputStat_12V 1;
BA_ "GenSigCycleTime" SG_ 957 TrailerPos1OutputStat_12V 100;
BA_ "GenSigCycleTimeActive" SG_ 957 TrailerPos1OutputStat_12V 100;
BA_ "GenSigStartValue" SG_ 957 TrailerPos1OutputStat_12V 7;
BA_ "GenSigMaxLatency" SG_ 957 TrailerPos1OutputStat_12V 100;
BA_ "Platform_Vivis2_Sig" SG_ 957 TrailerPos1OutputStat_12V 1;
BA_ "GenSigCycleTime" SG_ 957 TD_DirInLgtPlsRsp_12V_Left 100;
BA_ "GenSigCycleTimeActive" SG_ 957 TD_DirInLgtPlsRsp_12V_Left 100;
BA_ "GenSigStartValue" SG_ 957 TD_DirInLgtPlsRsp_12V_Left 7;
BA_ "GenSigMaxLatency" SG_ 957 TD_DirInLgtPlsRsp_12V_Left 100;
BA_ "Platform_Vivis2_Sig" SG_ 957 TD_DirInLgtPlsRsp_12V_Left 1;
BA_ "GenSigCycleTime" SG_ 958 TD_LghtPlsReqBrk12V_Status 100;
BA_ "GenSigCycleTimeActive" SG_ 958 TD_LghtPlsReqBrk12V_Status 100;
BA_ "GenSigStartValue" SG_ 958 TD_LghtPlsReqBrk12V_Status 3;
BA_ "GenSigMaxLatency" SG_ 958 TD_LghtPlsReqBrk12V_Status 100;
BA_ "Platform_Vivis2_Sig" SG_ 958 TD_LghtPlsReqBrk12V_Status 1;
BA_ "GenSigCycleTime" SG_ 958 TD_LghtPlsReqDir12V_Right 100;
BA_ "GenSigCycleTimeActive" SG_ 958 TD_LghtPlsReqDir12V_Right 100;
BA_ "GenSigMaxLatency" SG_ 958 TD_LghtPlsReqDir12V_Right 100;
BA_ "Platform_Vivis2_Sig" SG_ 958 TD_LghtPlsReqDir12V_Right 1;
BA_ "GenSigCycleTime" SG_ 958 TD_LghtPlsReqDir12V_Status 100;
BA_ "GenSigCycleTimeActive" SG_ 958 TD_LghtPlsReqDir12V_Status 100;
BA_ "GenSigStartValue" SG_ 958 TD_LghtPlsReqDir12V_Status 3;
BA_ "GenSigMaxLatency" SG_ 958 TD_LghtPlsReqDir12V_Status 100;
BA_ "Platform_Vivis2_Sig" SG_ 958 TD_LghtPlsReqDir12V_Status 1;
BA_ "GenSigCycleTime" SG_ 958 TD_LightsResetReq_12V 100;
BA_ "GenSigCycleTimeActive" SG_ 958 TD_LightsResetReq_12V 100;
BA_ "GenSigStartValue" SG_ 958 TD_LightsResetReq_12V 3;
BA_ "GenSigMaxLatency" SG_ 958 TD_LightsResetReq_12V 100;
BA_ "Platform_Vivis2_Sig" SG_ 958 TD_LightsResetReq_12V 1;
BA_ "GenSigCycleTime" SG_ 958 TD_LghtPlsReqPos12V_Status 100;
BA_ "GenSigCycleTimeActive" SG_ 958 TD_LghtPlsReqPos12V_Status 100;
BA_ "GenSigStartValue" SG_ 958 TD_LghtPlsReqPos12V_Status 3;
BA_ "GenSigMaxLatency" SG_ 958 TD_LghtPlsReqPos12V_Status 100;
BA_ "Platform_Vivis2_Sig" SG_ 958 TD_LghtPlsReqPos12V_Status 1;
BA_ "GenSigCycleTime" SG_ 958 TD_LghtPlsReqBrk12V_Brake 100;
BA_ "GenSigCycleTimeActive" SG_ 958 TD_LghtPlsReqBrk12V_Brake 100;
BA_ "GenSigMaxLatency" SG_ 958 TD_LghtPlsReqBrk12V_Brake 100;
BA_ "Platform_Vivis2_Sig" SG_ 958 TD_LghtPlsReqBrk12V_Brake 1;
BA_ "GenSigCycleTime" SG_ 958 TrailerConnectedType 100;
BA_ "GenSigCycleTimeActive" SG_ 958 TrailerConnectedType 100;
BA_ "GenSigStartValue" SG_ 958 TrailerConnectedType 3;
BA_ "Platform_Vivis2_Sig" SG_ 958 TrailerConnectedType 1;
BA_ "GenSigCycleTime" SG_ 958 ECSManStandbyStatus 100;
BA_ "GenSigCycleTimeActive" SG_ 958 ECSManStandbyStatus 100;
BA_ "GenSigStartValue" SG_ 958 ECSManStandbyStatus 3;
BA_ "Platform_Vivis2_Sig" SG_ 958 ECSManStandbyStatus 1;
BA_ "GenSigCycleTime" SG_ 958 TrailerLightsConnected_12V 100;
BA_ "GenSigCycleTimeActive" SG_ 958 TrailerLightsConnected_12V 100;
BA_ "GenSigStartValue" SG_ 958 TrailerLightsConnected_12V 3;
BA_ "GenSigMaxLatency" SG_ 958 TrailerLightsConnected_12V 100;
BA_ "Platform_Vivis2_Sig" SG_ 958 TrailerLightsConnected_12V 1;
BA_ "GenSigCycleTime" SG_ 958 TD_LghtPlsReqDir12V_Left 100;
BA_ "GenSigCycleTimeActive" SG_ 958 TD_LghtPlsReqDir12V_Left 100;
BA_ "GenSigMaxLatency" SG_ 958 TD_LghtPlsReqDir12V_Left 100;
BA_ "Platform_Vivis2_Sig" SG_ 958 TD_LghtPlsReqDir12V_Left 1;
BA_ "GenSigCycleTime" SG_ 958 TD_LghtPlsReqPos12V_Pos2 100;
BA_ "GenSigCycleTimeActive" SG_ 958 TD_LghtPlsReqPos12V_Pos2 100;
BA_ "GenSigMaxLatency" SG_ 958 TD_LghtPlsReqPos12V_Pos2 100;
BA_ "Platform_Vivis2_Sig" SG_ 958 TD_LghtPlsReqPos12V_Pos2 1;
BA_ "GenSigCycleTime" SG_ 958 TD_LghtPlsReqPos12V_Pos1 100;
BA_ "GenSigCycleTimeActive" SG_ 958 TD_LghtPlsReqPos12V_Pos1 100;
BA_ "GenSigMaxLatency" SG_ 958 TD_LghtPlsReqPos12V_Pos1 100;
BA_ "Platform_Vivis2_Sig" SG_ 958 TD_LghtPlsReqPos12V_Pos1 1;
BA_ "GenSigCycleTime" SG_ 958 ECSPreconForSWDL_NegStatInfo 100;
BA_ "GenSigCycleTimeActive" SG_ 958 ECSPreconForSWDL_NegStatInfo 100;
BA_ "GenSigStartValue" SG_ 958 ECSPreconForSWDL_NegStatInfo 7;
BA_ "GenSigMaxLatency" SG_ 958 ECSPreconForSWDL_NegStatInfo 100;
BA_ "Platform_Vivis2_Sig" SG_ 958 ECSPreconForSWDL_NegStatInfo 1;
BA_ "GenSigCycleTime" SG_ 958 ECSPreconForSWDL_Status 100;
BA_ "GenSigCycleTimeActive" SG_ 958 ECSPreconForSWDL_Status 100;
BA_ "GenSigStartValue" SG_ 958 ECSPreconForSWDL_Status 3;
BA_ "GenSigMaxLatency" SG_ 958 ECSPreconForSWDL_Status 100;
BA_ "Platform_Vivis2_Sig" SG_ 958 ECSPreconForSWDL_Status 1;
BA_ "GenSigCycleTime" SG_ 1517 RearDriveAxle2Temperature 100;
BA_ "GenSigCycleTimeActive" SG_ 1517 RearDriveAxle2Temperature 100;
BA_ "GenSigStartValue" SG_ 1517 RearDriveAxle2Temperature 255;
BA_ "Platform_Vivis2_Sig" SG_ 1517 RearDriveAxle2Temperature 1;
BA_ "GenSigCycleTime" SG_ 1517 RearDriveAxle1Temperature 100;
BA_ "GenSigCycleTimeActive" SG_ 1517 RearDriveAxle1Temperature 100;
BA_ "GenSigStartValue" SG_ 1517 RearDriveAxle1Temperature 255;
BA_ "Platform_Vivis2_Sig" SG_ 1517 RearDriveAxle1Temperature 1;
BA_ "GenSigCycleTime" SG_ 1517 RearDriveAxle3Temperature 100;
BA_ "GenSigCycleTimeActive" SG_ 1517 RearDriveAxle3Temperature 100;
BA_ "GenSigStartValue" SG_ 1517 RearDriveAxle3Temperature 255;
BA_ "Platform_Vivis2_Sig" SG_ 1517 RearDriveAxle3Temperature 1;
BA_ "GenSigCycleTime" SG_ 676 RearAxle3DiffLock_stat 100;
BA_ "GenSigCycleTimeActive" SG_ 676 RearAxle3DiffLock_stat 100;
BA_ "GenSigStartValue" SG_ 676 RearAxle3DiffLock_stat 3;
BA_ "NeedsUpdateBit" SG_ 676 RearAxle3DiffLock_stat 1;
BA_ "Platform_Vivis2_Sig" SG_ 676 RearAxle3DiffLock_stat 1;
BA_ "GenSigSendType" SG_ 676 RearAxle3DiffLock_stat_UB 7;
BA_ "Platform_Vivis2_Sig" SG_ 676 RearAxle3DiffLock_stat_UB 1;
BA_ "GenSigCycleTime" SG_ 676 LeftBrakeAndDirInd_cmd 100;
BA_ "GenSigCycleTimeActive" SG_ 676 LeftBrakeAndDirInd_cmd 100;
BA_ "GenSigStartValue" SG_ 676 LeftBrakeAndDirInd_cmd 3;
BA_ "Platform_Vivis2_Sig" SG_ 676 LeftBrakeAndDirInd_cmd 1;
BA_ "GenSigCycleTime" SG_ 676 RightBrakeAndDirInd_cmd 100;
BA_ "GenSigCycleTimeActive" SG_ 676 RightBrakeAndDirInd_cmd 100;
BA_ "GenSigStartValue" SG_ 676 RightBrakeAndDirInd_cmd 3;
BA_ "Platform_Vivis2_Sig" SG_ 676 RightBrakeAndDirInd_cmd 1;
BA_ "GenSigCycleTime" SG_ 676 RevWarning_cmd 100;
BA_ "GenSigCycleTimeActive" SG_ 676 RevWarning_cmd 100;
BA_ "GenSigStartValue" SG_ 676 RevWarning_cmd 3;
BA_ "Platform_Vivis2_Sig" SG_ 676 RevWarning_cmd 1;
BA_ "GenSigCycleTime" SG_ 1349 TertiaryDriveAxleLoad 100;
BA_ "GenSigCycleTimeActive" SG_ 1349 TertiaryDriveAxleLoad 100;
BA_ "GenSigStartValue" SG_ 1349 TertiaryDriveAxleLoad 65535;
BA_ "Platform_Vivis2_Sig" SG_ 1349 TertiaryDriveAxleLoad 1;
BA_ "GenSigCycleTime" SG_ 1349 LastDriveAxleBellowPressure 100;
BA_ "GenSigCycleTimeActive" SG_ 1349 LastDriveAxleBellowPressure 100;
BA_ "GenSigStartValue" SG_ 1349 LastDriveAxleBellowPressure 65535;
BA_ "Platform_Vivis2_Sig" SG_ 1349 LastDriveAxleBellowPressure 1;
BA_ "GenSigCycleTime" SG_ 1349 SuspensionSpeedLimitRequest 100;
BA_ "GenSigCycleTimeActive" SG_ 1349 SuspensionSpeedLimitRequest 100;
BA_ "GenSigStartValue" SG_ 1349 SuspensionSpeedLimitRequest 65535;
BA_ "Platform_Vivis2_Sig" SG_ 1349 SuspensionSpeedLimitRequest 1;
BA_ "GenSigCycleTime" SG_ 1349 RearAxleGroupLoad 100;
BA_ "GenSigCycleTimeActive" SG_ 1349 RearAxleGroupLoad 100;
BA_ "GenSigStartValue" SG_ 1349 RearAxleGroupLoad 65535;
BA_ "Platform_Vivis2_Sig" SG_ 1349 RearAxleGroupLoad 1;
BA_ "GenSigCycleTime" SG_ 951 DumpSwitchChangeAck 100;
BA_ "GenSigCycleTimeActive" SG_ 951 DumpSwitchChangeAck 100;
BA_ "GenSigStartValue" SG_ 951 DumpSwitchChangeAck 3;
BA_ "Platform_Vivis2_Sig" SG_ 951 DumpSwitchChangeAck 1;
BA_ "GenSigCycleTime" SG_ 951 HeadlightAngleAuto_rqst 100;
BA_ "GenSigCycleTimeActive" SG_ 951 HeadlightAngleAuto_rqst 100;
BA_ "GenSigStartValue" SG_ 951 HeadlightAngleAuto_rqst 255;
BA_ "Platform_Vivis2_Sig" SG_ 951 HeadlightAngleAuto_rqst 1;
BA_ "GenSigCycleTime" SG_ 951 RelativeLevelRearAxleLeftRaw 100;
BA_ "GenSigCycleTimeActive" SG_ 951 RelativeLevelRearAxleLeftRaw 100;
BA_ "GenSigStartValue" SG_ 951 RelativeLevelRearAxleLeftRaw 65535;
BA_ "Platform_Vivis2_Sig" SG_ 951 RelativeLevelRearAxleLeftRaw 1;
BA_ "GenSigCycleTime" SG_ 951 FrontDumpFunctionCmd 100;
BA_ "GenSigCycleTimeActive" SG_ 951 FrontDumpFunctionCmd 100;
BA_ "GenSigStartValue" SG_ 951 FrontDumpFunctionCmd 7;
BA_ "Platform_Vivis2_Sig" SG_ 951 FrontDumpFunctionCmd 1;
BA_ "GenSigCycleTime" SG_ 951 RelativeLevelRearAxleRightRaw 100;
BA_ "GenSigCycleTimeActive" SG_ 951 RelativeLevelRearAxleRightRaw 100;
BA_ "GenSigStartValue" SG_ 951 RelativeLevelRearAxleRightRaw 65535;
BA_ "Platform_Vivis2_Sig" SG_ 951 RelativeLevelRearAxleRightRaw 1;
BA_ "GenSigCycleTime" SG_ 1344 TagAxleLoad 100;
BA_ "GenSigCycleTimeActive" SG_ 1344 TagAxleLoad 100;
BA_ "GenSigStartValue" SG_ 1344 TagAxleLoad 65535;
BA_ "GenSigMaxLatency" SG_ 1344 TagAxleLoad 255;
BA_ "NeedsUpdateBit" SG_ 1344 TagAxleLoad 1;
BA_ "Platform_VMCU1_Sig" SG_ 1344 TagAxleLoad 1;
BA_ "Platform_Vivis2_Sig" SG_ 1344 TagAxleLoad 1;
BA_ "GenSigCycleTime" SG_ 1344 MegaValveUpdateCounter 100;
BA_ "GenSigCycleTimeActive" SG_ 1344 MegaValveUpdateCounter 100;
BA_ "GenSigStartValue" SG_ 1344 MegaValveUpdateCounter 255;
BA_ "Platform_Vivis2_Sig" SG_ 1344 MegaValveUpdateCounter 1;
BA_ "GenSigCycleTime" SG_ 1344 RegenInhibitVehicleHeight 100;
BA_ "GenSigCycleTimeActive" SG_ 1344 RegenInhibitVehicleHeight 100;
BA_ "GenSigStartValue" SG_ 1344 RegenInhibitVehicleHeight 3;
BA_ "Platform_VMCU1_Sig" SG_ 1344 RegenInhibitVehicleHeight 1;
BA_ "Platform_Vivis2_Sig" SG_ 1344 RegenInhibitVehicleHeight 1;
BA_ "GenSigCycleTime" SG_ 1344 RearLeftRoadVibrationIndex 100;
BA_ "GenSigCycleTimeActive" SG_ 1344 RearLeftRoadVibrationIndex 100;
BA_ "GenSigStartValue" SG_ 1344 RearLeftRoadVibrationIndex 65535;
BA_ "Platform_VMCU1_Sig" SG_ 1344 RearLeftRoadVibrationIndex 1;
BA_ "Platform_Vivis2_Sig" SG_ 1344 RearLeftRoadVibrationIndex 1;
BA_ "GenSigSendType" SG_ 1344 TagAxleLoad_UB 7;
BA_ "Platform_VMCU1_Sig" SG_ 1344 TagAxleLoad_UB 1;
BA_ "Platform_Vivis2_Sig" SG_ 1344 TagAxleLoad_UB 1;
BA_ "GenSigCycleTime" SG_ 1344 SavedHeightControlMode 100;
BA_ "GenSigCycleTimeActive" SG_ 1344 SavedHeightControlMode 100;
BA_ "GenSigStartValue" SG_ 1344 SavedHeightControlMode 3;
BA_ "Platform_Vivis2_Sig" SG_ 1344 SavedHeightControlMode 1;
BA_ "GenSigSendType" SG_ 1344 PusherAxleLoad_UB 7;
BA_ "Platform_VMCU1_Sig" SG_ 1344 PusherAxleLoad_UB 1;
BA_ "Platform_Vivis2_Sig" SG_ 1344 PusherAxleLoad_UB 1;
BA_ "GenSigCycleTime" SG_ 1344 PusherAxleLoad 100;
BA_ "GenSigCycleTimeActive" SG_ 1344 PusherAxleLoad 100;
BA_ "GenSigStartValue" SG_ 1344 PusherAxleLoad 65535;
BA_ "GenSigMaxLatency" SG_ 1344 PusherAxleLoad 255;
BA_ "NeedsUpdateBit" SG_ 1344 PusherAxleLoad 1;
BA_ "Platform_VMCU1_Sig" SG_ 1344 PusherAxleLoad 1;
BA_ "Platform_Vivis2_Sig" SG_ 1344 PusherAxleLoad 1;
BA_REL_ "GenSigFirstTimeoutTime" BU_SG_REL_ CCIOM SG_ 1361 Set_LG6CutoffValue 12000;
BA_REL_ "GenSigTimeoutTime" BU_SG_REL_ CCIOM SG_ 1361 Set_LG6CutoffValue 3000;
BA_REL_ "GenSigFirstTimeoutTime" BU_SG_REL_ CCIOM SG_ 1361 Set_LG1CutoffValue 12000;
BA_REL_ "GenSigTimeoutTime" BU_SG_REL_ CCIOM SG_ 1361 Set_LG1CutoffValue 3000;
BA_REL_ "GenSigFirstTimeoutTime" BU_SG_REL_ CCIOM SG_ 1361 Set_LG3CutoffValue 12000;
BA_REL_ "GenSigTimeoutTime" BU_SG_REL_ CCIOM SG_ 1361 Set_LG3CutoffValue 3000;
BA_REL_ "GenSigFirstTimeoutTime" BU_SG_REL_ CCIOM SG_ 1361 Set_LG5CutoffValue 12000;
BA_REL_ "GenSigTimeoutTime" BU_SG_REL_ CCIOM SG_ 1361 Set_LG5CutoffValue 3000;
BA_REL_ "GenSigFirstTimeoutTime" BU_SG_REL_ CCIOM SG_ 1361 Set_LG4CutoffValue 12000;
BA_REL_ "GenSigTimeoutTime" BU_SG_REL_ CCIOM SG_ 1361 Set_LG4CutoffValue 3000;
BA_REL_ "GenSigFirstTimeoutTime" BU_SG_REL_ CCIOM SG_ 1361 Set_LG2CutoffValue 12000;
BA_REL_ "GenSigTimeoutTime" BU_SG_REL_ CCIOM SG_ 1361 Set_LG2CutoffValue 3000;
BA_REL_ "GenSigFirstTimeoutTime" BU_SG_REL_ CCIOM SG_ 1361 Set_EnergySetting 12000;
BA_REL_ "GenSigTimeoutTime" BU_SG_REL_ CCIOM SG_ 1361 Set_EnergySetting 3000;
BA_REL_ "GenSigFirstTimeoutTime" BU_SG_REL_ CCIOM SG_ 1267 KingPinUnlockCmd_CRC 3000;
BA_REL_ "GenSigTimeoutTime" BU_SG_REL_ CCIOM SG_ 1267 KingPinUnlockCmd_CRC 600;
BA_REL_ "GenSigFirstTimeoutTime" BU_SG_REL_ CCIOM SG_ 1267 AirIntakeSolenoidValve_cmd 3000;
BA_REL_ "GenSigTimeoutTime" BU_SG_REL_ CCIOM SG_ 1267 AirIntakeSolenoidValve_cmd 600;
BA_REL_ "GenSigFirstTimeoutTime" BU_SG_REL_ RCIOM SG_ 1267 TransmissionActualGearRatio 3000;
BA_REL_ "GenSigTimeoutTime" BU_SG_REL_ RCIOM SG_ 1267 TransmissionActualGearRatio 600;
BA_REL_ "GenSigFirstTimeoutTime" BU_SG_REL_ CCIOM SG_ 1267 KingPinUnlockCmd_SqC 3000;
BA_REL_ "GenSigTimeoutTime" BU_SG_REL_ CCIOM SG_ 1267 KingPinUnlockCmd_SqC 600;
BA_REL_ "GenSigFirstTimeoutTime" BU_SG_REL_ CCIOM SG_ 1267 KingPinUnlockCmd_Rqst 3000;
BA_REL_ "GenSigTimeoutTime" BU_SG_REL_ CCIOM SG_ 1267 KingPinUnlockCmd_Rqst 600;
BA_REL_ "GenSigFirstTimeoutTime" BU_SG_REL_ RCIOM SG_ 1267 PreventECSFuncForSWDL_rqst 3000;
BA_REL_ "GenSigTimeoutTime" BU_SG_REL_ RCIOM SG_ 1267 PreventECSFuncForSWDL_rqst 600;
BA_REL_ "GenSigFirstTimeoutTime" BU_SG_REL_ CCIOM SG_ 1267 AutoShutOffAnswerInput 3000;
BA_REL_ "GenSigTimeoutTime" BU_SG_REL_ CCIOM SG_ 1267 AutoShutOffAnswerInput 600;
BA_REL_ "GenSigFirstTimeoutTime" BU_SG_REL_ RCIOM SG_ 954 DumpSwitchChangeReq 3000;
BA_REL_ "GenSigTimeoutTime" BU_SG_REL_ RCIOM SG_ 954 DumpSwitchChangeReq 600;
BA_REL_ "GenSigFirstTimeoutTime" BU_SG_REL_ FCIOM SG_ 954 CAHighBeamFlash_cmd 3000;
BA_REL_ "GenSigTimeoutTime" BU_SG_REL_ FCIOM SG_ 954 CAHighBeamFlash_cmd 600;
BA_REL_ "GenSigFirstTimeoutTime" BU_SG_REL_ FCIOM SG_ 954 HeadLampDeicingControl_rqst 3000;
BA_REL_ "GenSigTimeoutTime" BU_SG_REL_ FCIOM SG_ 954 HeadLampDeicingControl_rqst 600;
BA_REL_ "GenSigFirstTimeoutTime" BU_SG_REL_ CCIOM SG_ 677 EngineStarterMode 3000;
BA_REL_ "GenSigTimeoutTime" BU_SG_REL_ CCIOM SG_ 677 EngineStarterMode 120;
BA_REL_ "GenSigFirstTimeoutTime" BU_SG_REL_ CCIOM SG_ 1363 PredeliveryModeIndication_cmd 24000;
BA_REL_ "GenSigTimeoutTime" BU_SG_REL_ CCIOM SG_ 1363 PredeliveryModeIndication_cmd 6000;
BA_REL_ "GenSigFirstTimeoutTime" BU_SG_REL_ FCIOM SG_ 535 DirectionIndicatorLightsStatus 3000;
BA_REL_ "GenSigTimeoutTime" BU_SG_REL_ FCIOM SG_ 535 DirectionIndicatorLightsStatus 180;
BA_REL_ "GenSigFirstTimeoutTime" BU_SG_REL_ RCIOM SG_ 535 DirectionIndicatorLightsStatus 3000;
BA_REL_ "GenSigTimeoutTime" BU_SG_REL_ RCIOM SG_ 535 DirectionIndicatorLightsStatus 180;
BA_REL_ "GenSigFirstTimeoutTime" BU_SG_REL_ FCIOM SG_ 535 HeadlightAngle_cmd 3000;
BA_REL_ "GenSigTimeoutTime" BU_SG_REL_ FCIOM SG_ 535 HeadlightAngle_cmd 180;
BA_REL_ "GenSigFirstTimeoutTime" BU_SG_REL_ CCIOM SG_ 1381 BattEnergySetLevel_input 12000;
BA_REL_ "GenSigTimeoutTime" BU_SG_REL_ CCIOM SG_ 1381 BattEnergySetLevel_input 3000;
BA_REL_ "GenSigFirstTimeoutTime" BU_SG_REL_ FCIOM SG_ 1381 AmbientAirTemperature 12000;
BA_REL_ "GenSigTimeoutTime" BU_SG_REL_ FCIOM SG_ 1381 AmbientAirTemperature 6000;
BA_REL_ "GenSigFirstTimeoutTime" BU_SG_REL_ BPMU SG_ 1381 AmbientAirTemperature 12000;
BA_REL_ "GenSigTimeoutTime" BU_SG_REL_ BPMU SG_ 1381 AmbientAirTemperature 3000;
BA_REL_ "GenSigFirstTimeoutTime" BU_SG_REL_ RCIOM SG_ 1381 AmbientAirTemperature 12000;
BA_REL_ "GenSigTimeoutTime" BU_SG_REL_ RCIOM SG_ 1381 AmbientAirTemperature 6000;
BA_REL_ "GenSigFirstTimeoutTime" BU_SG_REL_ CCIOM SG_ 1381 AmbientAirTemperature 12000;
BA_REL_ "GenSigTimeoutTime" BU_SG_REL_ CCIOM SG_ 1381 AmbientAirTemperature 3000;
BA_REL_ "GenSigFirstTimeoutTime" BU_SG_REL_ CCIOM SG_ 1381 EnergyForNextCrank 12000;
BA_REL_ "GenSigTimeoutTime" BU_SG_REL_ CCIOM SG_ 1381 EnergyForNextCrank 3000;
BA_REL_ "GenSigFirstTimeoutTime" BU_SG_REL_ CCIOM SG_ 1381 MainBatteryResetPos 12000;
BA_REL_ "GenSigTimeoutTime" BU_SG_REL_ CCIOM SG_ 1381 MainBatteryResetPos 3000;
BA_REL_ "GenSigFirstTimeoutTime" BU_SG_REL_ FCIOM SG_ 519 GlareFreeArea02_LeftAngle 3000;
BA_REL_ "GenSigTimeoutTime" BU_SG_REL_ FCIOM SG_ 519 GlareFreeArea02_LeftAngle 120;
BA_REL_ "GenSigFirstTimeoutTime" BU_SG_REL_ FCIOM SG_ 519 AdaptiveMainBeamRight_cmd 3000;
BA_REL_ "GenSigTimeoutTime" BU_SG_REL_ FCIOM SG_ 519 AdaptiveMainBeamRight_cmd 120;
BA_REL_ "GenSigFirstTimeoutTime" BU_SG_REL_ FCIOM SG_ 519 AdaptiveMainBeamLeft_cmd 3000;
BA_REL_ "GenSigTimeoutTime" BU_SG_REL_ FCIOM SG_ 519 AdaptiveMainBeamLeft_cmd 120;
BA_REL_ "GenSigFirstTimeoutTime" BU_SG_REL_ FCIOM SG_ 519 GlareFreeArea02_Distance 3000;
BA_REL_ "GenSigTimeoutTime" BU_SG_REL_ FCIOM SG_ 519 GlareFreeArea02_Distance 120;
BA_REL_ "GenSigFirstTimeoutTime" BU_SG_REL_ FCIOM SG_ 519 GlareFreeArea02_RightAngle 3000;
BA_REL_ "GenSigTimeoutTime" BU_SG_REL_ FCIOM SG_ 519 GlareFreeArea02_RightAngle 120;
BA_REL_ "GenSigFirstTimeoutTime" BU_SG_REL_ FCIOM SG_ 518 GlareFreeArea03_Distance 3000;
BA_REL_ "GenSigTimeoutTime" BU_SG_REL_ FCIOM SG_ 518 GlareFreeArea03_Distance 120;
BA_REL_ "GenSigFirstTimeoutTime" BU_SG_REL_ FCIOM SG_ 518 GlareFreeArea01_Distance 3000;
BA_REL_ "GenSigTimeoutTime" BU_SG_REL_ FCIOM SG_ 518 GlareFreeArea01_Distance 120;
BA_REL_ "GenSigFirstTimeoutTime" BU_SG_REL_ FCIOM SG_ 518 GlareFreeArea01_LeftAngle 3000;
BA_REL_ "GenSigTimeoutTime" BU_SG_REL_ FCIOM SG_ 518 GlareFreeArea01_LeftAngle 120;
BA_REL_ "GenSigFirstTimeoutTime" BU_SG_REL_ FCIOM SG_ 518 GlareFreeArea03_RightAngle 3000;
BA_REL_ "GenSigTimeoutTime" BU_SG_REL_ FCIOM SG_ 518 GlareFreeArea03_RightAngle 120;
BA_REL_ "GenSigFirstTimeoutTime" BU_SG_REL_ FCIOM SG_ 518 GlareFreeArea03_LeftAngle 3000;
BA_REL_ "GenSigTimeoutTime" BU_SG_REL_ FCIOM SG_ 518 GlareFreeArea03_LeftAngle 120;
BA_REL_ "GenSigFirstTimeoutTime" BU_SG_REL_ FCIOM SG_ 518 GlareFreeArea01_RightAngle 3000;
BA_REL_ "GenSigTimeoutTime" BU_SG_REL_ FCIOM SG_ 518 GlareFreeArea01_RightAngle 120;
BA_REL_ "GenSigFirstTimeoutTime" BU_SG_REL_ RCIOM SG_ 1249 TransferCasePTOEngaged 3000;
BA_REL_ "GenSigTimeoutTime" BU_SG_REL_ RCIOM SG_ 1249 TransferCasePTOEngaged 600;
BA_REL_ "GenSigFirstTimeoutTime" BU_SG_REL_ RCIOM SG_ 1249 EhrasTagAxleLoweringInhibit 3000;
BA_REL_ "GenSigTimeoutTime" BU_SG_REL_ RCIOM SG_ 1249 EhrasTagAxleLoweringInhibit 600;
BA_REL_ "GenSigFirstTimeoutTime" BU_SG_REL_ RCIOM SG_ 1249 ExtECSRequestPressureUpdate 3000;
BA_REL_ "GenSigTimeoutTime" BU_SG_REL_ RCIOM SG_ 1249 ExtECSRequestPressureUpdate 600;
BA_REL_ "GenSigFirstTimeoutTime" BU_SG_REL_ FCIOM SG_ 1249 HeadLampFanControl_rqst 3000;
BA_REL_ "GenSigTimeoutTime" BU_SG_REL_ FCIOM SG_ 1249 HeadLampFanControl_rqst 600;
BA_REL_ "GenSigFirstTimeoutTime" BU_SG_REL_ RCIOM SG_ 1249 BBAirDumpRequest 3000;
BA_REL_ "GenSigTimeoutTime" BU_SG_REL_ RCIOM SG_ 1249 BBAirDumpRequest 600;
BA_REL_ "GenSigFirstTimeoutTime" BU_SG_REL_ RCIOM SG_ 1249 ApproachLight_rqst 3000;
BA_REL_ "GenSigTimeoutTime" BU_SG_REL_ RCIOM SG_ 1249 ApproachLight_rqst 600;
BA_REL_ "GenSigFirstTimeoutTime" BU_SG_REL_ CCIOM SG_ 1249 FrAxle2WheelDriveRequest 3000;
BA_REL_ "GenSigTimeoutTime" BU_SG_REL_ CCIOM SG_ 1249 FrAxle2WheelDriveRequest 600;
BA_REL_ "GenSigFirstTimeoutTime" BU_SG_REL_ RCIOM SG_ 1249 EhrasPusherAxleLoweringInhibit 3000;
BA_REL_ "GenSigTimeoutTime" BU_SG_REL_ RCIOM SG_ 1249 EhrasPusherAxleLoweringInhibit 600;
BA_REL_ "GenSigFirstTimeoutTime" BU_SG_REL_ CCIOM SG_ 1249 LivBatteryChargingStat_rqst 3000;
BA_REL_ "GenSigTimeoutTime" BU_SG_REL_ CCIOM SG_ 1249 LivBatteryChargingStat_rqst 600;
BA_REL_ "GenSigFirstTimeoutTime" BU_SG_REL_ CCIOM SG_ 1249 ClutchSwitch2Stat 3000;
BA_REL_ "GenSigTimeoutTime" BU_SG_REL_ CCIOM SG_ 1249 ClutchSwitch2Stat 600;
BA_REL_ "GenSigFirstTimeoutTime" BU_SG_REL_ CCIOM SG_ 1249 SideMarkersLights_cmd 3000;
BA_REL_ "GenSigTimeoutTime" BU_SG_REL_ CCIOM SG_ 1249 SideMarkersLights_cmd 600;
BA_REL_ "GenSigFirstTimeoutTime" BU_SG_REL_ RCIOM SG_ 1249 BBEcsForceStandstillFilterReq 3000;
BA_REL_ "GenSigTimeoutTime" BU_SG_REL_ RCIOM SG_ 1249 BBEcsForceStandstillFilterReq 600;
BA_REL_ "GenSigFirstTimeoutTime" BU_SG_REL_ CCIOM SG_ 1249 BBEcsForceStandstillFilterReq 3000;
BA_REL_ "GenSigTimeoutTime" BU_SG_REL_ CCIOM SG_ 1249 BBEcsForceStandstillFilterReq 600;
BA_REL_ "GenSigFirstTimeoutTime" BU_SG_REL_ CCIOM SG_ 944 ShortStopHeater_cmd 3000;
BA_REL_ "GenSigTimeoutTime" BU_SG_REL_ CCIOM SG_ 944 ShortStopHeater_cmd 300;
BA_REL_ "GenSigFirstTimeoutTime" BU_SG_REL_ RCIOM SG_ 944 LoadDistributionRequested 3000;
BA_REL_ "GenSigTimeoutTime" BU_SG_REL_ RCIOM SG_ 944 LoadDistributionRequested 500;
BA_REL_ "GenSigFirstTimeoutTime" BU_SG_REL_ CCIOM SG_ 390 FrontAxleRightWheelSpeed_UB 3000;
BA_REL_ "GenSigTimeoutTime" BU_SG_REL_ CCIOM SG_ 390 FrontAxleRightWheelSpeed_UB 60;
BA_REL_ "GenSigFirstTimeoutTime" BU_SG_REL_ FCIOM SG_ 390 CityHorn_cmd 3000;
BA_REL_ "GenSigTimeoutTime" BU_SG_REL_ FCIOM SG_ 390 CityHorn_cmd 500;
BA_REL_ "GenSigFirstTimeoutTime" BU_SG_REL_ CCIOM SG_ 390 BrakeSwitch 3000;
BA_REL_ "GenSigTimeoutTime" BU_SG_REL_ CCIOM SG_ 390 BrakeSwitch 60;
BA_REL_ "GenSigFirstTimeoutTime" BU_SG_REL_ RCIOM SG_ 390 LevelRequest_FrontAxle 3000;
BA_REL_ "GenSigTimeoutTime" BU_SG_REL_ RCIOM SG_ 390 LevelRequest_FrontAxle 500;
BA_REL_ "GenSigFirstTimeoutTime" BU_SG_REL_ CCIOM SG_ 390 FrontAxleRightWheelSpeed 3000;
BA_REL_ "GenSigTimeoutTime" BU_SG_REL_ CCIOM SG_ 390 FrontAxleRightWheelSpeed 500;
BA_REL_ "GenSigFirstTimeoutTime" BU_SG_REL_ CCIOM SG_ 390 FrontAxleLeftWheelSpeed 3000;
BA_REL_ "GenSigTimeoutTime" BU_SG_REL_ CCIOM SG_ 390 FrontAxleLeftWheelSpeed 500;
BA_REL_ "GenSigFirstTimeoutTime" BU_SG_REL_ RCIOM SG_ 390 FPBRChangeReq 3000;
BA_REL_ "GenSigTimeoutTime" BU_SG_REL_ RCIOM SG_ 390 FPBRChangeReq 60;
BA_REL_ "GenSigFirstTimeoutTime" BU_SG_REL_ FCIOM SG_ 390 AuxiliaryHorn_cmd 3000;
BA_REL_ "GenSigTimeoutTime" BU_SG_REL_ FCIOM SG_ 390 AuxiliaryHorn_cmd 500;
BA_REL_ "GenSigFirstTimeoutTime" BU_SG_REL_ RCIOM SG_ 390 LevelRequest_RearAxle 3000;
BA_REL_ "GenSigTimeoutTime" BU_SG_REL_ RCIOM SG_ 390 LevelRequest_RearAxle 500;
BA_REL_ "GenSigFirstTimeoutTime" BU_SG_REL_ RCIOM SG_ 390 LevelRequest_RollRequest 3000;
BA_REL_ "GenSigTimeoutTime" BU_SG_REL_ RCIOM SG_ 390 LevelRequest_RollRequest 500;
BA_REL_ "GenSigFirstTimeoutTime" BU_SG_REL_ CCIOM SG_ 390 FrontAxleLeftWheelSpeed_UB 3000;
BA_REL_ "GenSigTimeoutTime" BU_SG_REL_ CCIOM SG_ 390 FrontAxleLeftWheelSpeed_UB 60;
BA_REL_ "GenSigFirstTimeoutTime" BU_SG_REL_ CCIOM SG_ 389 FrontWheelDriveRequest 3000;
BA_REL_ "GenSigTimeoutTime" BU_SG_REL_ CCIOM SG_ 389 FrontWheelDriveRequest 60;
BA_REL_ "GenSigFirstTimeoutTime" BU_SG_REL_ RCIOM SG_ 389 RearAxleLeftWheelSpeed 3000;
BA_REL_ "GenSigTimeoutTime" BU_SG_REL_ RCIOM SG_ 389 RearAxleLeftWheelSpeed 500;
BA_REL_ "GenSigFirstTimeoutTime" BU_SG_REL_ CCIOM SG_ 389 RearAxleLeftWheelSpeed 3000;
BA_REL_ "GenSigTimeoutTime" BU_SG_REL_ CCIOM SG_ 389 RearAxleLeftWheelSpeed 500;
BA_REL_ "GenSigFirstTimeoutTime" BU_SG_REL_ RCIOM SG_ 389 RearAxleRightWheelSpeed 3000;
BA_REL_ "GenSigTimeoutTime" BU_SG_REL_ RCIOM SG_ 389 RearAxleRightWheelSpeed 500;
BA_REL_ "GenSigFirstTimeoutTime" BU_SG_REL_ CCIOM SG_ 389 RearAxleRightWheelSpeed 3000;
BA_REL_ "GenSigTimeoutTime" BU_SG_REL_ CCIOM SG_ 389 RearAxleRightWheelSpeed 500;
BA_REL_ "GenSigFirstTimeoutTime" BU_SG_REL_ RCIOM SG_ 389 KneelingChangeRequest 3000;
BA_REL_ "GenSigTimeoutTime" BU_SG_REL_ RCIOM SG_ 389 KneelingChangeRequest 120;
BA_REL_ "GenSigFirstTimeoutTime" BU_SG_REL_ FCIOM SG_ 1364 HoursUTC 6000;
BA_REL_ "GenSigTimeoutTime" BU_SG_REL_ FCIOM SG_ 1364 HoursUTC 1500;
BA_REL_ "GenSigFirstTimeoutTime" BU_SG_REL_ RCIOM SG_ 1364 HoursUTC 6000;
BA_REL_ "GenSigTimeoutTime" BU_SG_REL_ RCIOM SG_ 1364 HoursUTC 1500;
BA_REL_ "GenSigFirstTimeoutTime" BU_SG_REL_ CCIOM SG_ 1364 HoursUTC 6000;
BA_REL_ "GenSigTimeoutTime" BU_SG_REL_ CCIOM SG_ 1364 HoursUTC 1500;
BA_REL_ "GenSigFirstTimeoutTime" BU_SG_REL_ BPMU SG_ 1364 HoursUTC 6000;
BA_REL_ "GenSigTimeoutTime" BU_SG_REL_ BPMU SG_ 1364 HoursUTC 1500;
BA_REL_ "GenSigFirstTimeoutTime" BU_SG_REL_ RCIOM SG_ 1364 RoadInclination 6000;
BA_REL_ "GenSigTimeoutTime" BU_SG_REL_ RCIOM SG_ 1364 RoadInclination 1500;
BA_REL_ "GenSigFirstTimeoutTime" BU_SG_REL_ BPMU SG_ 1364 MonthUTC 6000;
BA_REL_ "GenSigTimeoutTime" BU_SG_REL_ BPMU SG_ 1364 MonthUTC 1500;
BA_REL_ "GenSigFirstTimeoutTime" BU_SG_REL_ RCIOM SG_ 1364 MonthUTC 6000;
BA_REL_ "GenSigTimeoutTime" BU_SG_REL_ RCIOM SG_ 1364 MonthUTC 1500;
BA_REL_ "GenSigFirstTimeoutTime" BU_SG_REL_ FCIOM SG_ 1364 MonthUTC 6000;
BA_REL_ "GenSigTimeoutTime" BU_SG_REL_ FCIOM SG_ 1364 MonthUTC 1500;
BA_REL_ "GenSigFirstTimeoutTime" BU_SG_REL_ CCIOM SG_ 1364 MonthUTC 6000;
BA_REL_ "GenSigTimeoutTime" BU_SG_REL_ CCIOM SG_ 1364 MonthUTC 1500;
BA_REL_ "GenSigFirstTimeoutTime" BU_SG_REL_ CCIOM SG_ 1364 YearUTC 6000;
BA_REL_ "GenSigTimeoutTime" BU_SG_REL_ CCIOM SG_ 1364 YearUTC 1500;
BA_REL_ "GenSigFirstTimeoutTime" BU_SG_REL_ FCIOM SG_ 1364 YearUTC 6000;
BA_REL_ "GenSigTimeoutTime" BU_SG_REL_ FCIOM SG_ 1364 YearUTC 1500;
BA_REL_ "GenSigFirstTimeoutTime" BU_SG_REL_ RCIOM SG_ 1364 YearUTC 6000;
BA_REL_ "GenSigTimeoutTime" BU_SG_REL_ RCIOM SG_ 1364 YearUTC 1500;
BA_REL_ "GenSigFirstTimeoutTime" BU_SG_REL_ BPMU SG_ 1364 YearUTC 6000;
BA_REL_ "GenSigTimeoutTime" BU_SG_REL_ BPMU SG_ 1364 YearUTC 1500;
BA_REL_ "GenSigFirstTimeoutTime" BU_SG_REL_ RCIOM SG_ 1364 SecondsUTC 6000;
BA_REL_ "GenSigTimeoutTime" BU_SG_REL_ RCIOM SG_ 1364 SecondsUTC 1500;
BA_REL_ "GenSigFirstTimeoutTime" BU_SG_REL_ FCIOM SG_ 1364 SecondsUTC 6000;
BA_REL_ "GenSigTimeoutTime" BU_SG_REL_ FCIOM SG_ 1364 SecondsUTC 1500;
BA_REL_ "GenSigFirstTimeoutTime" BU_SG_REL_ BPMU SG_ 1364 SecondsUTC 6000;
BA_REL_ "GenSigTimeoutTime" BU_SG_REL_ BPMU SG_ 1364 SecondsUTC 1500;
BA_REL_ "GenSigFirstTimeoutTime" BU_SG_REL_ CCIOM SG_ 1364 SecondsUTC 6000;
BA_REL_ "GenSigTimeoutTime" BU_SG_REL_ CCIOM SG_ 1364 SecondsUTC 1500;
BA_REL_ "GenSigFirstTimeoutTime" BU_SG_REL_ RCIOM SG_ 1364 DayUTC 6000;
BA_REL_ "GenSigTimeoutTime" BU_SG_REL_ RCIOM SG_ 1364 DayUTC 1500;
BA_REL_ "GenSigFirstTimeoutTime" BU_SG_REL_ CCIOM SG_ 1364 DayUTC 6000;
BA_REL_ "GenSigTimeoutTime" BU_SG_REL_ CCIOM SG_ 1364 DayUTC 1500;
BA_REL_ "GenSigFirstTimeoutTime" BU_SG_REL_ FCIOM SG_ 1364 DayUTC 6000;
BA_REL_ "GenSigTimeoutTime" BU_SG_REL_ FCIOM SG_ 1364 DayUTC 1500;
BA_REL_ "GenSigFirstTimeoutTime" BU_SG_REL_ BPMU SG_ 1364 DayUTC 6000;
BA_REL_ "GenSigTimeoutTime" BU_SG_REL_ BPMU SG_ 1364 DayUTC 1500;
BA_REL_ "GenSigFirstTimeoutTime" BU_SG_REL_ BPMU SG_ 1364 MinutesUTC 6000;
BA_REL_ "GenSigTimeoutTime" BU_SG_REL_ BPMU SG_ 1364 MinutesUTC 1500;
BA_REL_ "GenSigFirstTimeoutTime" BU_SG_REL_ CCIOM SG_ 1364 MinutesUTC 6000;
BA_REL_ "GenSigTimeoutTime" BU_SG_REL_ CCIOM SG_ 1364 MinutesUTC 1500;
BA_REL_ "GenSigFirstTimeoutTime" BU_SG_REL_ RCIOM SG_ 1364 MinutesUTC 6000;
BA_REL_ "GenSigTimeoutTime" BU_SG_REL_ RCIOM SG_ 1364 MinutesUTC 1500;
BA_REL_ "GenSigFirstTimeoutTime" BU_SG_REL_ FCIOM SG_ 1364 MinutesUTC 6000;
BA_REL_ "GenSigTimeoutTime" BU_SG_REL_ FCIOM SG_ 1364 MinutesUTC 1500;
BA_REL_ "GenSigFirstTimeoutTime" BU_SG_REL_ CCIOM SG_ 826 BBContUnlockCmd 3000;
BA_REL_ "GenSigTimeoutTime" BU_SG_REL_ CCIOM SG_ 826 BBContUnlockCmd 180;
BA_REL_ "GenSigFirstTimeoutTime" BU_SG_REL_ FCIOM SG_ 826 LampCheck_cmd 3000;
BA_REL_ "GenSigTimeoutTime" BU_SG_REL_ FCIOM SG_ 826 LampCheck_cmd 180;
BA_REL_ "GenSigFirstTimeoutTime" BU_SG_REL_ RCIOM SG_ 826 LampCheck_rqst 3000;
BA_REL_ "GenSigTimeoutTime" BU_SG_REL_ RCIOM SG_ 826 LampCheck_rqst 180;
BA_REL_ "GenSigFirstTimeoutTime" BU_SG_REL_ CCIOM SG_ 826 BatteryCapacity 3000;
BA_REL_ "GenSigTimeoutTime" BU_SG_REL_ CCIOM SG_ 826 BatteryCapacity 180;
BA_REL_ "GenSigFirstTimeoutTime" BU_SG_REL_ CCIOM SG_ 826 AreaInhibit 3000;
BA_REL_ "GenSigTimeoutTime" BU_SG_REL_ CCIOM SG_ 826 AreaInhibit 180;
BA_REL_ "GenSigFirstTimeoutTime" BU_SG_REL_ FCIOM SG_ 826 LEDAnimation_cmd 3000;
BA_REL_ "GenSigTimeoutTime" BU_SG_REL_ FCIOM SG_ 826 LEDAnimation_cmd 180;
BA_REL_ "GenSigFirstTimeoutTime" BU_SG_REL_ RCIOM SG_ 826 ActualDrvlnRetdrPercentTorque 3000;
BA_REL_ "GenSigTimeoutTime" BU_SG_REL_ RCIOM SG_ 826 ActualDrvlnRetdrPercentTorque 180;
BA_REL_ "GenSigFirstTimeoutTime" BU_SG_REL_ FCIOM SG_ 826 PloughLampModeStatus 3000;
BA_REL_ "GenSigTimeoutTime" BU_SG_REL_ FCIOM SG_ 826 PloughLampModeStatus 180;
BA_REL_ "GenSigFirstTimeoutTime" BU_SG_REL_ CCIOM SG_ 826 RangeInhibit 3000;
BA_REL_ "GenSigTimeoutTime" BU_SG_REL_ CCIOM SG_ 826 RangeInhibit 180;
BA_REL_ "GenSigFirstTimeoutTime" BU_SG_REL_ RCIOM SG_ 826 TrailerBrakeNoEbs_stat 3000;
BA_REL_ "GenSigTimeoutTime" BU_SG_REL_ RCIOM SG_ 826 TrailerBrakeNoEbs_stat 180;
BA_REL_ "GenSigFirstTimeoutTime" BU_SG_REL_ RCIOM SG_ 826 LiftAxle1DirectControl 3000;
BA_REL_ "GenSigTimeoutTime" BU_SG_REL_ RCIOM SG_ 826 LiftAxle1DirectControl 500;
BA_REL_ "GenSigFirstTimeoutTime" BU_SG_REL_ CCIOM SG_ 826 DoorsAjar_stat 3000;
BA_REL_ "GenSigTimeoutTime" BU_SG_REL_ CCIOM SG_ 826 DoorsAjar_stat 500;
BA_REL_ "GenSigFirstTimeoutTime" BU_SG_REL_ RCIOM SG_ 826 BlackOutandConvoyMode_rqst 3000;
BA_REL_ "GenSigTimeoutTime" BU_SG_REL_ RCIOM SG_ 826 BlackOutandConvoyMode_rqst 180;
BA_REL_ "GenSigFirstTimeoutTime" BU_SG_REL_ CCIOM SG_ 826 BlackOutandConvoyMode_rqst 3000;
BA_REL_ "GenSigTimeoutTime" BU_SG_REL_ CCIOM SG_ 826 BlackOutandConvoyMode_rqst 180;
BA_REL_ "GenSigFirstTimeoutTime" BU_SG_REL_ CCIOM SG_ 826 DoorsAjar_stat_UB 3000;
BA_REL_ "GenSigTimeoutTime" BU_SG_REL_ CCIOM SG_ 826 DoorsAjar_stat_UB 180;
BA_REL_ "GenSigFirstTimeoutTime" BU_SG_REL_ RCIOM SG_ 826 ECSStandByRequest 3000;
BA_REL_ "GenSigTimeoutTime" BU_SG_REL_ RCIOM SG_ 826 ECSStandByRequest 180;
BA_REL_ "GenSigFirstTimeoutTime" BU_SG_REL_ FCIOM SG_ 826 ChassisInstepLight_cmd 3000;
BA_REL_ "GenSigTimeoutTime" BU_SG_REL_ FCIOM SG_ 826 ChassisInstepLight_cmd 180;
BA_REL_ "GenSigFirstTimeoutTime" BU_SG_REL_ CCIOM SG_ 826 BBSlidable5thWheelCmd 3000;
BA_REL_ "GenSigTimeoutTime" BU_SG_REL_ CCIOM SG_ 826 BBSlidable5thWheelCmd 180;
BA_REL_ "GenSigFirstTimeoutTime" BU_SG_REL_ CCIOM SG_ 826 ParkingBrake_stat 3000;
BA_REL_ "GenSigTimeoutTime" BU_SG_REL_ CCIOM SG_ 826 ParkingBrake_stat 180;
BA_REL_ "GenSigFirstTimeoutTime" BU_SG_REL_ CCIOM SG_ 826 MaintBatteryReset 3000;
BA_REL_ "GenSigTimeoutTime" BU_SG_REL_ CCIOM SG_ 826 MaintBatteryReset 180;
BA_REL_ "GenSigFirstTimeoutTime" BU_SG_REL_ RCIOM SG_ 1369 TotalVehicleDistanceHighRes 12000;
BA_REL_ "GenSigTimeoutTime" BU_SG_REL_ RCIOM SG_ 1369 TotalVehicleDistanceHighRes 3000;
BA_REL_ "GenSigFirstTimeoutTime" BU_SG_REL_ CCIOM SG_ 1369 TotalVehicleDistanceHighRes 12000;
BA_REL_ "GenSigTimeoutTime" BU_SG_REL_ CCIOM SG_ 1369 TotalVehicleDistanceHighRes 3000;
BA_REL_ "GenSigFirstTimeoutTime" BU_SG_REL_ FCIOM SG_ 1369 TotalVehicleDistanceHighRes 12000;
BA_REL_ "GenSigTimeoutTime" BU_SG_REL_ FCIOM SG_ 1369 TotalVehicleDistanceHighRes 3000;
BA_REL_ "GenSigFirstTimeoutTime" BU_SG_REL_ BPMU SG_ 1369 TotalVehicleDistanceHighRes 12000;
BA_REL_ "GenSigTimeoutTime" BU_SG_REL_ BPMU SG_ 1369 TotalVehicleDistanceHighRes 3000;
BA_REL_ "GenSigFirstTimeoutTime" BU_SG_REL_ RCIOM SG_ 946 TransferCaseOrSplitboxPTOMode 3000;
BA_REL_ "GenSigTimeoutTime" BU_SG_REL_ RCIOM SG_ 946 TransferCaseOrSplitboxPTOMode 300;
BA_REL_ "GenSigFirstTimeoutTime" BU_SG_REL_ RCIOM SG_ 946 Pto3Status 3000;
BA_REL_ "GenSigTimeoutTime" BU_SG_REL_ RCIOM SG_ 946 Pto3Status 300;
BA_REL_ "GenSigFirstTimeoutTime" BU_SG_REL_ RCIOM SG_ 946 RearAxleDiffLockActvnFuncReq 3000;
BA_REL_ "GenSigTimeoutTime" BU_SG_REL_ RCIOM SG_ 946 RearAxleDiffLockActvnFuncReq 500;
BA_REL_ "GenSigFirstTimeoutTime" BU_SG_REL_ RCIOM SG_ 946 Pto1Status 3000;
BA_REL_ "GenSigTimeoutTime" BU_SG_REL_ RCIOM SG_ 946 Pto1Status 300;
BA_REL_ "GenSigFirstTimeoutTime" BU_SG_REL_ CCIOM SG_ 946 ReducedLoadMode_stat 3000;
BA_REL_ "GenSigTimeoutTime" BU_SG_REL_ CCIOM SG_ 946 ReducedLoadMode_stat 300;
BA_REL_ "GenSigFirstTimeoutTime" BU_SG_REL_ RCIOM SG_ 946 RearAxleDiffLockActvnDrvrReq 3000;
BA_REL_ "GenSigTimeoutTime" BU_SG_REL_ RCIOM SG_ 946 RearAxleDiffLockActvnDrvrReq 500;
BA_REL_ "GenSigFirstTimeoutTime" BU_SG_REL_ CCIOM SG_ 946 Pto2DrivingRequest 3000;
BA_REL_ "GenSigTimeoutTime" BU_SG_REL_ CCIOM SG_ 946 Pto2DrivingRequest 300;
BA_REL_ "GenSigFirstTimeoutTime" BU_SG_REL_ RCIOM SG_ 946 RrInterAxlDiffLockActvnFuncReq 3000;
BA_REL_ "GenSigTimeoutTime" BU_SG_REL_ RCIOM SG_ 946 RrInterAxlDiffLockActvnFuncReq 300;
BA_REL_ "GenSigFirstTimeoutTime" BU_SG_REL_ CCIOM SG_ 946 CartridgeChangedDrvrReset_rqst 3000;
BA_REL_ "GenSigTimeoutTime" BU_SG_REL_ CCIOM SG_ 946 CartridgeChangedDrvrReset_rqst 300;
BA_REL_ "GenSigFirstTimeoutTime" BU_SG_REL_ RCIOM SG_ 946 RrInterAxlDiffLockActvnDrvrReq 3000;
BA_REL_ "GenSigTimeoutTime" BU_SG_REL_ RCIOM SG_ 946 RrInterAxlDiffLockActvnDrvrReq 500;
BA_REL_ "GenSigFirstTimeoutTime" BU_SG_REL_ RCIOM SG_ 946 Pto2Status 3000;
BA_REL_ "GenSigTimeoutTime" BU_SG_REL_ RCIOM SG_ 946 Pto2Status 300;
BA_REL_ "GenSigFirstTimeoutTime" BU_SG_REL_ RCIOM SG_ 946 Pto4Status 3000;
BA_REL_ "GenSigTimeoutTime" BU_SG_REL_ RCIOM SG_ 946 Pto4Status 300;
BA_REL_ "GenSigFirstTimeoutTime" BU_SG_REL_ CCIOM SG_ 946 Pto1DrivingRequest 3000;
BA_REL_ "GenSigTimeoutTime" BU_SG_REL_ CCIOM SG_ 946 Pto1DrivingRequest 300;
BA_REL_ "GenSigFirstTimeoutTime" BU_SG_REL_ RCIOM SG_ 945 ActualEngineRetarderPercentTrq 3000;
BA_REL_ "GenSigTimeoutTime" BU_SG_REL_ RCIOM SG_ 945 ActualEngineRetarderPercentTrq 300;
BA_REL_ "GenSigFirstTimeoutTime" BU_SG_REL_ CCIOM SG_ 945 ActualEnginePercentTorque 3000;
BA_REL_ "GenSigTimeoutTime" BU_SG_REL_ CCIOM SG_ 945 ActualEnginePercentTorque 500;
BA_REL_ "GenSigFirstTimeoutTime" BU_SG_REL_ RCIOM SG_ 945 ActualEnginePercentTorque 3000;
BA_REL_ "GenSigTimeoutTime" BU_SG_REL_ RCIOM SG_ 945 ActualEnginePercentTorque 500;
BA_REL_ "GenSigFirstTimeoutTime" BU_SG_REL_ RCIOM SG_ 945 NominalFrictionPercentTorque 3000;
BA_REL_ "GenSigTimeoutTime" BU_SG_REL_ RCIOM SG_ 945 NominalFrictionPercentTorque 500;
BA_REL_ "GenSigFirstTimeoutTime" BU_SG_REL_ CCIOM SG_ 945 EcoRollActiveStatus 3000;
BA_REL_ "GenSigTimeoutTime" BU_SG_REL_ CCIOM SG_ 945 EcoRollActiveStatus 300;
BA_REL_ "GenSigFirstTimeoutTime" BU_SG_REL_ RCIOM SG_ 945 EngineReferenceTorque 3000;
BA_REL_ "GenSigTimeoutTime" BU_SG_REL_ RCIOM SG_ 945 EngineReferenceTorque 500;
BA_REL_ "GenSigFirstTimeoutTime" BU_SG_REL_ RCIOM SG_ 928 RrRrItrWhlDiffLckActvnDrvrReq 3000;
BA_REL_ "GenSigTimeoutTime" BU_SG_REL_ RCIOM SG_ 928 RrRrItrWhlDiffLckActvnDrvrReq 500;
BA_REL_ "GenSigFirstTimeoutTime" BU_SG_REL_ CCIOM SG_ 928 EngineSpeed 3000;
BA_REL_ "GenSigTimeoutTime" BU_SG_REL_ CCIOM SG_ 928 EngineSpeed 500;
BA_REL_ "GenSigFirstTimeoutTime" BU_SG_REL_ RCIOM SG_ 928 LiftAxle1Request 3000;
BA_REL_ "GenSigTimeoutTime" BU_SG_REL_ RCIOM SG_ 928 LiftAxle1Request 270;
BA_REL_ "GenSigFirstTimeoutTime" BU_SG_REL_ RCIOM SG_ 928 Rear1ClutchRequest 3000;
BA_REL_ "GenSigTimeoutTime" BU_SG_REL_ RCIOM SG_ 928 Rear1ClutchRequest 270;
BA_REL_ "GenSigFirstTimeoutTime" BU_SG_REL_ CCIOM SG_ 928 FrontWheelDifflockRequest 3000;
BA_REL_ "GenSigTimeoutTime" BU_SG_REL_ CCIOM SG_ 928 FrontWheelDifflockRequest 500;
BA_REL_ "GenSigFirstTimeoutTime" BU_SG_REL_ RCIOM SG_ 827 FrAxleLeftWheelRelativeSpeed 3000;
BA_REL_ "GenSigTimeoutTime" BU_SG_REL_ RCIOM SG_ 827 FrAxleLeftWheelRelativeSpeed 240;
BA_REL_ "GenSigFirstTimeoutTime" BU_SG_REL_ RCIOM SG_ 827 FrAxleRightWheelRelativeSpeed 3000;
BA_REL_ "GenSigTimeoutTime" BU_SG_REL_ RCIOM SG_ 827 FrAxleRightWheelRelativeSpeed 240;
BA_REL_ "GenSigFirstTimeoutTime" BU_SG_REL_ RCIOM SG_ 827 FrontAxleSpeed 3000;
BA_REL_ "GenSigTimeoutTime" BU_SG_REL_ RCIOM SG_ 827 FrontAxleSpeed 240;
BA_REL_ "GenSigFirstTimeoutTime" BU_SG_REL_ CCIOM SG_ 827 FrontAxleSpeed 3000;
BA_REL_ "GenSigTimeoutTime" BU_SG_REL_ CCIOM SG_ 827 FrontAxleSpeed 240;
BA_REL_ "GenSigFirstTimeoutTime" BU_SG_REL_ RCIOM SG_ 537 LiftAxle2LiftPositionRequest 3000;
BA_REL_ "GenSigTimeoutTime" BU_SG_REL_ RCIOM SG_ 537 LiftAxle2LiftPositionRequest 500;
BA_REL_ "GenSigFirstTimeoutTime" BU_SG_REL_ RCIOM SG_ 537 LoadDistributionChangeRequest 3000;
BA_REL_ "GenSigTimeoutTime" BU_SG_REL_ RCIOM SG_ 537 LoadDistributionChangeRequest 500;
BA_REL_ "GenSigFirstTimeoutTime" BU_SG_REL_ RCIOM SG_ 537 AltLoadDistribution_rqst 3000;
BA_REL_ "GenSigTimeoutTime" BU_SG_REL_ RCIOM SG_ 537 AltLoadDistribution_rqst 500;
BA_REL_ "GenSigFirstTimeoutTime" BU_SG_REL_ RCIOM SG_ 537 LiftAxle1LiftPositionRequest 3000;
BA_REL_ "GenSigTimeoutTime" BU_SG_REL_ RCIOM SG_ 537 LiftAxle1LiftPositionRequest 500;
BA_REL_ "GenSigFirstTimeoutTime" BU_SG_REL_ RCIOM SG_ 537 RampLevelRequest 3000;
BA_REL_ "GenSigTimeoutTime" BU_SG_REL_ RCIOM SG_ 537 RampLevelRequest 150;
BA_REL_ "GenSigFirstTimeoutTime" BU_SG_REL_ RCIOM SG_ 537 RampLevelStorageRequest 3000;
BA_REL_ "GenSigTimeoutTime" BU_SG_REL_ RCIOM SG_ 537 RampLevelStorageRequest 150;
BA_REL_ "GenSigFirstTimeoutTime" BU_SG_REL_ RCIOM SG_ 537 RideHeightFunctionRequest 3000;
BA_REL_ "GenSigTimeoutTime" BU_SG_REL_ RCIOM SG_ 537 RideHeightFunctionRequest 500;
BA_REL_ "GenSigFirstTimeoutTime" BU_SG_REL_ RCIOM SG_ 537 LiftAxle1AutoLiftRequest 3000;
BA_REL_ "GenSigTimeoutTime" BU_SG_REL_ RCIOM SG_ 537 LiftAxle1AutoLiftRequest 500;
BA_REL_ "GenSigFirstTimeoutTime" BU_SG_REL_ RCIOM SG_ 537 FerryFunctionRequest 3000;
BA_REL_ "GenSigTimeoutTime" BU_SG_REL_ RCIOM SG_ 537 FerryFunctionRequest 500;
BA_REL_ "GenSigFirstTimeoutTime" BU_SG_REL_ RCIOM SG_ 537 BBSystemKneelRequest 3000;
BA_REL_ "GenSigTimeoutTime" BU_SG_REL_ RCIOM SG_ 537 BBSystemKneelRequest 150;
BA_REL_ "GenSigFirstTimeoutTime" BU_SG_REL_ RCIOM SG_ 537 StopLevelChangeRequest 3000;
BA_REL_ "GenSigTimeoutTime" BU_SG_REL_ RCIOM SG_ 537 StopLevelChangeRequest 150;
BA_REL_ "GenSigFirstTimeoutTime" BU_SG_REL_ RCIOM SG_ 537 FirstAxleLowerPrioRequested 3000;
BA_REL_ "GenSigTimeoutTime" BU_SG_REL_ RCIOM SG_ 537 FirstAxleLowerPrioRequested 500;
BA_REL_ "GenSigFirstTimeoutTime" BU_SG_REL_ RCIOM SG_ 537 LiftAxle2AutoLiftRequest 3000;
BA_REL_ "GenSigTimeoutTime" BU_SG_REL_ RCIOM SG_ 537 LiftAxle2AutoLiftRequest 500;
BA_REL_ "GenSigFirstTimeoutTime" BU_SG_REL_ RCIOM SG_ 537 FerryFunctionSwitchChangeReq 3000;
BA_REL_ "GenSigTimeoutTime" BU_SG_REL_ RCIOM SG_ 537 FerryFunctionSwitchChangeReq 120;
BA_REL_ "GenSigFirstTimeoutTime" BU_SG_REL_ RCIOM SG_ 537 LevelStrokeRequest 3000;
BA_REL_ "GenSigTimeoutTime" BU_SG_REL_ RCIOM SG_ 537 LevelStrokeRequest 150;
BA_REL_ "GenSigFirstTimeoutTime" BU_SG_REL_ RCIOM SG_ 537 BBSystemProhibitControlRequest 3000;
BA_REL_ "GenSigTimeoutTime" BU_SG_REL_ RCIOM SG_ 537 BBSystemProhibitControlRequest 150;
BA_REL_ "GenSigFirstTimeoutTime" BU_SG_REL_ RCIOM SG_ 537 BBSystemAlternatLoadDistribReq 3000;
BA_REL_ "GenSigTimeoutTime" BU_SG_REL_ RCIOM SG_ 537 BBSystemAlternatLoadDistribReq 500;
BA_REL_ "GenSigFirstTimeoutTime" BU_SG_REL_ RCIOM SG_ 537 RideHeightStorageRequest 3000;
BA_REL_ "GenSigTimeoutTime" BU_SG_REL_ RCIOM SG_ 537 RideHeightStorageRequest 150;
BA_REL_ "GenSigFirstTimeoutTime" BU_SG_REL_ RCIOM SG_ 537 BBSystemSpeedDepDriveLevelReq 3000;
BA_REL_ "GenSigTimeoutTime" BU_SG_REL_ RCIOM SG_ 537 BBSystemSpeedDepDriveLevelReq 150;
BA_REL_ "GenSigFirstTimeoutTime" BU_SG_REL_ RCIOM SG_ 531 BackToDriveReq 3000;
BA_REL_ "GenSigTimeoutTime" BU_SG_REL_ RCIOM SG_ 531 BackToDriveReq 120;
BA_REL_ "GenSigFirstTimeoutTime" BU_SG_REL_ CCIOM SG_ 531 TrailerBrakePres_rqst 3000;
BA_REL_ "GenSigTimeoutTime" BU_SG_REL_ CCIOM SG_ 531 TrailerBrakePres_rqst 500;
BA_REL_ "GenSigFirstTimeoutTime" BU_SG_REL_ FCIOM SG_ 531 FogLight_Front_cmd 3000;
BA_REL_ "GenSigTimeoutTime" BU_SG_REL_ FCIOM SG_ 531 FogLight_Front_cmd 120;
BA_REL_ "GenSigFirstTimeoutTime" BU_SG_REL_ CCIOM SG_ 531 SplitBoxDifflockActvnDrvrRqst 3000;
BA_REL_ "GenSigTimeoutTime" BU_SG_REL_ CCIOM SG_ 531 SplitBoxDifflockActvnDrvrRqst 500;
BA_REL_ "GenSigFirstTimeoutTime" BU_SG_REL_ FCIOM SG_ 531 WS_Washing_cmd 3000;
BA_REL_ "GenSigTimeoutTime" BU_SG_REL_ FCIOM SG_ 531 WS_Washing_cmd 120;
BA_REL_ "GenSigFirstTimeoutTime" BU_SG_REL_ RCIOM SG_ 531 ReverseWarning_rqst 3000;
BA_REL_ "GenSigTimeoutTime" BU_SG_REL_ RCIOM SG_ 531 ReverseWarning_rqst 120;
BA_REL_ "GenSigFirstTimeoutTime" BU_SG_REL_ RCIOM SG_ 531 FogLight_Rear_cmd 3000;
BA_REL_ "GenSigTimeoutTime" BU_SG_REL_ RCIOM SG_ 531 FogLight_Rear_cmd 120;
BA_REL_ "GenSigFirstTimeoutTime" BU_SG_REL_ CCIOM SG_ 531 FogLight_Rear_cmd 3000;
BA_REL_ "GenSigTimeoutTime" BU_SG_REL_ CCIOM SG_ 531 FogLight_Rear_cmd 120;
BA_REL_ "GenSigFirstTimeoutTime" BU_SG_REL_ CCIOM SG_ 531 SplitBoxDifflockActvnDrvrRqst_UB 3000;
BA_REL_ "GenSigTimeoutTime" BU_SG_REL_ CCIOM SG_ 531 SplitBoxDifflockActvnDrvrRqst_UB 120;
BA_REL_ "GenSigFirstTimeoutTime" BU_SG_REL_ CCIOM SG_ 531 FrAxleDiffLockActvnDriverRqst 3000;
BA_REL_ "GenSigTimeoutTime" BU_SG_REL_ CCIOM SG_ 531 FrAxleDiffLockActvnDriverRqst 500;
BA_REL_ "GenSigFirstTimeoutTime" BU_SG_REL_ RCIOM SG_ 392 AcceleratorPedalPosition1 3000;
BA_REL_ "GenSigTimeoutTime" BU_SG_REL_ RCIOM SG_ 392 AcceleratorPedalPosition1 60;
BA_REL_ "GenSigFirstTimeoutTime" BU_SG_REL_ CCIOM SG_ 392 AcceleratorPedalPosition1 3000;
BA_REL_ "GenSigTimeoutTime" BU_SG_REL_ CCIOM SG_ 392 AcceleratorPedalPosition1 60;
BA_REL_ "GenSigFirstTimeoutTime" BU_SG_REL_ FCIOM SG_ 392 MainBeam_cmd 3000;
BA_REL_ "GenSigTimeoutTime" BU_SG_REL_ FCIOM SG_ 392 MainBeam_cmd 60;
BA_REL_ "GenSigFirstTimeoutTime" BU_SG_REL_ RCIOM SG_ 392 MainBeam_cmd 3000;
BA_REL_ "GenSigTimeoutTime" BU_SG_REL_ RCIOM SG_ 392 MainBeam_cmd 60;
BA_REL_ "GenSigFirstTimeoutTime" BU_SG_REL_ FCIOM SG_ 392 DippedBeam_cmd 3000;
BA_REL_ "GenSigTimeoutTime" BU_SG_REL_ FCIOM SG_ 392 DippedBeam_cmd 60;
BA_REL_ "GenSigFirstTimeoutTime" BU_SG_REL_ RCIOM SG_ 392 DippedBeam_cmd 3000;
BA_REL_ "GenSigTimeoutTime" BU_SG_REL_ RCIOM SG_ 392 DippedBeam_cmd 60;
BA_REL_ "GenSigFirstTimeoutTime" BU_SG_REL_ RCIOM SG_ 392 BrakePedalPosition 3000;
BA_REL_ "GenSigTimeoutTime" BU_SG_REL_ RCIOM SG_ 392 BrakePedalPosition 60;
BA_REL_ "GenSigFirstTimeoutTime" BU_SG_REL_ CCIOM SG_ 392 BrakePedalPosition 3000;
BA_REL_ "GenSigTimeoutTime" BU_SG_REL_ CCIOM SG_ 392 BrakePedalPosition 60;
BA_REL_ "GenSigFirstTimeoutTime" BU_SG_REL_ FCIOM SG_ 392 ExtraMainBeam_cmd 3000;
BA_REL_ "GenSigTimeoutTime" BU_SG_REL_ FCIOM SG_ 392 ExtraMainBeam_cmd 60;
BA_REL_ "GenSigFirstTimeoutTime" BU_SG_REL_ FCIOM SG_ 392 Hazard_rqst 3000;
BA_REL_ "GenSigTimeoutTime" BU_SG_REL_ FCIOM SG_ 392 Hazard_rqst 60;
BA_REL_ "GenSigFirstTimeoutTime" BU_SG_REL_ FCIOM SG_ 392 DirectionIndicatorLights_rqst 3000;
BA_REL_ "GenSigTimeoutTime" BU_SG_REL_ FCIOM SG_ 392 DirectionIndicatorLights_rqst 60;
BA_REL_ "GenSigFirstTimeoutTime" BU_SG_REL_ FCIOM SG_ 392 DRL_cmd 3000;
BA_REL_ "GenSigTimeoutTime" BU_SG_REL_ FCIOM SG_ 392 DRL_cmd 60;
BA_REL_ "GenSigFirstTimeoutTime" BU_SG_REL_ RCIOM SG_ 392 DRL_cmd 3000;
BA_REL_ "GenSigTimeoutTime" BU_SG_REL_ RCIOM SG_ 392 DRL_cmd 60;
BA_REL_ "GenSigFirstTimeoutTime" BU_SG_REL_ FCIOM SG_ 392 DirectionIndicatorLights_cmd 3000;
BA_REL_ "GenSigTimeoutTime" BU_SG_REL_ FCIOM SG_ 392 DirectionIndicatorLights_cmd 60;
BA_REL_ "GenSigFirstTimeoutTime" BU_SG_REL_ RCIOM SG_ 392 DirectionIndicatorLights_cmd 3000;
BA_REL_ "GenSigTimeoutTime" BU_SG_REL_ RCIOM SG_ 392 DirectionIndicatorLights_cmd 60;
BA_REL_ "GenSigFirstTimeoutTime" BU_SG_REL_ CCIOM SG_ 392 DirectionIndicatorLights_cmd 3000;
BA_REL_ "GenSigTimeoutTime" BU_SG_REL_ CCIOM SG_ 392 DirectionIndicatorLights_cmd 60;
BA_REL_ "GenSigFirstTimeoutTime" BU_SG_REL_ FCIOM SG_ 392 PositionLight_cmd 3000;
BA_REL_ "GenSigTimeoutTime" BU_SG_REL_ FCIOM SG_ 392 PositionLight_cmd 60;
BA_REL_ "GenSigFirstTimeoutTime" BU_SG_REL_ RCIOM SG_ 392 PositionLight_cmd 3000;
BA_REL_ "GenSigTimeoutTime" BU_SG_REL_ RCIOM SG_ 392 PositionLight_cmd 60;
BA_REL_ "GenSigFirstTimeoutTime" BU_SG_REL_ FCIOM SG_ 392 StaticCornerLight_cmd 3000;
BA_REL_ "GenSigTimeoutTime" BU_SG_REL_ FCIOM SG_ 392 StaticCornerLight_cmd 60;
BA_REL_ "GenSigFirstTimeoutTime" BU_SG_REL_ CCIOM SG_ 392 WorkingLightChassisOutp_cmd 3000;
BA_REL_ "GenSigTimeoutTime" BU_SG_REL_ CCIOM SG_ 392 WorkingLightChassisOutp_cmd 60;
BA_REL_ "GenSigFirstTimeoutTime" BU_SG_REL_ FCIOM SG_ 895 ApproachLight_FrontRqst 3000;
BA_REL_ "GenSigTimeoutTime" BU_SG_REL_ FCIOM SG_ 895 ApproachLight_FrontRqst 300;
BA_REL_ "GenSigFirstTimeoutTime" BU_SG_REL_ RCIOM SG_ 895 EASTagLiftAxleLoweringInhibit 12000;
BA_REL_ "GenSigTimeoutTime" BU_SG_REL_ RCIOM SG_ 895 EASTagLiftAxleLoweringInhibit 300;
BA_REL_ "GenSigFirstTimeoutTime" BU_SG_REL_ RCIOM SG_ 895 WheelBasedVehicleSpeed 12000;
BA_REL_ "GenSigTimeoutTime" BU_SG_REL_ RCIOM SG_ 895 WheelBasedVehicleSpeed 300;
BA_REL_ "GenSigFirstTimeoutTime" BU_SG_REL_ CCIOM SG_ 895 WheelBasedVehicleSpeed 3000;
BA_REL_ "GenSigTimeoutTime" BU_SG_REL_ CCIOM SG_ 895 WheelBasedVehicleSpeed 300;
BA_REL_ "GenSigFirstTimeoutTime" BU_SG_REL_ RCIOM SG_ 895 FrRrItrWhlDiffLckActvnDrvrReq 12000;
BA_REL_ "GenSigTimeoutTime" BU_SG_REL_ RCIOM SG_ 895 FrRrItrWhlDiffLckActvnDrvrReq 300;
BA_REL_ "GenSigFirstTimeoutTime" BU_SG_REL_ RCIOM SG_ 895 ApproachLight_RearandSideRqst 12000;
BA_REL_ "GenSigTimeoutTime" BU_SG_REL_ RCIOM SG_ 895 ApproachLight_RearandSideRqst 300;
BA_REL_ "GenSigFirstTimeoutTime" BU_SG_REL_ FCIOM SG_ 895 ApproachLight_HLAnimationcmd 3000;
BA_REL_ "GenSigTimeoutTime" BU_SG_REL_ FCIOM SG_ 895 ApproachLight_HLAnimationcmd 300;
BA_REL_ "GenSigFirstTimeoutTime" BU_SG_REL_ CCIOM SG_ 895 TransmissionSelectedGear 3000;
BA_REL_ "GenSigTimeoutTime" BU_SG_REL_ CCIOM SG_ 895 TransmissionSelectedGear 300;
BA_REL_ "GenSigFirstTimeoutTime" BU_SG_REL_ CCIOM SG_ 895 TransmissionCurrentGear 3000;
BA_REL_ "GenSigTimeoutTime" BU_SG_REL_ CCIOM SG_ 895 TransmissionCurrentGear 300;
BA_REL_ "GenSigFirstTimeoutTime" BU_SG_REL_ CCIOM SG_ 895 TransmEngineCrankEnable 3000;
BA_REL_ "GenSigTimeoutTime" BU_SG_REL_ CCIOM SG_ 895 TransmEngineCrankEnable 300;
BA_REL_ "GenSigFirstTimeoutTime" BU_SG_REL_ CCIOM SG_ 895 TransmEngineCrankEnable2 3000;
BA_REL_ "GenSigTimeoutTime" BU_SG_REL_ CCIOM SG_ 895 TransmEngineCrankEnable2 300;
BA_REL_ "GenSigFirstTimeoutTime" BU_SG_REL_ CCIOM SG_ 588 VehicleMode 3000;
BA_REL_ "GenSigTimeoutTime" BU_SG_REL_ CCIOM SG_ 588 VehicleMode 120;
BA_REL_ "GenSigFirstTimeoutTime" BU_SG_REL_ BPMU SG_ 588 VehicleMode 3000;
BA_REL_ "GenSigTimeoutTime" BU_SG_REL_ BPMU SG_ 588 VehicleMode 300;
BA_REL_ "GenSigFirstTimeoutTime" BU_SG_REL_ TBIOM SG_ 588 VehicleMode 3000;
BA_REL_ "GenSigTimeoutTime" BU_SG_REL_ TBIOM SG_ 588 VehicleMode 120;
BA_REL_ "GenSigFirstTimeoutTime" BU_SG_REL_ FCIOM SG_ 588 VehicleMode 3000;
BA_REL_ "GenSigTimeoutTime" BU_SG_REL_ FCIOM SG_ 588 VehicleMode 300;
BA_REL_ "GenSigFirstTimeoutTime" BU_SG_REL_ RCIOM SG_ 588 VehicleMode 3000;
BA_REL_ "GenSigTimeoutTime" BU_SG_REL_ RCIOM SG_ 588 VehicleMode 300;
BA_REL_ "GenSigFirstTimeoutTime" BU_SG_REL_ CCIOM SG_ 588 TransmissionDrivelineEngaged 3000;
BA_REL_ "GenSigTimeoutTime" BU_SG_REL_ CCIOM SG_ 588 TransmissionDrivelineEngaged 120;
BA_REL_ "GenSigFirstTimeoutTime" BU_SG_REL_ CCIOM SG_ 588 SecuredNeutralPosition 3000;
BA_REL_ "GenSigTimeoutTime" BU_SG_REL_ CCIOM SG_ 588 SecuredNeutralPosition 120;
BA_REL_ "GenSigFirstTimeoutTime" BU_SG_REL_ CCIOM SG_ 588 GearLeverPosition 3000;
BA_REL_ "GenSigTimeoutTime" BU_SG_REL_ CCIOM SG_ 588 GearLeverPosition 120;
BA_REL_ "GenSigFirstTimeoutTime" BU_SG_REL_ CCIOM SG_ 588 EngineActiveStatus 3000;
BA_REL_ "GenSigTimeoutTime" BU_SG_REL_ CCIOM SG_ 588 EngineActiveStatus 120;
BA_REL_ "GenSigFirstTimeoutTime" BU_SG_REL_ RCIOM SG_ 957 TrlrDirIndRightOutputStat_12V 3000;
BA_REL_ "GenSigTimeoutTime" BU_SG_REL_ RCIOM SG_ 957 TrlrDirIndRightOutputStat_12V 600;
BA_REL_ "GenSigFirstTimeoutTime" BU_SG_REL_ RCIOM SG_ 957 TrailerBrakeLightOutputStat12V 3000;
BA_REL_ "GenSigTimeoutTime" BU_SG_REL_ RCIOM SG_ 957 TrailerBrakeLightOutputStat12V 600;
BA_REL_ "GenSigFirstTimeoutTime" BU_SG_REL_ RCIOM SG_ 957 TrailerDirIndLightRequested12V 3000;
BA_REL_ "GenSigTimeoutTime" BU_SG_REL_ RCIOM SG_ 957 TrailerDirIndLightRequested12V 600;
BA_REL_ "GenSigFirstTimeoutTime" BU_SG_REL_ RCIOM SG_ 957 TD_BrakeLightsPulseRsp_12V 3000;
BA_REL_ "GenSigTimeoutTime" BU_SG_REL_ RCIOM SG_ 957 TD_BrakeLightsPulseRsp_12V 600;
BA_REL_ "GenSigFirstTimeoutTime" BU_SG_REL_ RCIOM SG_ 957 TD_DirInLgtPlsRsp_12V_Right 3000;
BA_REL_ "GenSigTimeoutTime" BU_SG_REL_ RCIOM SG_ 957 TD_DirInLgtPlsRsp_12V_Right 600;
BA_REL_ "GenSigFirstTimeoutTime" BU_SG_REL_ RCIOM SG_ 957 TrailerBrakeLightsRequested12V 3000;
BA_REL_ "GenSigTimeoutTime" BU_SG_REL_ RCIOM SG_ 957 TrailerBrakeLightsRequested12V 600;
BA_REL_ "GenSigFirstTimeoutTime" BU_SG_REL_ RCIOM SG_ 957 TrailerPos2OutputStat_12V 3000;
BA_REL_ "GenSigTimeoutTime" BU_SG_REL_ RCIOM SG_ 957 TrailerPos2OutputStat_12V 600;
BA_REL_ "GenSigFirstTimeoutTime" BU_SG_REL_ RCIOM SG_ 957 TD_PosLghtPlsRsp12V_Pos2 3000;
BA_REL_ "GenSigTimeoutTime" BU_SG_REL_ RCIOM SG_ 957 TD_PosLghtPlsRsp12V_Pos2 600;
BA_REL_ "GenSigFirstTimeoutTime" BU_SG_REL_ RCIOM SG_ 957 TrailerConnected_12VABSCurrent 3000;
BA_REL_ "GenSigTimeoutTime" BU_SG_REL_ RCIOM SG_ 957 TrailerConnected_12VABSCurrent 600;
BA_REL_ "GenSigFirstTimeoutTime" BU_SG_REL_ RCIOM SG_ 957 TrailerPosLightRequested12V 3000;
BA_REL_ "GenSigTimeoutTime" BU_SG_REL_ RCIOM SG_ 957 TrailerPosLightRequested12V 600;
BA_REL_ "GenSigFirstTimeoutTime" BU_SG_REL_ RCIOM SG_ 957 TD_PosLghtPlsRsp12V_Pos1 3000;
BA_REL_ "GenSigTimeoutTime" BU_SG_REL_ RCIOM SG_ 957 TD_PosLghtPlsRsp12V_Pos1 600;
BA_REL_ "GenSigFirstTimeoutTime" BU_SG_REL_ RCIOM SG_ 957 TrlrDirIndLeftOutputStat_12V 3000;
BA_REL_ "GenSigTimeoutTime" BU_SG_REL_ RCIOM SG_ 957 TrlrDirIndLeftOutputStat_12V 600;
BA_REL_ "GenSigFirstTimeoutTime" BU_SG_REL_ RCIOM SG_ 957 TrailerPos1OutputStat_12V 3000;
BA_REL_ "GenSigTimeoutTime" BU_SG_REL_ RCIOM SG_ 957 TrailerPos1OutputStat_12V 600;
BA_REL_ "GenSigFirstTimeoutTime" BU_SG_REL_ RCIOM SG_ 957 TD_DirInLgtPlsRsp_12V_Left 3000;
BA_REL_ "GenSigTimeoutTime" BU_SG_REL_ RCIOM SG_ 957 TD_DirInLgtPlsRsp_12V_Left 600;
BA_REL_ "GenSigFirstTimeoutTime" BU_SG_REL_ VCM SG_ 958 TD_LghtPlsReqBrk12V_Status 3000;
BA_REL_ "GenSigTimeoutTime" BU_SG_REL_ VCM SG_ 958 TD_LghtPlsReqBrk12V_Status 600;
BA_REL_ "GenSigFirstTimeoutTime" BU_SG_REL_ VCM SG_ 958 TD_LghtPlsReqDir12V_Right 3000;
BA_REL_ "GenSigTimeoutTime" BU_SG_REL_ VCM SG_ 958 TD_LghtPlsReqDir12V_Right 600;
BA_REL_ "GenSigFirstTimeoutTime" BU_SG_REL_ VCM SG_ 958 TD_LghtPlsReqDir12V_Status 3000;
BA_REL_ "GenSigTimeoutTime" BU_SG_REL_ VCM SG_ 958 TD_LghtPlsReqDir12V_Status 600;
BA_REL_ "GenSigFirstTimeoutTime" BU_SG_REL_ VCM SG_ 958 TD_LightsResetReq_12V 3000;
BA_REL_ "GenSigTimeoutTime" BU_SG_REL_ VCM SG_ 958 TD_LightsResetReq_12V 600;
BA_REL_ "GenSigFirstTimeoutTime" BU_SG_REL_ VCM SG_ 958 TD_LghtPlsReqPos12V_Status 3000;
BA_REL_ "GenSigTimeoutTime" BU_SG_REL_ VCM SG_ 958 TD_LghtPlsReqPos12V_Status 600;
BA_REL_ "GenSigFirstTimeoutTime" BU_SG_REL_ VCM SG_ 958 TD_LghtPlsReqBrk12V_Brake 3000;
BA_REL_ "GenSigTimeoutTime" BU_SG_REL_ VCM SG_ 958 TD_LghtPlsReqBrk12V_Brake 600;
BA_REL_ "GenSigFirstTimeoutTime" BU_SG_REL_ VCM SG_ 958 TrailerConnectedType 3000;
BA_REL_ "GenSigTimeoutTime" BU_SG_REL_ VCM SG_ 958 TrailerConnectedType 600;
BA_REL_ "GenSigFirstTimeoutTime" BU_SG_REL_ CCIOM SG_ 958 TrailerConnectedType 3000;
BA_REL_ "GenSigTimeoutTime" BU_SG_REL_ CCIOM SG_ 958 TrailerConnectedType 600;
BA_REL_ "GenSigFirstTimeoutTime" BU_SG_REL_ VCM SG_ 958 ECSManStandbyStatus 3000;
BA_REL_ "GenSigTimeoutTime" BU_SG_REL_ VCM SG_ 958 ECSManStandbyStatus 600;
BA_REL_ "GenSigFirstTimeoutTime" BU_SG_REL_ VCM SG_ 958 TrailerLightsConnected_12V 3000;
BA_REL_ "GenSigTimeoutTime" BU_SG_REL_ VCM SG_ 958 TrailerLightsConnected_12V 600;
BA_REL_ "GenSigFirstTimeoutTime" BU_SG_REL_ VCM SG_ 958 TD_LghtPlsReqDir12V_Left 3000;
BA_REL_ "GenSigTimeoutTime" BU_SG_REL_ VCM SG_ 958 TD_LghtPlsReqDir12V_Left 600;
BA_REL_ "GenSigFirstTimeoutTime" BU_SG_REL_ VCM SG_ 958 TD_LghtPlsReqPos12V_Pos2 3000;
BA_REL_ "GenSigTimeoutTime" BU_SG_REL_ VCM SG_ 958 TD_LghtPlsReqPos12V_Pos2 600;
BA_REL_ "GenSigFirstTimeoutTime" BU_SG_REL_ VCM SG_ 958 TD_LghtPlsReqPos12V_Pos1 3000;
BA_REL_ "GenSigTimeoutTime" BU_SG_REL_ VCM SG_ 958 TD_LghtPlsReqPos12V_Pos1 600;
BA_REL_ "GenSigFirstTimeoutTime" BU_SG_REL_ VCM SG_ 958 ECSPreconForSWDL_NegStatInfo 3000;
BA_REL_ "GenSigTimeoutTime" BU_SG_REL_ VCM SG_ 958 ECSPreconForSWDL_NegStatInfo 600;
BA_REL_ "GenSigFirstTimeoutTime" BU_SG_REL_ VCM SG_ 958 ECSPreconForSWDL_Status 3000;
BA_REL_ "GenSigTimeoutTime" BU_SG_REL_ VCM SG_ 958 ECSPreconForSWDL_Status 600;
BA_REL_ "GenSigFirstTimeoutTime" BU_SG_REL_ VCM SG_ 1517 RearDriveAxle2Temperature 24000;
BA_REL_ "GenSigTimeoutTime" BU_SG_REL_ VCM SG_ 1517 RearDriveAxle2Temperature 6000;
BA_REL_ "GenSigFirstTimeoutTime" BU_SG_REL_ VCM SG_ 1517 RearDriveAxle1Temperature 24000;
BA_REL_ "GenSigTimeoutTime" BU_SG_REL_ VCM SG_ 1517 RearDriveAxle1Temperature 6000;
BA_REL_ "GenSigFirstTimeoutTime" BU_SG_REL_ VCM SG_ 1517 RearDriveAxle3Temperature 24000;
BA_REL_ "GenSigTimeoutTime" BU_SG_REL_ VCM SG_ 1517 RearDriveAxle3Temperature 6000;
BA_REL_ "GenSigFirstTimeoutTime" BU_SG_REL_ VCM SG_ 676 RearAxle3DiffLock_stat 3000;
BA_REL_ "GenSigTimeoutTime" BU_SG_REL_ VCM SG_ 676 RearAxle3DiffLock_stat 500;
BA_REL_ "GenSigFirstTimeoutTime" BU_SG_REL_ VCM SG_ 676 LeftBrakeAndDirInd_cmd 3000;
BA_REL_ "GenSigTimeoutTime" BU_SG_REL_ VCM SG_ 676 LeftBrakeAndDirInd_cmd 120;
BA_REL_ "GenSigFirstTimeoutTime" BU_SG_REL_ VCM SG_ 676 RightBrakeAndDirInd_cmd 3000;
BA_REL_ "GenSigTimeoutTime" BU_SG_REL_ VCM SG_ 676 RightBrakeAndDirInd_cmd 120;
BA_REL_ "GenSigFirstTimeoutTime" BU_SG_REL_ VCM SG_ 676 RevWarning_cmd 3000;
BA_REL_ "GenSigTimeoutTime" BU_SG_REL_ VCM SG_ 676 RevWarning_cmd 500;
BA_REL_ "GenSigFirstTimeoutTime" BU_SG_REL_ VCM SG_ 1349 TertiaryDriveAxleLoad 6000;
BA_REL_ "GenSigTimeoutTime" BU_SG_REL_ VCM SG_ 1349 TertiaryDriveAxleLoad 1500;
BA_REL_ "GenSigFirstTimeoutTime" BU_SG_REL_ VCM SG_ 1349 LastDriveAxleBellowPressure 6000;
BA_REL_ "GenSigTimeoutTime" BU_SG_REL_ VCM SG_ 1349 LastDriveAxleBellowPressure 1500;
BA_REL_ "GenSigFirstTimeoutTime" BU_SG_REL_ VCM SG_ 1349 SuspensionSpeedLimitRequest 6000;
BA_REL_ "GenSigTimeoutTime" BU_SG_REL_ VCM SG_ 1349 SuspensionSpeedLimitRequest 1500;
BA_REL_ "GenSigFirstTimeoutTime" BU_SG_REL_ VCM SG_ 1349 RearAxleGroupLoad 6000;
BA_REL_ "GenSigTimeoutTime" BU_SG_REL_ VCM SG_ 1349 RearAxleGroupLoad 1500;
BA_REL_ "GenSigFirstTimeoutTime" BU_SG_REL_ VCM SG_ 951 DumpSwitchChangeAck 3000;
BA_REL_ "GenSigTimeoutTime" BU_SG_REL_ VCM SG_ 951 DumpSwitchChangeAck 300;
BA_REL_ "GenSigFirstTimeoutTime" BU_SG_REL_ VCM SG_ 951 HeadlightAngleAuto_rqst 3000;
BA_REL_ "GenSigTimeoutTime" BU_SG_REL_ VCM SG_ 951 HeadlightAngleAuto_rqst 300;
BA_REL_ "GenSigFirstTimeoutTime" BU_SG_REL_ VCM SG_ 951 RelativeLevelRearAxleLeftRaw 3000;
BA_REL_ "GenSigTimeoutTime" BU_SG_REL_ VCM SG_ 951 RelativeLevelRearAxleLeftRaw 300;
BA_REL_ "GenSigFirstTimeoutTime" BU_SG_REL_ VCM SG_ 951 FrontDumpFunctionCmd 3000;
BA_REL_ "GenSigTimeoutTime" BU_SG_REL_ VCM SG_ 951 FrontDumpFunctionCmd 300;
BA_REL_ "GenSigFirstTimeoutTime" BU_SG_REL_ CCIOM SG_ 951 FrontDumpFunctionCmd 3000;
BA_REL_ "GenSigTimeoutTime" BU_SG_REL_ CCIOM SG_ 951 FrontDumpFunctionCmd 300;
BA_REL_ "GenSigFirstTimeoutTime" BU_SG_REL_ VCM SG_ 951 RelativeLevelRearAxleRightRaw 3000;
BA_REL_ "GenSigTimeoutTime" BU_SG_REL_ VCM SG_ 951 RelativeLevelRearAxleRightRaw 300;
BA_REL_ "GenSigFirstTimeoutTime" BU_SG_REL_ VCM SG_ 1344 TagAxleLoad 6000;
BA_REL_ "GenSigTimeoutTime" BU_SG_REL_ VCM SG_ 1344 TagAxleLoad 1500;
BA_REL_ "GenSigFirstTimeoutTime" BU_SG_REL_ VCM SG_ 1344 MegaValveUpdateCounter 6000;
BA_REL_ "GenSigTimeoutTime" BU_SG_REL_ VCM SG_ 1344 MegaValveUpdateCounter 1500;
BA_REL_ "GenSigFirstTimeoutTime" BU_SG_REL_ VCM SG_ 1344 RegenInhibitVehicleHeight 6000;
BA_REL_ "GenSigTimeoutTime" BU_SG_REL_ VCM SG_ 1344 RegenInhibitVehicleHeight 1500;
BA_REL_ "GenSigFirstTimeoutTime" BU_SG_REL_ VCM SG_ 1344 RearLeftRoadVibrationIndex 6000;
BA_REL_ "GenSigTimeoutTime" BU_SG_REL_ VCM SG_ 1344 RearLeftRoadVibrationIndex 1500;
BA_REL_ "GenSigFirstTimeoutTime" BU_SG_REL_ VCM SG_ 1344 SavedHeightControlMode 6000;
BA_REL_ "GenSigTimeoutTime" BU_SG_REL_ VCM SG_ 1344 SavedHeightControlMode 1500;
BA_REL_ "GenSigFirstTimeoutTime" BU_SG_REL_ VCM SG_ 1344 PusherAxleLoad 6000;
BA_REL_ "GenSigTimeoutTime" BU_SG_REL_ VCM SG_ 1344 PusherAxleLoad 1500;
VAL_ 1361 Set_EnergySetting 7 "EnergySetting_NotAvailable" 6 "EnergySetting_Error" 5 "EnergySetting_Spare2" 4 "EnergySetting_Spare1" 3 "EnergySetting_Customise" 2 "EnergySetting_PresetLevel2_HighEnergySaving" 1 "EnergySetting_PresetLevel1_EnergySaving" 0 "EnergySetting_OFF" ;
VAL_ 1267 AirIntakeSolenoidValve_cmd 3 "OffOn_NotAvailable" 2 "OffOn_Error" 1 "OffOn_On" 0 "OffOn_Off" ;
VAL_ 1267 KingPinUnlockCmd_Rqst 3 "NotDriven_Driven_NotAvailable" 2 "NotDriven_Driven_Error" 1 "NotDriven_Driven_Driven" 0 "NotDriven_Driven_NotDriven" ;
VAL_ 1267 PreventECSFuncForSWDL_rqst 3 "InactiveActive_NotAvailable" 2 "InactiveActive_Error" 1 "InactiveActive_Active" 0 "InactiveActive_Inactive" ;
VAL_ 1267 AutoShutOffAnswerInput 7 "AutoShutOffAnswerInput_NotAvailable" 6 "AutoShutOffAnswerInput_Error" 5 "AutoShutOffAnswerInput_Spare3" 4 "AutoShutOffAnswerInput_Spare2" 3 "AutoShutOffAnswerInput_Spare1" 2 "AutoShutOffAnswerInput_Delayed" 1 "AutoShutOffAnswerInput_NoAnswer" 0 "AutoShutOffAnswerInput_Accepted" ;
VAL_ 954 DumpSwitchChangeReq 3 "DumpSwitchChangeReq_NotAvailable" 2 "DumpSwitchChangeReq_Error" 1 "DumpSwitchChangeReq_ChangeDumpFunction" 0 "DumpSwitchChangeReq_NoAction" ;
VAL_ 954 CAHighBeamFlash_cmd 3 "CAHighBeamFlash_cmd_NotAvailable" 2 "CAHighBeamFlash_cmd_CrossFlashActive" 1 "CAHighBeamFlash_cmd_SimultaneousFlashActive" 0 "CAHighBeamFlash_cmd_NoFlashActive" ;
VAL_ 954 HeadLampDeicingControl_rqst 3 "InactiveActive_NotAvailable" 2 "InactiveActive_Error" 1 "InactiveActive_Active" 0 "InactiveActive_Inactive" ;
VAL_ 677 EngineStarterMode 15 "EngineStarterMode_NotAvailable" 14 "EngineStarterMode_Error" 13 "EngineStarterMode_NotToBeUsed" 12 "EngineStarterMode_StarterInhibitedReasonUnknown" 11 "EngineStarterMode_Reserved_02" 10 "EngineStarterMode_Reserved_01" 9 "EngineStarterMode_Reserved" 8 "EngineStarterMode_StarterInhibitedDueToStarterOverTemp" 7 "EngineStarterMode_StarterInhibitedDueToActiveImmobilizer" 6 "EngineStarterMode_StarterInhibitedDueToDrivelineEngagedOrOther" 5 "EngineStarterMode_StarterInhibitedDueToEngineNotReadyForStart" 4 "EngineStarterMode_StarterInhibitedDueToEngineAlreadyRunning" 3 "EngineStarterMode_StartFinishedStarterNotActiveAfterHavingBe" 2 "EngineStarterMode_StarterActiveGearEngaged" 1 "EngineStarterMode_StarterActiveGearNotEngaged" 0 "EngineStarterMode_StartNotRequested" ;
VAL_ 1363 PredeliveryModeIndication_cmd 3 "DeactivateActivate_NotAvailable" 2 "DeactivateActivate_Error" 1 "DeactivateActivate_Activate" 0 "DeactivateActivate_Deactivate" ;
VAL_ 535 DirectionIndicatorLightsStatus 15 "DirectionIndicatorLightsStatus_NotAvailable" 14 "DirectionIndicatorLightsStatus_Error" 13 "DirectionIndicatorLightsStatus_Spare7" 12 "DirectionIndicatorLightsStatus_Spare6" 11 "DirectionIndicatorLightsStatus_Spare5" 10 "DirectionIndicatorLightsStatus_Spare4" 9 "DirectionIndicatorLightsStatus_Spare3" 8 "DirectionIndicatorLightsStatus_Spare2" 7 "DirectionIndicatorLightsStatus_Spare1" 6 "DirectionIndicatorLightsStatus_ActiveOtherIndication" 5 "DirectionIndicatorLightsStatus_ActiveHazard" 4 "DirectionIndicatorLightsStatus_ActiveRightAndHazard" 3 "DirectionIndicatorLightsStatus_ActiveLeftAndHazard" 2 "DirectionIndicatorLightsStatus_ActiveRight" 1 "DirectionIndicatorLightsStatus_ActiveLeft" 0 "DirectionIndicatorLightsStatus_NotActive" ;
VAL_ 1381 BattEnergySetLevel_input 7 "BattEnergySetLevel_input_NotAvailable" 6 "BattEnergySetLevel_input_Error" 5 "BattEnergySetLevel_input_Spare" 4 "BattEnergySetLevel_input_Level5" 3 "BattEnergySetLevel_input_Level4" 2 "BattEnergySetLevel_input_Level3" 1 "BattEnergySetLevel_input_Level2" 0 "BattEnergySetLevel_input_Level1" ;
VAL_ 1381 MainBatteryResetPos 15 "MainBatteryResetPos_NotAvailable" 14 "MainBatteryResetPos_Error" 13 "MainBatteryResetPos_NoSelectionMade" 12 "MainBatteryResetPos_Spare09" 11 "MainBatteryResetPos_Spare08" 10 "MainBatteryResetPos_Spare07" 9 "MainBatteryResetPos_Spare06" 8 "MainBatteryResetPos_Spare05" 7 "MainBatteryResetPos_Spare04" 6 "MainBatteryResetPos_Spare03" 5 "MainBatteryResetPos_Spare02" 4 "MainBatteryResetPos_Spare01" 3 "MainBatteryResetPos_3A_and_3B" 2 "MainBatteryResetPos_2A_and_2B" 1 "MainBatteryResetPos_1A_and_1B" 0 "MainBatteryResetPos_AllPosition" ;
VAL_ 519 AdaptiveMainBeamRight_cmd 7 "AdaptiveMainBeam_cmd_NotAvailable" 6 "AdaptiveMainBeam_cmd_Error" 5 "AdaptiveMainBeam_cmd_Spare3" 4 "AdaptiveMainBeam_cmd_Spare2" 3 "AdaptiveMainBeam_cmd_Spare1" 2 "AdaptiveMainBeam_cmd_GlareFreeAllowed" 1 "AdaptiveMainBeam_cmd_MainBeamAllowed" 0 "AdaptiveMainBeam_cmd_MainBeamNotAllowed" ;
VAL_ 519 AdaptiveMainBeamLeft_cmd 7 "AdaptiveMainBeam_cmd_NotAvailable" 6 "AdaptiveMainBeam_cmd_Error" 5 "AdaptiveMainBeam_cmd_Spare3" 4 "AdaptiveMainBeam_cmd_Spare2" 3 "AdaptiveMainBeam_cmd_Spare1" 2 "AdaptiveMainBeam_cmd_GlareFreeAllowed" 1 "AdaptiveMainBeam_cmd_MainBeamAllowed" 0 "AdaptiveMainBeam_cmd_MainBeamNotAllowed" ;
VAL_ 1249 TransferCasePTOEngaged 3 "NotEngagedEngaged_NotAvailable" 2 "NotEngagedEngaged_Error" 1 "NotEngagedEngaged_Engaged" 0 "NotEngagedEngaged_NotEngaged" ;
VAL_ 1249 EhrasTagAxleLoweringInhibit 3 "InhibitStatus_NotAvailable" 2 "InhibitStatus_Reserved" 1 "InhibitStatus_Inhibited" 0 "InhibitStatus_NotInhibited" ;
VAL_ 1249 ExtECSRequestPressureUpdate 3 "Request_NotAvailable" 2 "Request_Error" 1 "Request_RequestActive" 0 "Request_NotRequested" ;
VAL_ 1249 HeadLampFanControl_rqst 3 "InactiveActive_NotAvailable" 2 "InactiveActive_Error" 1 "InactiveActive_Active" 0 "InactiveActive_Inactive" ;
VAL_ 1249 BBAirDumpRequest 3 "InactiveActive_NotAvailable" 2 "InactiveActive_Error" 1 "InactiveActive_Active" 0 "InactiveActive_Inactive" ;
VAL_ 1249 ApproachLight_rqst 3 "InactiveActive_NotAvailable" 2 "InactiveActive_Error" 1 "InactiveActive_Active" 0 "InactiveActive_Inactive" ;
VAL_ 1249 FrAxle2WheelDriveRequest 3 "DisengageEngage_NotAvailable" 2 "DisengageEngage_Error" 1 "DisengageEngage_Engage" 0 "DisengageEngage_Disengage" ;
VAL_ 1249 EhrasPusherAxleLoweringInhibit 3 "InhibitStatus_NotAvailable" 2 "InhibitStatus_Reserved" 1 "InhibitStatus_Inhibited" 0 "InhibitStatus_NotInhibited" ;
VAL_ 1249 LivBatteryChargingStat_rqst 3 "NotRequested_NotAvailable" 2 "NotRequested_Error" 1 "NotRequested_Requested" 0 "NotRequested_NotRequested" ;
VAL_ 1249 ClutchSwitch2Stat 3 "ClutchSwitch_NotAvailable" 2 "ClutchSwitch_Error" 1 "ClutchSwitch_ClutchPedalDepressed" 0 "ClutchSwitch_ClutchPedalReleased" ;
VAL_ 1249 SideMarkersLights_cmd 7 "SideMarkersLights_cmd_NotAvailable" 6 "SideMarkersLights_cmd_Error" 5 "SideMarkersLights_cmd_Spare2" 4 "SideMarkersLights_cmd_Spare1" 3 "SideMarkersLights_cmd_LeftandRightSideMarkersActive" 2 "SideMarkersLights_cmd_RightSideMarkersActive" 1 "SideMarkersLights_cmd_LeftSideMarkersActive" 0 "SideMarkersLights_cmd_Inactive" ;
VAL_ 1249 BBEcsForceStandstillFilterReq 3 "InactiveActive_NotAvailable" 2 "InactiveActive_Error" 1 "InactiveActive_Active" 0 "InactiveActive_Inactive" ;
VAL_ 944 ShortStopHeater_cmd 3 "Request_NotAvailable" 2 "Request_Error" 1 "Request_RequestActive" 0 "Request_NotRequested" ;
VAL_ 944 LoadDistributionRequested 15 "LoadDistributionRequested_NotAvailable" 14 "LoadDistributionRequested_Error" 13 "LoadDistributionRequested_Reserved5" 12 "LoadDistributionRequested_Reserved4" 11 "LoadDistributionRequested_Reserved3" 10 "LoadDistributionRequested_Reserved2" 9 "LoadDistributionRequested_Reserved1" 8 "LoadDistributionRequested_DelpressLoadDistribution" 7 "LoadDistributionRequested_VariableLoadDistribution" 6 "LoadDistributionRequested_AlternativeLoadDistribution" 5 "LoadDistributionRequested_MaximumTraction2" 4 "LoadDistributionRequested_MaximumTraction1" 3 "LoadDistributionRequested_OptimizedTraction" 2 "LoadDistributionRequested_NormalLoadDistribution" 1 "LoadDistributionRequested_DefaultLoadDistribution" 0 "LoadDistributionRequested_NoAction" ;
VAL_ 390 CityHorn_cmd 3 "OffOn_NotAvailable" 2 "OffOn_Error" 1 "OffOn_On" 0 "OffOn_Off" ;
VAL_ 390 BrakeSwitch 3 "BrakeSwitch_NotAvailable" 2 "BrakeSwitch_Error" 1 "BrakeSwitch_BrakePedalDepressed" 0 "BrakeSwitch_BrakePedalReleased" ;
VAL_ 390 LevelRequest_FrontAxle 7 "LevelChangeRequest_NotAvailable" 6 "LevelChangeRequest_ErrorIndicator" 5 "LevelChangeRequest_NotDefined" 4 "LevelChangeRequest_VehicleBodyDownMinimumMovementLowering" 3 "LevelChangeRequest_VehicleBodyUpMinimumMovementLifting" 2 "LevelChangeRequest_VehicleBodyDownLowering" 1 "LevelChangeRequest_VehicleBodyUpLifting" 0 "LevelChangeRequest_TakeNoAction" ;
VAL_ 390 FPBRChangeReq 3 "FPBRChangeReq_NotAvailable" 2 "FPBRChangeReq_Error" 1 "FPBRChangeReq_ChangeFPBRFunction" 0 "FPBRChangeReq_TakeNoAction" ;
VAL_ 390 AuxiliaryHorn_cmd 3 "OffOn_NotAvailable" 2 "OffOn_Error" 1 "OffOn_On" 0 "OffOn_Off" ;
VAL_ 390 LevelRequest_RearAxle 7 "LevelChangeRequest_NotAvailable" 6 "LevelChangeRequest_ErrorIndicator" 5 "LevelChangeRequest_NotDefined" 4 "LevelChangeRequest_VehicleBodyDownMinimumMovementLowering" 3 "LevelChangeRequest_VehicleBodyUpMinimumMovementLifting" 2 "LevelChangeRequest_VehicleBodyDownLowering" 1 "LevelChangeRequest_VehicleBodyUpLifting" 0 "LevelChangeRequest_TakeNoAction" ;
VAL_ 390 LevelRequest_RollRequest 7 "RollRequest_NotAvailable" 6 "RollRequest_Error" 5 "RollRequest_Reserved" 4 "RollRequest_CounterClockwiseShort" 3 "RollRequest_ClockwiseShort" 2 "RollRequest_CounterClockwise" 1 "RollRequest_Clockwise" 0 "RollRequest_Idle" ;
VAL_ 389 FrontWheelDriveRequest 3 "DisengageEngage_NotAvailable" 2 "DisengageEngage_Error" 1 "DisengageEngage_Engage" 0 "DisengageEngage_Disengage" ;
VAL_ 389 KneelingChangeRequest 3 "KneelingChangeRequest_NotAvailable" 2 "KneelingChangeRequest_Error" 1 "KneelingChangeRequest_ChangeKneelFunction" 0 "KneelingChangeRequest_TakeNoAction" ;
VAL_ 826 BBContUnlockCmd 3 "NotDriven_Driven_NotAvailable" 2 "NotDriven_Driven_Error" 1 "NotDriven_Driven_Driven" 0 "NotDriven_Driven_NotDriven" ;
VAL_ 826 LampCheck_cmd 3 "LampCheck_NotAvailable" 2 "LampCheck_Error" 1 "LampCheck_PerformLampCheck" 0 "LampCheck_NoAction" ;
VAL_ 826 LampCheck_rqst 3 "LampCheck_NotAvailable" 2 "LampCheck_Error" 1 "LampCheck_PerformLampCheck" 0 "LampCheck_NoAction" ;
VAL_ 826 BatteryCapacity 15 "BatteryType_NotAvailable" 14 "BatteryType_Error" 13 "BatteryType_NoSelectionMade" 12 "BatteryType_OtherBatteryType" 11 "BatteryType_BatteryType11" 10 "BatteryType_BatteryType10" 9 "BatteryType_BatteryType9" 8 "BatteryType_BatteryType8" 7 "BatteryType_BatteryType7" 6 "BatteryType_BatteryType6" 5 "BatteryType_BatteryType5" 4 "BatteryType_BatteryType4" 3 "BatteryType_BatteryType3" 2 "BatteryType_BatteryType2" 1 "BatteryType_BatteryType1" 0 "BatteryType_BatteryType0" ;
VAL_ 826 AreaInhibit 3 "Inhibit_NotAvailable" 2 "Inhibit_Error" 1 "Inhibit_InhibitActive" 0 "Inhibit_NoInhibit" ;
VAL_ 826 LEDAnimation_cmd 7 "LEDAnimation_cmd_NotAvailable" 6 "LEDAnimation_cmd_Error" 2 "LEDAnimation_cmd_UnlockAnimation" 1 "LEDAnimation_cmd_LockAnimation" 0 "LEDAnimation_cmd_NoAction" ;
VAL_ 826 PloughLampModeStatus 3 "InactiveActive_NotAvailable" 2 "InactiveActive_Error" 1 "InactiveActive_Active" 0 "InactiveActive_Inactive" ;
VAL_ 826 RangeInhibit 3 "Inhibit_NotAvailable" 2 "Inhibit_Error" 1 "Inhibit_InhibitActive" 0 "Inhibit_NoInhibit" ;
VAL_ 826 TrailerBrakeNoEbs_stat 3 "InactiveActive_NotAvailable" 2 "InactiveActive_Error" 1 "InactiveActive_Active" 0 "InactiveActive_Inactive" ;
VAL_ 826 LiftAxle1DirectControl 7 "LiftAxleLiftPositionRequest_NotAvailable" 6 "LiftAxleLiftPositionRequest_Error" 5 "LiftAxleLiftPositionRequest_Reserved_02" 4 "LiftAxleLiftPositionRequest_Reserved_01" 3 "LiftAxleLiftPositionRequest_Reserved" 2 "LiftAxleLiftPositionRequest_Up" 1 "LiftAxleLiftPositionRequest_Down" 0 "LiftAxleLiftPositionRequest_Idle" ;
VAL_ 826 DoorsAjar_stat 7 "DoorsAjar_stat_NotAvailable" 6 "DoorsAjar_stat_Error" 5 "DoorsAjar_stat_Spare" 4 "DoorsAjar_stat_BothDoorsAreOpen" 3 "DoorsAjar_stat_PassengerDoorIsOpen" 2 "DoorsAjar_stat_DriverDoorIsOpen" 1 "DoorsAjar_stat_BothDoorsAreClosed" 0 "DoorsAjar_stat_Idle" ;
VAL_ 826 BlackOutandConvoyMode_rqst 7 "BlackOutandConvoyMode_rqst_NotAvailable" 6 "BlackOutandConvoyMode_rqst_Error" 5 "BlackOutandConvoyMode_rqst_SpareValue_02" 4 "BlackOutandConvoyMode_rqst_SpareValue_01" 3 "BlackOutandConvoyMode_rqst_SpareValue" 2 "BlackOutandConvoyMode_rqst_ConvoyMode" 1 "BlackOutandConvoyMode_rqst_BlackOutMode" 0 "BlackOutandConvoyMode_rqst_NormalMode" ;
VAL_ 826 ECSStandByRequest 7 "ECSStandByRequest_NotAvailable" 6 "ECSStandByRequest_Error" 5 "ECSStandByRequest_Reserved_01" 4 "ECSStandByRequest_Reserved" 3 "ECSStandByRequest_StandbyRequestedWRC" 2 "ECSStandByRequest_StandbyRequestedRCECS" 1 "ECSStandByRequest_Initiate" 0 "ECSStandByRequest_NoRequest" ;
VAL_ 826 ChassisInstepLight_cmd 3 "OffOn_NotAvailable" 2 "OffOn_Error" 1 "OffOn_On" 0 "OffOn_Off" ;
VAL_ 826 BBSlidable5thWheelCmd 3 "NotDriven_Driven_NotAvailable" 2 "NotDriven_Driven_Error" 1 "NotDriven_Driven_Driven" 0 "NotDriven_Driven_NotDriven" ;
VAL_ 826 ParkingBrake_stat 3 "ParkingBrake_stat_NotAvailable" 2 "ParkingBrake_stat_Error" 1 "ParkingBrake_stat_ParkingBrakeActivated" 0 "ParkingBrake_stat_ParkingBrakeReleased" ;
VAL_ 826 MaintBatteryReset 3 "Request_NotAvailable" 2 "Request_Error" 1 "Request_RequestActive" 0 "Request_NotRequested" ;
VAL_ 946 TransferCaseOrSplitboxPTOMode 3 "InactiveActive_NotAvailable" 2 "InactiveActive_Error" 1 "InactiveActive_Active" 0 "InactiveActive_Inactive" ;
VAL_ 946 Pto3Status 3 "InactiveActive_NotAvailable" 2 "InactiveActive_Error" 1 "InactiveActive_Active" 0 "InactiveActive_Inactive" ;
VAL_ 946 RearAxleDiffLockActvnFuncReq 3 "RearAxleDiffLockActvnFuncReq_TakeNoAction" 2 "RearAxleDiffLockActvnFuncReq_Reserved" 1 "RearAxleDiffLockActvnFuncReq_DisengageDifferentialLock" 0 "RearAxleDiffLockActvnFuncReq_EngageDifferentialLock" ;
VAL_ 946 Pto1Status 3 "InactiveActive_NotAvailable" 2 "InactiveActive_Error" 1 "InactiveActive_Active" 0 "InactiveActive_Inactive" ;
VAL_ 946 ReducedLoadMode_stat 3 "ReducedLoadMode_stat_NotAvailable" 2 "ReducedLoadMode_stat_Error" 1 "ReducedLoadMode_stat_ReducedLoadMode" 0 "ReducedLoadMode_stat_NormalMode" ;
VAL_ 946 RearAxleDiffLockActvnDrvrReq 3 "DisengageEngage_NotAvailable" 2 "DisengageEngage_Error" 1 "DisengageEngage_Engage" 0 "DisengageEngage_Disengage" ;
VAL_ 946 Pto2DrivingRequest 3 "OffOn_NotAvailable" 2 "OffOn_Error" 1 "OffOn_On" 0 "OffOn_Off" ;
VAL_ 946 RrInterAxlDiffLockActvnFuncReq 3 "DisengagedEngaged_NotAvailable" 2 "DisengagedEngaged_Error" 1 "DisengagedEngaged_Engaged" 0 "DisengagedEngaged_Disengaged" ;
VAL_ 946 CartridgeChangedDrvrReset_rqst 3 "DisableEnable_NotAvailable" 2 "DisableEnable_Error" 1 "DisableEnable_Enable" 0 "DisableEnable_Disable" ;
VAL_ 946 RrInterAxlDiffLockActvnDrvrReq 3 "DisengageEngage_NotAvailable" 2 "DisengageEngage_Error" 1 "DisengageEngage_Engage" 0 "DisengageEngage_Disengage" ;
VAL_ 946 Pto2Status 3 "InactiveActive_NotAvailable" 2 "InactiveActive_Error" 1 "InactiveActive_Active" 0 "InactiveActive_Inactive" ;
VAL_ 946 Pto4Status 3 "InactiveActive_NotAvailable" 2 "InactiveActive_Error" 1 "InactiveActive_Active" 0 "InactiveActive_Inactive" ;
VAL_ 946 Pto1DrivingRequest 3 "OffOn_NotAvailable" 2 "OffOn_Error" 1 "OffOn_On" 0 "OffOn_Off" ;
VAL_ 945 EcoRollActiveStatus 3 "InactiveActive_NotAvailable" 2 "InactiveActive_Error" 1 "InactiveActive_Active" 0 "InactiveActive_Inactive" ;
VAL_ 928 RrRrItrWhlDiffLckActvnDrvrReq 3 "DisengagedEngaged_NotAvailable" 2 "DisengagedEngaged_Error" 1 "DisengagedEngaged_Engaged" 0 "DisengagedEngaged_Disengaged" ;
VAL_ 928 LiftAxle1Request 15 "AxleLiftRequest_NotAvailable" 14 "AxleLiftRequest_Error" 13 "AxleLiftRequest_Spare7" 12 "AxleLiftRequest_Spare6" 11 "AxleLiftRequest_Spare5" 10 "AxleLiftRequest_Spare4" 9 "AxleLiftRequest_Spare3" 8 "AxleLiftRequest_Spare2" 7 "AxleLiftRequest_Spare1" 6 "AxleLiftRequest_LowerAxleFallbackCondition" 5 "AxleLiftRequest_LiftDenied" 4 "AxleLiftRequest_TransferLoadToLoweredAxle" 3 "AxleLiftRequest_LowerAxle" 2 "AxleLiftRequest_LiftAxle" 1 "AxleLiftRequest_PrepareLiftAxle" 0 "AxleLiftRequest_Idle" ;
VAL_ 928 Rear1ClutchRequest 3 "DisengageEngage_NotAvailable" 2 "DisengageEngage_Error" 1 "DisengageEngage_Engage" 0 "DisengageEngage_Disengage" ;
VAL_ 928 FrontWheelDifflockRequest 3 "DisengageEngage_NotAvailable" 2 "DisengageEngage_Error" 1 "DisengageEngage_Engage" 0 "DisengageEngage_Disengage" ;
VAL_ 537 LiftAxle2LiftPositionRequest 7 "LiftAxleLiftPositionRequest_NotAvailable" 6 "LiftAxleLiftPositionRequest_Error" 5 "LiftAxleLiftPositionRequest_Reserved_02" 4 "LiftAxleLiftPositionRequest_Reserved_01" 3 "LiftAxleLiftPositionRequest_Reserved" 2 "LiftAxleLiftPositionRequest_Up" 1 "LiftAxleLiftPositionRequest_Down" 0 "LiftAxleLiftPositionRequest_Idle" ;
VAL_ 537 LoadDistributionChangeRequest 3 "LoadDistributionChangeRequest_NotAvailable" 2 "LoadDistributionChangeRequest_Error" 1 "LoadDistributionChangeRequest_ChangeLoadDistribution" 0 "LoadDistributionChangeRequest_Idle" ;
VAL_ 537 AltLoadDistribution_rqst 7 "AltLoadDistribution_rqst_NotAvailable" 6 "AltLoadDistribution_rqst_Error" 5 "AltLoadDistribution_rqst_Reserved_3" 4 "AltLoadDistribution_rqst_Reserved_2" 3 "AltLoadDistribution_rqst_Reserved_1" 2 "AltLoadDistribution_rqst_ALDOff" 1 "AltLoadDistribution_rqst_ALDOn" 0 "AltLoadDistribution_rqst_Idle" ;
VAL_ 537 LiftAxle1LiftPositionRequest 7 "LiftAxleLiftPositionRequest_NotAvailable" 6 "LiftAxleLiftPositionRequest_Error" 5 "LiftAxleLiftPositionRequest_Reserved_02" 4 "LiftAxleLiftPositionRequest_Reserved_01" 3 "LiftAxleLiftPositionRequest_Reserved" 2 "LiftAxleLiftPositionRequest_Up" 1 "LiftAxleLiftPositionRequest_Down" 0 "LiftAxleLiftPositionRequest_Idle" ;
VAL_ 537 RampLevelRequest 15 "RampLevelRequest_NotAvailable" 14 "RampLevelRequest_ErrorIndicator" 13 "RampLevelRequest_NotDefined_09" 12 "RampLevelRequest_NotDefined_08" 11 "RampLevelRequest_NotDefined_07" 10 "RampLevelRequest_NotDefined_06" 9 "RampLevelRequest_NotDefined_05" 8 "RampLevelRequest_NotDefined_04" 7 "RampLevelRequest_RampLevelM7" 6 "RampLevelRequest_RampLevelM6" 5 "RampLevelRequest_RampLevelM5" 4 "RampLevelRequest_RampLevelM4" 3 "RampLevelRequest_RampLevelM3" 2 "RampLevelRequest_RampLevelM2" 1 "RampLevelRequest_RampLevelM1" 0 "RampLevelRequest_TakeNoAction" ;
VAL_ 537 RampLevelStorageRequest 15 "RampLevelRequest_NotAvailable" 14 "RampLevelRequest_ErrorIndicator" 13 "RampLevelRequest_NotDefined_09" 12 "RampLevelRequest_NotDefined_08" 11 "RampLevelRequest_NotDefined_07" 10 "RampLevelRequest_NotDefined_06" 9 "RampLevelRequest_NotDefined_05" 8 "RampLevelRequest_NotDefined_04" 7 "RampLevelRequest_RampLevelM7" 6 "RampLevelRequest_RampLevelM6" 5 "RampLevelRequest_RampLevelM5" 4 "RampLevelRequest_RampLevelM4" 3 "RampLevelRequest_RampLevelM3" 2 "RampLevelRequest_RampLevelM2" 1 "RampLevelRequest_RampLevelM1" 0 "RampLevelRequest_TakeNoAction" ;
VAL_ 537 RideHeightFunctionRequest 15 "RideHeightFunction_NotAvailable" 14 "RideHeightFunction_ErrorIndicator" 13 "RideHeightFunction_NotDefined_05" 12 "RideHeightFunction_NotDefined_04" 11 "RideHeightFunction_NotDefined_03" 10 "RideHeightFunction_NotDefined_02" 9 "RideHeightFunction_NotDefined_01" 8 "RideHeightFunction_NotDefined" 7 "RideHeightFunction_AlternativeDrivePosition2" 6 "RideHeightFunction_AlternativeDrivePosition1" 5 "RideHeightFunction_LowDrivePosition" 4 "RideHeightFunction_HighDrivePosition" 3 "RideHeightFunction_SpeedDependentDrivePosition" 2 "RideHeightFunction_AlternativeDrivePosition" 1 "RideHeightFunction_StandardDrivePosition" 0 "RideHeightFunction_Inactive" ;
VAL_ 537 LiftAxle1AutoLiftRequest 3 "InactiveActive_NotAvailable" 2 "InactiveActive_Error" 1 "InactiveActive_Active" 0 "InactiveActive_Inactive" ;
VAL_ 537 FerryFunctionRequest 3 "Request_NotAvailable" 2 "Request_Error" 1 "Request_RequestActive" 0 "Request_NotRequested" ;
VAL_ 537 BBSystemKneelRequest 3 "Request_NotAvailable" 2 "Request_Error" 1 "Request_RequestActive" 0 "Request_NotRequested" ;
VAL_ 537 StopLevelChangeRequest 3 "Request_NotAvailable" 2 "Request_Error" 1 "Request_RequestActive" 0 "Request_NotRequested" ;
VAL_ 537 FirstAxleLowerPrioRequested 7 "FirstAxleLowerPrio_NotAvailable" 6 "FirstAxleLowerPrio_Error" 5 "FirstAxleLowerPrio_Reserved_03" 4 "FirstAxleLowerPrio_Reserved_02" 3 "FirstAxleLowerPrio_Reserved_01" 2 "FirstAxleLowerPrio_Reserved" 1 "FirstAxleLowerPrio_LowerPusher" 0 "FirstAxleLowerPrio_LowerTag" ;
VAL_ 537 LiftAxle2AutoLiftRequest 3 "InactiveActive_NotAvailable" 2 "InactiveActive_Error" 1 "InactiveActive_Active" 0 "InactiveActive_Inactive" ;
VAL_ 537 FerryFunctionSwitchChangeReq 3 "ChangeRequest2Bit_NotAvailable" 2 "ChangeRequest2Bit_Error" 1 "ChangeRequest2Bit_Change" 0 "ChangeRequest2Bit_TakeNoAction" ;
VAL_ 537 LevelStrokeRequest 3 "LevelStrokeRequest_NotAvailable" 2 "LevelStrokeRequest_ErrorIndicator" 1 "LevelStrokeRequest_DriveLevelControlStroke" 0 "LevelStrokeRequest_DockingLevelControlStroke" ;
VAL_ 537 BBSystemProhibitControlRequest 3 "Request_NotAvailable" 2 "Request_Error" 1 "Request_RequestActive" 0 "Request_NotRequested" ;
VAL_ 537 BBSystemAlternatLoadDistribReq 3 "InactiveActive_NotAvailable" 2 "InactiveActive_Error" 1 "InactiveActive_Active" 0 "InactiveActive_Inactive" ;
VAL_ 537 RideHeightStorageRequest 15 "RideHeightStorageRequest_NotAvailable" 14 "RideHeightStorageRequest_ErrorIndicator" 13 "RideHeightStorageRequest_NotDefined_06" 12 "RideHeightStorageRequest_NotDefined_05" 11 "RideHeightStorageRequest_NotDefined_04" 10 "RideHeightStorageRequest_NotDefined_03" 9 "RideHeightStorageRequest_NotDefined_02" 8 "RideHeightStorageRequest_NotDefined_01" 7 "RideHeightStorageRequest_NotDefined" 6 "RideHeightStorageRequest_ResetHighDrivePosition" 5 "RideHeightStorageRequest_ResetLowDrivePosition" 4 "RideHeightStorageRequest_StoreHighDrivePosition" 3 "RideHeightStorageRequest_StoreLowDrivePosition" 2 "RideHeightStorageRequest_StoreStandardUserDrivePosition" 1 "RideHeightStorageRequest_ResetToStoreFactoryDrivePosition" 0 "RideHeightStorageRequest_TakeNoAction" ;
VAL_ 537 BBSystemSpeedDepDriveLevelReq 3 "BBSystemSpeedDepDriveLevelReq_NotAvailable" 2 "BBSystemSpeedDepDriveLevelReq_ErrorIndicator" 1 "BBSystemSpeedDepDriveLevelReq_SpeedDependentDrivePosition" 0 "BBSystemSpeedDepDriveLevelReq_TakeNoAction" ;
VAL_ 531 BackToDriveReq 3 "Requested_NotAvailable" 2 "Requested_Error" 1 "BackToDriveReq_B2DRequested" 0 "BackToDriveReq_Idle" ;
VAL_ 531 FogLight_Front_cmd 3 "InactiveActive_NotAvailable" 2 "InactiveActive_Error" 1 "InactiveActive_Active" 0 "InactiveActive_Inactive" ;
VAL_ 531 SplitBoxDifflockActvnDrvrRqst 3 "DisengageEngage_NotAvailable" 2 "DisengageEngage_Error" 1 "DisengageEngage_Engage" 0 "DisengageEngage_Disengage" ;
VAL_ 531 WS_Washing_cmd 3 "InactiveActive_NotAvailable" 2 "InactiveActive_Error" 1 "InactiveActive_Active" 0 "InactiveActive_Inactive" ;
VAL_ 531 ReverseWarning_rqst 3 "ReverseWarning_rqst_NotAvailable" 2 "ReverseWarning_rqst_Error" 1 "ReverseWarning_rqst_SoundOn" 0 "ReverseWarning_rqst_SoundOff" ;
VAL_ 531 FogLight_Rear_cmd 3 "InactiveActive_NotAvailable" 2 "InactiveActive_Error" 1 "InactiveActive_Active" 0 "InactiveActive_Inactive" ;
VAL_ 531 FrAxleDiffLockActvnDriverRqst 3 "DisengageEngage_NotAvailable" 2 "DisengageEngage_Error" 1 "DisengageEngage_Engage" 0 "DisengageEngage_Disengage" ;
VAL_ 392 MainBeam_cmd 7 "MainBeam_cmd_NotAvailable" 6 "MainBeam_cmd_SpareValue_03" 5 "MainBeam_cmd_SpareValue_02" 4 "MainBeam_cmd_SpareValue_01" 3 "MainBeam_cmd_SpareValue" 2 "MainBeam_cmd_MainBeamFlashOn" 1 "MainBeam_cmd_MainBeamOn" 0 "MainBeam_cmd_MainBeamOff" ;
VAL_ 392 DippedBeam_cmd 3 "InactiveActive_NotAvailable" 2 "InactiveActive_Error" 1 "InactiveActive_Active" 0 "InactiveActive_Inactive" ;
VAL_ 392 ExtraMainBeam_cmd 3 "InactiveActive_NotAvailable" 2 "InactiveActive_Error" 1 "InactiveActive_Active" 0 "InactiveActive_Inactive" ;
VAL_ 392 Hazard_rqst 3 "InactiveActive_NotAvailable" 2 "InactiveActive_Error" 1 "InactiveActive_Active" 0 "InactiveActive_Inactive" ;
VAL_ 392 DirectionIndicatorLights_rqst 7 "DirectionIndicatorLights_rqst_NotAvailable" 6 "DirectionIndicatorLights_rqst_Error" 5 "DirectionIndicatorLights_rqst_SpareValue_02" 4 "DirectionIndicatorLights_rqst_SpareValue_01" 3 "DirectionIndicatorLights_rqst_SpareValue" 2 "DirectionIndicatorLights_rqst_RightDirectionIndicatorActive" 1 "DirectionIndicatorLights_rqst_LeftDirectionIndicatorActive" 0 "DirectionIndicatorLights_rqst_NotActive" ;
VAL_ 392 DRL_cmd 3 "InactiveActive_NotAvailable" 2 "InactiveActive_Error" 1 "InactiveActive_Active" 0 "InactiveActive_Inactive" ;
VAL_ 392 DirectionIndicatorLights_cmd 7 "DirectionIndicatorLights_cmd_NotAvailable" 6 "DirectionIndicatorLights_cmd_SpareValue_02" 5 "DirectionIndicatorLights_cmd_SpareValue_01" 4 "DirectionIndicatorLights_cmd_SpareValue" 3 "DirectionIndicatorLights_cmd_RightAndLeftActiveHazard" 2 "DirectionIndicatorLights_cmd_RightDirectionIndicatorActive" 1 "DirectionIndicatorLights_cmd_LeftDirectionIndicatorActive" 0 "DirectionIndicatorLights_cmd_NotActive" ;
VAL_ 392 PositionLight_cmd 3 "InactiveActive_NotAvailable" 2 "InactiveActive_Error" 1 "InactiveActive_Active" 0 "InactiveActive_Inactive" ;
VAL_ 392 StaticCornerLight_cmd 7 "StaticCornerLight_cmd_NotAvailable" 6 "StaticCornerLight_cmd_SpareValue_02" 5 "StaticCornerLight_cmd_SpareValue_01" 4 "StaticCornerLight_cmd_SpareValue" 3 "StaticCornerLight_cmd_LeftAndRightStaticCornerLightActive" 2 "StaticCornerLight_cmd_LeftStaticCornerLightActive" 1 "StaticCornerLight_cmd_RightStaticCornerLightActive" 0 "StaticCornerLight_cmd_Off" ;
VAL_ 392 WorkingLightChassisOutp_cmd 3 "OffOn_NotAvailable" 2 "OffOn_Error" 1 "OffOn_On" 0 "OffOn_Off" ;
VAL_ 895 ApproachLight_FrontRqst 3 "InactiveActive_NotAvailable" 2 "InactiveActive_Error" 1 "InactiveActive_Active" 0 "InactiveActive_Inactive" ;
VAL_ 895 EASTagLiftAxleLoweringInhibit 3 "InhibitStatus_NotAvailable" 2 "InhibitStatus_Reserved" 1 "InhibitStatus_Inhibited" 0 "InhibitStatus_NotInhibited" ;
VAL_ 895 FrRrItrWhlDiffLckActvnDrvrReq 3 "DisengagedEngaged_NotAvailable" 2 "DisengagedEngaged_Error" 1 "DisengagedEngaged_Engaged" 0 "DisengagedEngaged_Disengaged" ;
VAL_ 895 ApproachLight_RearandSideRqst 3 "InactiveActive_NotAvailable" 2 "InactiveActive_Error" 1 "InactiveActive_Active" 0 "InactiveActive_Inactive" ;
VAL_ 895 ApproachLight_HLAnimationcmd 3 "InactiveActive_NotAvailable" 2 "InactiveActive_Error" 1 "InactiveActive_Active" 0 "InactiveActive_Inactive" ;
VAL_ 895 TransmEngineCrankEnable 3 "DisableEnable_NotAvailable" 2 "DisableEnable_Error" 1 "DisableEnable_Enable" 0 "DisableEnable_Disable" ;
VAL_ 895 TransmEngineCrankEnable2 3 "DisableEnable_NotAvailable" 2 "DisableEnable_Error" 1 "DisableEnable_Enable" 0 "DisableEnable_Disable" ;
VAL_ 588 VehicleMode 15 "VehicleMode_NotAvailable" 14 "VehicleMode_Error" 13 "VehicleMode_Spare_7" 12 "VehicleMode_Spare_6" 11 "VehicleMode_Spare_5" 10 "VehicleMode_Spare_4" 9 "VehicleMode_Spare_3" 8 "VehicleMode_Spare_2" 7 "VehicleMode_Spare_1" 6 "VehicleMode_Running" 5 "VehicleMode_Cranking" 4 "VehicleMode_PreRunning" 3 "VehicleMode_Accessory" 2 "VehicleMode_Living" 1 "VehicleMode_Parked" 0 "VehicleMode_Hibernate" ;
VAL_ 588 TransmissionDrivelineEngaged 3 "DisengageEngage_NotAvailable" 2 "DisengageEngage_Error" 1 "DisengageEngage_Engage" 0 "DisengageEngage_Disengage" ;
VAL_ 588 SecuredNeutralPosition 3 "SecuredNeutralPosition_NotAvailable" 2 "SecuredNeutralPosition_Error" 1 "SecuredNeutralPosition_SecuredNeutralPosition" 0 "SecuredNeutralPosition_NotInSecuredNeutralPosition" ;
VAL_ 588 GearLeverPosition 15 "GearLeverPosition_NotAvailable" 14 "GearLeverPosition_Error" 13 "GearLeverPosition_SpareValue_06" 12 "GearLeverPosition_SpareValue_05" 11 "GearLeverPosition_SpareValue_04" 10 "GearLeverPosition_SpareValue_03" 9 "GearLeverPosition_SpareValue_02" 8 "GearLeverPosition_SpareValue_01" 7 "GearLeverPosition_SpareValue" 6 "GearLeverPosition_SEG6" 5 "GearLeverPosition_LowGear" 4 "GearLeverPosition_Manual" 3 "GearLeverPosition_Automatic" 2 "GearLeverPosition_Neutral" 1 "GearLeverPosition_Reverse" 0 "GearLeverPosition_GearFoldedAway" ;
VAL_ 588 EngineActiveStatus 15 "EngineActiveStatus_NotAvailable" 14 "EngineActiveStatus_Error" 13 "EngineActiveStatus_Spare_10" 12 "EngineActiveStatus_Spare_09" 11 "EngineActiveStatus_Spare_08" 10 "EngineActiveStatus_Spare_07" 9 "EngineActiveStatus_Spare_06" 8 "EngineActiveStatus_Spare_05" 7 "EngineActiveStatus_Spare_04" 6 "EngineActiveStatus_Spare_03" 5 "EngineActiveStatus_Spare_02" 4 "EngineActiveStatus_Spare_01" 3 "EngineActiveStatus_EngineStandby" 2 "EngineActiveStatus_ElectricPropulsionSystemRunning" 1 "EngineActiveStatus_InternalCombustionEngineRunning" 0 "EngineActiveStatus_DrivelineNotActive" ;
VAL_ 957 TrlrDirIndRightOutputStat_12V 7 "LightOutput_NotAvailable" 6 "LightOutput_Error" 5 "LightOutput_OutputActiveStatusUncertain" 4 "LightOutput_OutputActiveLightDetectedOnActivation" 3 "LightOutput_OutputActiveLightDetected" 2 "LightOutput_OutputActiveNoLightDetected" 1 "LightOutput_OutputActiveDetectionOngoing" 0 "LightOutput_OutputInactive" ;
VAL_ 957 TrailerBrakeLightOutputStat12V 7 "LightOutput_NotAvailable" 6 "LightOutput_Error" 5 "LightOutput_OutputActiveStatusUncertain" 4 "LightOutput_OutputActiveLightDetectedOnActivation" 3 "LightOutput_OutputActiveLightDetected" 2 "LightOutput_OutputActiveNoLightDetected" 1 "LightOutput_OutputActiveDetectionOngoing" 0 "LightOutput_OutputInactive" ;
VAL_ 957 TrailerDirIndLightRequested12V 3 "LightsRequested_NotAvailable" 2 "LightsRequested_Error" 1 "LightsRequested_LightsRequested" 0 "LightsRequested_LightNotRequested" ;
VAL_ 957 TD_BrakeLightsPulseRsp_12V 7 "LightDetected_NotAvailable" 6 "LightDetected_Error" 5 "LightDetected_Spare4" 4 "LightDetected_Spare3" 3 "LightDetected_Spare2" 2 "LightDetected_Spare1" 1 "LightDetected_LightDetected" 0 "LightDetected_NoLightDetected" ;
VAL_ 957 TD_DirInLgtPlsRsp_12V_Right 7 "LightDetected_NotAvailable" 6 "LightDetected_Error" 5 "LightDetected_Spare4" 4 "LightDetected_Spare3" 3 "LightDetected_Spare2" 2 "LightDetected_Spare1" 1 "LightDetected_LightDetected" 0 "LightDetected_NoLightDetected" ;
VAL_ 957 TrailerBrakeLightsRequested12V 3 "LightsRequested_NotAvailable" 2 "LightsRequested_Error" 1 "LightsRequested_LightsRequested" 0 "LightsRequested_LightNotRequested" ;
VAL_ 957 TrailerPos2OutputStat_12V 7 "LightOutput_NotAvailable" 6 "LightOutput_Error" 5 "LightOutput_OutputActiveStatusUncertain" 4 "LightOutput_OutputActiveLightDetectedOnActivation" 3 "LightOutput_OutputActiveLightDetected" 2 "LightOutput_OutputActiveNoLightDetected" 1 "LightOutput_OutputActiveDetectionOngoing" 0 "LightOutput_OutputInactive" ;
VAL_ 957 TD_PosLghtPlsRsp12V_Pos2 7 "LightDetected_NotAvailable" 6 "LightDetected_Error" 5 "LightDetected_Spare4" 4 "LightDetected_Spare3" 3 "LightDetected_Spare2" 2 "LightDetected_Spare1" 1 "LightDetected_LightDetected" 0 "LightDetected_NoLightDetected" ;
VAL_ 957 TrailerConnected_12VABSCurrent 3 "TrailerConnected_NotAvailalbe" 2 "TrailerConnected_Error" 1 "TrailerConnected_Trailer_Connected" 0 "TrailerConnected_Trailer_Disconnected" ;
VAL_ 957 TrailerPosLightRequested12V 3 "LightsRequested_NotAvailable" 2 "LightsRequested_Error" 1 "LightsRequested_LightsRequested" 0 "LightsRequested_LightNotRequested" ;
VAL_ 957 TD_PosLghtPlsRsp12V_Pos1 7 "LightDetected_NotAvailable" 6 "LightDetected_Error" 5 "LightDetected_Spare4" 4 "LightDetected_Spare3" 3 "LightDetected_Spare2" 2 "LightDetected_Spare1" 1 "LightDetected_LightDetected" 0 "LightDetected_NoLightDetected" ;
VAL_ 957 TrlrDirIndLeftOutputStat_12V 7 "LightOutput_NotAvailable" 6 "LightOutput_Error" 5 "LightOutput_OutputActiveStatusUncertain" 4 "LightOutput_OutputActiveLightDetectedOnActivation" 3 "LightOutput_OutputActiveLightDetected" 2 "LightOutput_OutputActiveNoLightDetected" 1 "LightOutput_OutputActiveDetectionOngoing" 0 "LightOutput_OutputInactive" ;
VAL_ 957 TrailerPos1OutputStat_12V 7 "LightOutput_NotAvailable" 6 "LightOutput_Error" 5 "LightOutput_OutputActiveStatusUncertain" 4 "LightOutput_OutputActiveLightDetectedOnActivation" 3 "LightOutput_OutputActiveLightDetected" 2 "LightOutput_OutputActiveNoLightDetected" 1 "LightOutput_OutputActiveDetectionOngoing" 0 "LightOutput_OutputInactive" ;
VAL_ 957 TD_DirInLgtPlsRsp_12V_Left 7 "LightDetected_NotAvailable" 6 "LightDetected_Error" 5 "LightDetected_Spare4" 4 "LightDetected_Spare3" 3 "LightDetected_Spare2" 2 "LightDetected_Spare1" 1 "LightDetected_LightDetected" 0 "LightDetected_NoLightDetected" ;
VAL_ 958 TD_LghtPlsReqBrk12V_Status 3 "TD_LightsPulseStatus_NotAvailable" 2 "TD_LightsPulseStatus_Error" 1 "TD_LightsPulseStatus_Spare" 0 "TD_LightsPulseStatus_OK" ;
VAL_ 958 TD_LghtPlsReqDir12V_Right 1 "DetectionLight_SendPulse" 0 "DetectionLight_Inactive" ;
VAL_ 958 TD_LghtPlsReqDir12V_Status 3 "TD_LightsPulseStatus_NotAvailable" 2 "TD_LightsPulseStatus_Error" 1 "TD_LightsPulseStatus_Spare" 0 "TD_LightsPulseStatus_OK" ;
VAL_ 958 TD_LightsResetReq_12V 3 "InactiveResetRequest_NotApplicable" 2 "InactiveResetRequest_Error" 1 "InactiveResetRequest_ResetRequest" 0 "InactiveResetRequest_Inactive" ;
VAL_ 958 TD_LghtPlsReqPos12V_Status 3 "TD_LightsPulseStatus_NotAvailable" 2 "TD_LightsPulseStatus_Error" 1 "TD_LightsPulseStatus_Spare" 0 "TD_LightsPulseStatus_OK" ;
VAL_ 958 TD_LghtPlsReqBrk12V_Brake 1 "DetectionLight_SendPulse" 0 "DetectionLight_Inactive" ;
VAL_ 958 TrailerConnectedType 3 "TrailerConnectedType_NotAvailable" 2 "TrailerConnectedType_Error" 1 "TrailerConnectedType_12V_Trailer" 0 "TrailerConnectedType_24V_Trailer" ;
VAL_ 958 ECSManStandbyStatus 3 "InactiveActive_NotAvailable" 2 "InactiveActive_Error" 1 "InactiveActive_Active" 0 "InactiveActive_Inactive" ;
VAL_ 958 TrailerLightsConnected_12V 3 "NoYes_NotAvailable" 2 "NoYes_Error" 1 "NoYes_Yes" 0 "NoYes_No" ;
VAL_ 958 TD_LghtPlsReqDir12V_Left 1 "DetectionLight_SendPulse" 0 "DetectionLight_Inactive" ;
VAL_ 958 TD_LghtPlsReqPos12V_Pos2 1 "DetectionLight_SendPulse" 0 "DetectionLight_Inactive" ;
VAL_ 958 TD_LghtPlsReqPos12V_Pos1 1 "DetectionLight_SendPulse" 0 "DetectionLight_Inactive" ;
VAL_ 958 ECSPreconForSWDL_NegStatInfo 7 "NegStatInfo_NotAvailable" 6 "NegStatInfo_Error" 5 "NegStatInfo_Spare2" 4 "NegStatInfo_Spare1" 3 "NegStatInfo_BB_SuspensionInhibitActive" 2 "NegStatInfo_KneelingActive" 1 "NegStatInfo_FerryFunctionActive" 0 "NegStatInfo_BB_AirDumpActive" ;
VAL_ 958 ECSPreconForSWDL_Status 3 "FalseTrue_NotAvaiable" 2 "FalseTrue_Error" 1 "FalseTrue_True" 0 "FalseTrue_False" ;
VAL_ 676 RearAxle3DiffLock_stat 3 "OffOn_NotAvailable" 2 "OffOn_Error" 1 "OffOn_On" 0 "OffOn_Off" ;
VAL_ 676 LeftBrakeAndDirInd_cmd 3 "InactiveActive_NotAvailable" 2 "InactiveActive_Error" 1 "InactiveActive_Active" 0 "InactiveActive_Inactive" ;
VAL_ 676 RightBrakeAndDirInd_cmd 3 "InactiveActive_NotAvailable" 2 "InactiveActive_Error" 1 "InactiveActive_Active" 0 "InactiveActive_Inactive" ;
VAL_ 676 RevWarning_cmd 3 "RevWarning_cmd_NotAvailable" 2 "RevWarning_cmd_SpareValue" 1 "RevWarning_cmd_WarningSoundOn" 0 "RevWarning_cmd_WarningSoundOff" ;
VAL_ 951 DumpSwitchChangeAck 3 "DumpSwitchChangeAck_NotAvailable" 2 "DumpSwitchChangeAck_Error" 1 "DumpSwitchChangeAck_ChangeAcknowledged" 0 "DumpSwitchChangeAck_NoAction" ;
VAL_ 951 FrontDumpFunctionCmd 7 "DumpFunctionCmd_NotAvailable" 6 "DumpFunctionCmd_Error" 5 "DumpFunctionCmd_Spare3" 4 "DumpFunctionCmd_Spare2" 3 "DumpFunctionCmd_Idle" 2 "DumpFunctionCmd_PressureUpdating" 1 "DumpFunctionCmd_Active" 0 "DumpFunctionCmd_Inactive" ;
VAL_ 1344 RegenInhibitVehicleHeight 3 "ActiveStatus_NotAvailable" 2 "ActiveStatus_Error" 1 "ActiveStatus_Active" 0 "ActiveStatus_NotActive" ;
VAL_ 1344 SavedHeightControlMode 3 "SavedHeightControlMode_NotAvailable" 2 "SavedHeightControlMode_Error" 1 "SavedHeightControlMode_Drive" 0 "SavedHeightControlMode_Manual" ;
SIG_GROUP_ 1267 KingPinUnlockCmd_sg 1 : KingPinUnlockCmd_CRC KingPinUnlockCmd_SqC KingPinUnlockCmd_Rqst;
SIG_GROUP_ 519 GlareFreeArea02_sg 1 : GlareFreeArea02_LeftAngle GlareFreeArea02_Distance GlareFreeArea02_RightAngle;
SIG_GROUP_ 518 GlareFreeArea01_sg 1 : GlareFreeArea01_Distance GlareFreeArea01_LeftAngle GlareFreeArea01_RightAngle;
SIG_GROUP_ 518 GlareFreeArea03_sg 1 : GlareFreeArea03_Distance GlareFreeArea03_RightAngle GlareFreeArea03_LeftAngle;
SIG_GROUP_ 390 LevelRequest_sg 1 : LevelRequest_FrontAxle LevelRequest_RearAxle LevelRequest_RollRequest;
SIG_GROUP_ 957 TD_PosLghtPlsRsp12V_sg 1 : TD_PosLghtPlsRsp12V_Pos2 TD_PosLghtPlsRsp12V_Pos1;
SIG_GROUP_ 957 TD_DirInLgtPlsRsp_12V_sg 1 : TD_DirInLgtPlsRsp_12V_Right TD_DirInLgtPlsRsp_12V_Left;
SIG_GROUP_ 958 ECSPreconForSWDL_sg 1 : ECSPreconForSWDL_NegStatInfo ECSPreconForSWDL_Status;
SIG_GROUP_ 958 TD_LghtPlsReqPos12V_sg 1 : TD_LghtPlsReqPos12V_Status TD_LghtPlsReqPos12V_Pos2 TD_LghtPlsReqPos12V_Pos1;
SIG_GROUP_ 958 TD_LghtPlsReqBrk12V_sg 1 : TD_LghtPlsReqBrk12V_Status TD_LghtPlsReqBrk12V_Brake;
SIG_GROUP_ 958 TD_LghtPlsReqDir12V_sg 1 : TD_LghtPlsReqDir12V_Right TD_LghtPlsReqDir12V_Status TD_LghtPlsReqDir12V_Left;
